VERSION ""

NS_ :

BS_:

BU_: TM

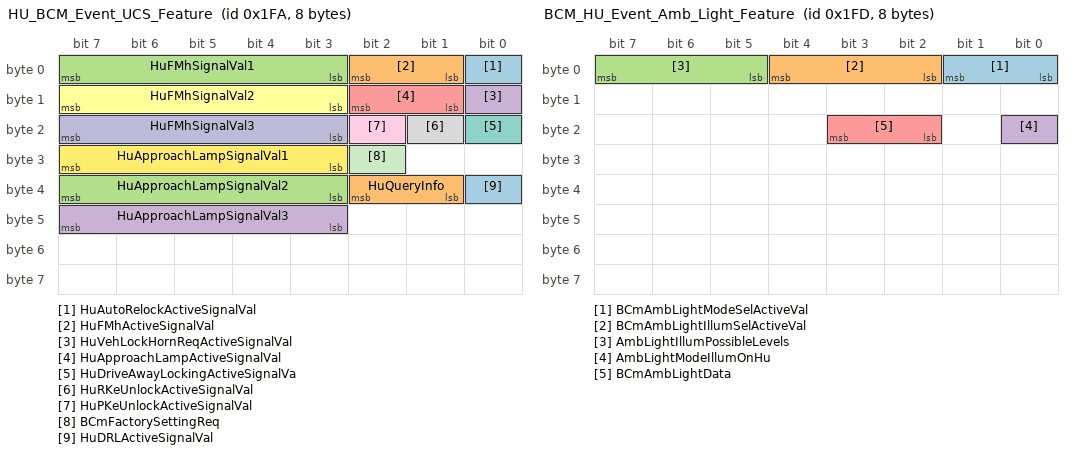
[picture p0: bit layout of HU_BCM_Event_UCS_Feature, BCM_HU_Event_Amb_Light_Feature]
BO_ 506 HU_BCM_Event_UCS_Feature: 8 Vector__XXX
 SG_ HuAutoRelockActiveSignalVal : 0|1@0+ (1,0) [0|1] ""  TM
 SG_ HuFMhActiveSignalVal : 2|2@0+ (1,0) [0|3] ""  TM
 SG_ HuFMhSignalVal1 : 7|5@0+ (10,0) [0|310] "Sec"  TM
 SG_ HuVehLockHornReqActiveSignalVal : 8|1@0+ (1,0) [0|1] ""  TM
 SG_ HuApproachLampActiveSignalVal : 10|2@0+ (1,0) [0|3] ""  TM
 SG_ HuFMhSignalVal2 : 15|5@0+ (10,0) [0|310] "Sec"  TM
 SG_ HuDriveAwayLockingActiveSignalVa : 16|1@0+ (1,0) [0|1] ""  TM
 SG_ HuRKeUnlockActiveSignalVal : 17|1@0+ (1,0) [0|1] ""  TM
 SG_ HuPKeUnlockActiveSignalVal : 18|1@0+ (1,0) [0|1] ""  TM
 SG_ HuFMhSignalVal3 : 23|5@0+ (10,0) [0|310] "Sec"  TM
 SG_ BCmFactorySettingReq : 26|1@0+ (1,0) [0|1] ""  TM
 SG_ HuApproachLampSignalVal1 : 31|5@0+ (10,0) [0|310] "Sec"  TM
 SG_ HuDRLActiveSignalVal : 32|1@0+ (1,0) [0|1] ""  TM
 SG_ HuQueryInfo : 34|2@0+ (1,0) [0|3] ""  TM
 SG_ HuApproachLampSignalVal2 : 39|5@0+ (10,0) [0|310] "Sec"  TM
 SG_ HuApproachLampSignalVal3 : 47|5@0+ (10,0) [0|310] "Sec"  TM

BO_ 508 HU_BCM_Event_Mood_Light_Feature: 8 Vector__XXX
 SG_ HuMoodLightAllAreaActiveValue : 0|1@0+ (1,0) [0|1] ""  TM
 SG_ HuMoodLightIllumSelActiveValue : 3|3@0+ (1,0) [0|7] ""  TM
 SG_ HuMoodLightActiveColourValue : 7|4@0+ (1,0) [0|15] ""  TM
 SG_ HuMoodLightRearAreaActiveValue : 8|1@0+ (1,0) [0|1] ""  TM
 SG_ HuMoodLightFrontRHAreaActiveValu : 9|1@0+ (1,0) [0|1] ""  TM
 SG_ HuMoodLightFloorConsoleAreaActiv : 10|1@0+ (1,0) [0|1] ""  TM
 SG_ HuMoodLightData : 12|2@0+ (1,0) [0|3] ""  TM
 SG_ HuMoodLightIllumPossibleLevels : 15|3@0+ (1,0) [0|7] ""  TM
 SG_ HuMoodLightHotMagentaColorSelOnH : 16|1@0+ (1,0) [0|1] ""  TM
 SG_ HuMoodLightGoldYellowColorSelOnH : 17|1@0+ (1,0) [0|1] ""  TM
 SG_ HuMoodLightFrenchLimeColorSelOnH : 18|1@0+ (1,0) [0|1] ""  TM
 SG_ HuMoodLightFrontLHAreaActiveValu : 19|1@0+ (1,0) [0|1] ""  TM
 SG_ HuMoodLightPossibleModes : 21|2@0+ (1,0) [0|3] ""  TM
 SG_ HuMoodLightActiveModeValue : 23|2@0+ (1,0) [0|3] ""  TM
 SG_ HuMoodLightPolarBrightWhiteColor : 24|1@0+ (1,0) [0|1] ""  TM
 SG_ HuMoodLightAeroBlueColorSelOnHU : 25|1@0+ (1,0) [0|1] ""  TM
 SG_ HuMoodLightPurpleColorSelOnHU : 26|1@0+ (1,0) [0|1] ""  TM
 SG_ HuMoodLightFluorescentGreenColor : 27|1@0+ (1,0) [0|1] ""  TM
 SG_ HuMoodLightCyanBlueColorSelOnHU : 28|1@0+ (1,0) [0|1] ""  TM
 SG_ HuMoodLightCoolBlueColorSelOnHU : 29|1@0+ (1,0) [0|1] ""  TM
 SG_ HuMoodLightIvoryOFFWhiteColorSel : 30|1@0+ (1,0) [0|1] ""  TM
 SG_ HuMoodLightIceBlueColorSelOnHU : 31|1@0+ (1,0) [0|1] ""  TM
 SG_ HuMoodLightTuscanRedColorSelOnHU : 32|1@0+ (1,0) [0|1] ""  TM
 SG_ HuMoodLightTealGreenColorSelOnHU : 33|1@0+ (1,0) [0|1] ""  TM
 SG_ HuMoodLightRubyRedColorSelOnHU : 34|1@0+ (1,0) [0|1] ""  TM
 SG_ HuMoodLightOrangeColorSelOnHU : 35|1@0+ (1,0) [0|1] ""  TM
 SG_ HuMoodLightPurpleTaupeSelOnHU : 36|1@0+ (1,0) [0|1] ""  TM

BO_ 509 BCM_HU_Event_Amb_Light_Feature: 8 Vector__XXX
 SG_ BCmAmbLightModeSelActiveVal : 1|2@0+ (1,0) [0|3] ""  TM
 SG_ BCmAmbLightIllumSelActiveVal : 4|3@0+ (1,0) [0|7] ""  TM
 SG_ AmbLightIllumPossibleLevels : 7|3@0+ (1,0) [0|7] ""  TM
 SG_ AmbLightModeIllumOnHu : 16|1@0+ (1,0) [0|1] ""  TM
 SG_ BCmAmbLightData : 19|2@0+ (1,0) [0|3] ""  TM

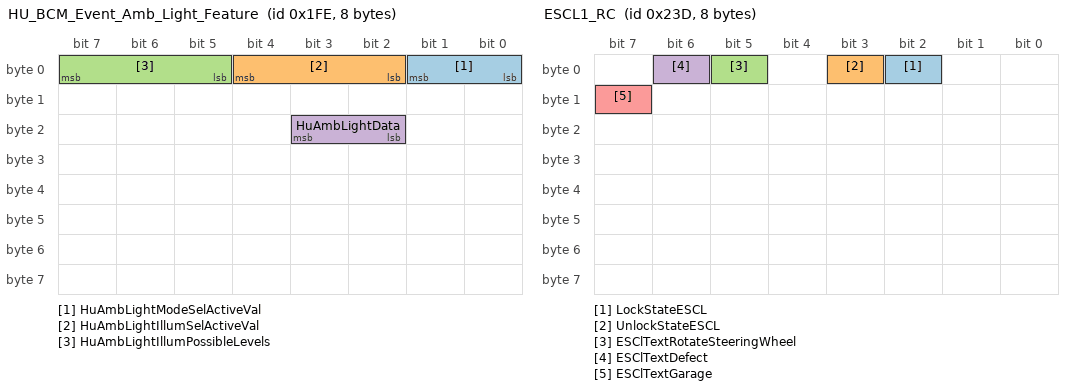
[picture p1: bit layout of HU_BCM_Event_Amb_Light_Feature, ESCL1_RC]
BO_ 510 HU_BCM_Event_Amb_Light_Feature: 8 Vector__XXX
 SG_ HuAmbLightModeSelActiveVal : 1|2@0+ (1,0) [0|3] ""  TM
 SG_ HuAmbLightIllumSelActiveVal : 4|3@0+ (1,0) [0|7] ""  TM
 SG_ HuAmbLightIllumPossibleLevels : 7|3@0+ (1,0) [0|7] ""  TM
 SG_ HuAmbLightData : 19|2@0+ (1,0) [0|3] ""  TM

BO_ 571 CCM_HU_Info: 8 Vector__XXX
 SG_ ColorThemeAutolearning : 54|1@0+ (1,0) [0|1] ""  TM
 SG_ ColorThemeCoDrvr : 50|3@0+ (1,0) [0|7] ""  TM
 SG_ ColorThemeDrvr : 53|3@0+ (1,0) [0|7] ""  TM
 SG_ CcmHuRearBlwrOnOffState : 56|1@0+ (1,0) [0|1] ""  TM
 SG_ CcmHuUserInterventionBeep : 62|1@0+ (1,0) [0|1] ""  TM
 SG_ AutoDefogState : 40|2@0+ (1,0) [0|3] ""  TM
 SG_ AutoDefogFeature : 32|1@0+ (1,0) [0|1] ""  TM
 SG_ CCmExpressCoolVoiceAlert : 61|3@0+ (1,0) [0|7] ""  TM
 SG_ CCmHuExpressCoolSwitchStatus : 63|1@0+ (1,0) [0|1] ""  TM
 SG_ CCmWindowUpDown : 58|2@0+ (1,0) [0|3] ""  TM
 SG_ CCmHuFanSpdStatus : 3|4@0+ (1,0) [0|15] ""  TM
 SG_ CCmHuDistribSwitchStatus : 6|3@0+ (1,0) [0|7] ""  TM
 SG_ CCmHuDualModeSwStatus : 7|1@0+ (1,0) [0|1] ""  TM
 SG_ CCmHuTempWhlStatusPass : 12|5@0+ (0.5,0) [0|31] "Deg C"  TM
 SG_ CCMHuFreshAirRecircSwitchStatus : 14|2@0+ (1,0) [0|3] ""  TM
 SG_ CCmHuAutoSwitchStatus : 15|1@0+ (1,0) [0|1] ""  TM
 SG_ CCmHuTempWhlStatus : 20|5@0+ (0.5,0) [0|31] "Deg C"  TM
 SG_ CCmHuEconModeSwitchStatus : 21|1@0+ (1,0) [0|1] ""  TM
 SG_ CCmHuMaxDefrstSwitchStatus : 22|1@0+ (1,0) [0|1] ""  TM
 SG_ CCmHuRearDefogSwitchStatus : 23|1@0+ (1,0) [0|1] ""  TM
 SG_ CCmHuTempWhlStatusDrvr : 28|5@0+ (0.5,0) [0|31] "Deg  C"  TM
 SG_ CCmHuAirConCompSwitchStatus : 29|1@0+ (1,0) [0|1] ""  TM
 SG_ CCmHuCtrlPnlStatus : 30|1@0+ (1,0) [0|1] ""  TM
 SG_ CCmHuChangeBit : 31|1@0+ (1,0) [0|1] ""  TM
 SG_ CCmHuUserInterventionStatusFlag : 37|5@0+ (1,0) [0|31] ""  TM
 SG_ CCmHuTempWhlStatusStatus : 39|2@0+ (1,0) [0|3] ""  TM
 SG_ CCmHuErrStatus : 41|1@0+ (1,0) [0|1] ""  TM
 SG_ CCmHuDualModeSwStatusStatus : 43|2@0+ (1,0) [0|3] ""  TM
 SG_ CCmHuTempWhlStatusPassStatus : 45|2@0+ (1,0) [0|3] ""  TM
 SG_ CCmHuTempWhlStatusDrvrStatus : 47|2@0+ (1,0) [0|3] ""  TM

BO_ 573 ESCL1_RC: 8 Vector__XXX
 SG_ LockStateESCL : 2|1@0+ (1,0) [0|1] ""  TM
 SG_ UnlockStateESCL : 3|1@0+ (1,0) [0|1] ""  TM
 SG_ ESClTextRotateSteeringWheel : 5|1@0+ (1,0) [0|1] ""  TM
 SG_ ESClTextDefect : 6|1@0+ (1,0) [0|1] ""  TM
 SG_ ESClTextGarage : 15|1@0+ (1,0) [0|1] ""  TM

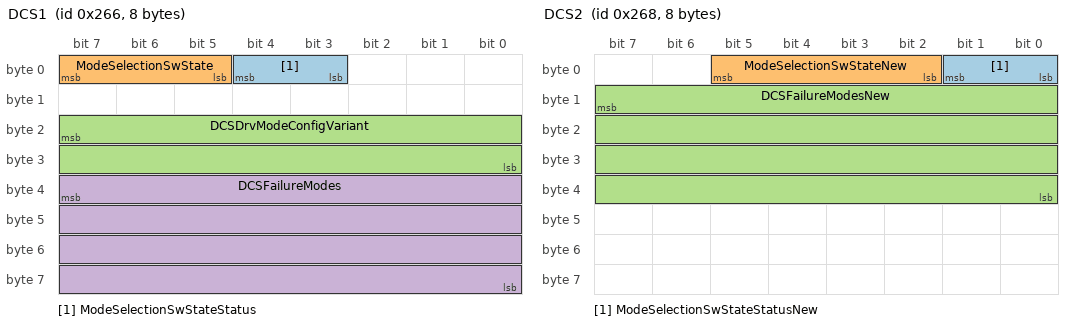
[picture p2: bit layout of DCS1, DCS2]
BO_ 614 DCS1: 8 Vector__XXX
 SG_ ModeSelectionSwStateStatus : 4|2@0+ (1,0) [0|3] ""  TM
 SG_ ModeSelectionSwState : 7|3@0+ (1,0) [0|7] ""  TM
 SG_ DCSDrvModeConfigVariant : 23|16@0+ (1,0) [0|65535] ""  TM
 SG_ DCSFailureModes : 39|32@0+ (1,0) [0|4294967295] ""  TM

BO_ 616 DCS2: 8 Vector__XXX
 SG_ ModeSelectionSwStateStatusNew : 1|2@0+ (1,0) [0|3] ""  TM
 SG_ ModeSelectionSwStateNew : 5|4@0+ (1,0) [0|15] ""  TM
 SG_ DCSFailureModesNew : 15|32@0- (1,0) [0|4294967295] ""  TM

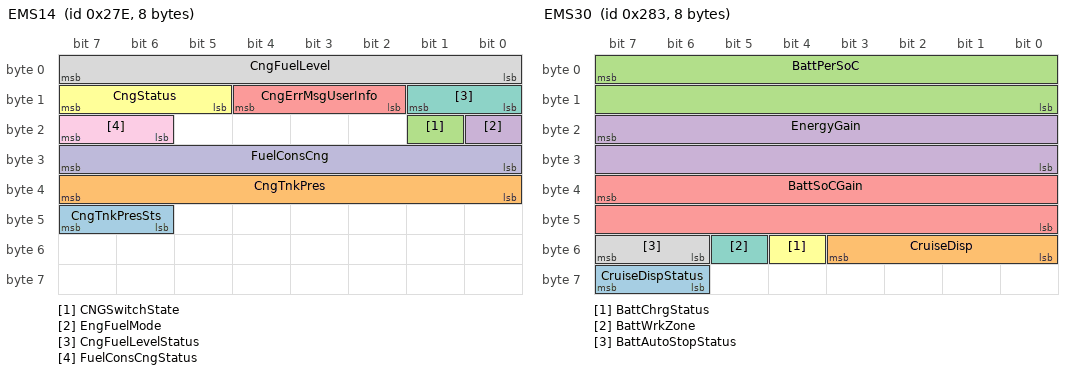
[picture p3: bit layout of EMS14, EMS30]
BO_ 638 EMS14: 8 Vector__XXX
 SG_ CngTnkPresSts : 47|2@0+ (1,0) [0|3] ""  TM
 SG_ CngTnkPres : 39|8@0+ (1,0) [0|250] "bar"  TM
 SG_ CNGSwitchState : 17|1@0+ (1,0) [0|1] ""  TM
 SG_ EngFuelMode : 16|1@0+ (1,0) [0|1] ""  TM
 SG_ CngErrMsgUserInfo : 12|3@0+ (1,0) [0|7] ""  TM
 SG_ CngStatus : 15|3@0+ (1,0) [0|7] ""  TM
 SG_ CngFuelLevelStatus : 9|2@0+ (1,0) [0|3] ""  TM
 SG_ CngFuelLevel : 7|8@0+ (100,0) [0|25500] "gm"  TM
 SG_ FuelConsCngStatus : 23|2@0+ (1,0) [0|3] ""  TM
 SG_ FuelConsCng : 31|8@0+ (100,0) [0|25500] "mg/100ms"  TM

BO_ 640 EMS2: 8 Vector__XXX
 SG_ EngCrsCntrlModeNew : 39|4@0+ (1,0) [0|15] ""  TM
 SG_ EngSpd_EMS : 7|14@0+ (1,0) [0|16383] "rpm"  TM
 SG_ EngSpd_EMS_Status : 9|2@0+ (1,0) [0|3] ""  TM
 SG_ FuelCons : 23|8@0+ (78.8519,0) [0|20107.2345] "mm^3/100ms"  TM
 SG_ ClntTemp : 31|8@0+ (1,-40) [-40|215] "deg"  TM
 SG_ EngineOilPrLamp : 33|2@0+ (1,0) [0|3] ""  TM
 SG_ FilterClLamp : 35|2@0+ (1,0) [0|3] ""  TM
 SG_ BattChrgLampStatus : 41|2@0+ (1,0) [0|3] ""  TM
 SG_ ClntTempStatus : 43|2@0+ (1,0) [0|3] ""  TM
 SG_ GlowPlugLampState : 45|2@0+ (1,0) [0|3] ""  TM
 SG_ EngineOilPrLampStatus : 47|2@0+ (1,0) [0|3] ""  TM
 SG_ WIfLampState : 49|2@0+ (1,0) [0|3] ""  TM
 SG_ ECmBackdoormode : 51|2@0+ (1,0) [0|3] ""  TM
 SG_ FuelConsStatus : 53|2@0+ (1,0) [0|3] ""  TM
 SG_ BattChrgLampState : 55|2@0+ (1,0) [0|3] ""  TM
 SG_ DPfState : 58|2@0+ (1,0) [0|3] ""  TM
 SG_ ClntTempHigh : 60|2@0+ (1,0) [0|3] ""  TM
 SG_ ImmoStatus : 61|1@0+ (1,0) [0|1] ""  TM
 SG_ MiLampState : 63|2@0+ (1,0) [0|3] ""  TM

BO_ 643 EMS30: 8 Vector__XXX
 SG_ CruiseDispStatus : 63|2@0+ (1,0) [0|3] ""  TM
 SG_ CruiseDisp : 51|4@0+ (1,0) [0|15] ""  TM
 SG_ BattPerSoC : 7|16@0+ (0.1,0) [0|150] "%"  TM
 SG_ EnergyGain : 23|16@0+ (0.1,-1000) [-1000|1000] "kW/h"  TM
 SG_ BattSoCGain : 39|16@0+ (0.1,0) [0|150] "%"  TM
 SG_ BattChrgStatus : 52|1@0+ (1,0) [0|1] ""  TM
 SG_ BattWrkZone : 53|1@0+ (1,0) [0|1] ""  TM
 SG_ BattAutoStopStatus : 55|2@0+ (1,0) [0|3] ""  TM

BO_ 644 EMS4: 8 Vector__XXX
 SG_ AcCmprPr : 7|12@0+ (1,0) [0|3570] "kPa"  TM
 SG_ AcCmprOverPrStatus : 9|2@0+ (1,0) [0|3] ""  TM
 SG_ AcCmprPrStatus : 11|2@0+ (1,0) [0|3] ""  TM
 SG_ EngEmission : 18|3@0+ (1,0) [0|7] ""  TM
 SG_ TxmnVariant : 20|2@0+ (1,0) [0|3] ""  TM
 SG_ AcCmprStatus : 21|1@0+ (1,0) [0|1] ""  TM
 SG_ RadFanStatus : 22|1@0+ (1,0) [0|1] ""  TM
 SG_ AcCmprOverPrActive : 23|1@0+ (1,0) [0|1] ""  TM
 SG_ EMSInitDrvModeConfig : 26|3@0+ (1,0) [0|7] ""  TM
 SG_ BattVoltEMsStatus : 28|2@0+ (1,0) [0|3] ""  TM
 SG_ EngLimpHomeMode : 31|3@0+ (1,0) [0|7] ""  TM
 SG_ BattVoltEMS : 39|8@0+ (0.1,0) [0|25.5] "Volts"  TM
 SG_ AtmospPrStatus : 41|2@0+ (1,0) [0|3] ""  TM
 SG_ AcCmprUnderPrActive : 42|1@0+ (1,0) [0|1] ""  TM
 SG_ AcCmprUnderPrStatus : 44|2@0+ (1,0) [0|3] ""  TM
 SG_ EngVariant : 46|2@0+ (1,0) [0|3] ""  TM
 SG_ AtmospPr : 55|8@0+ (2,0) [0|510] "kpa"  TM
 SG_ ModeChangeTxtEMS : 57|2@0+ (1,0) [0|3] ""  TM
 SG_ EngCrsCntrlMode : 60|3@0+ (1,0) [0|7] ""  TM

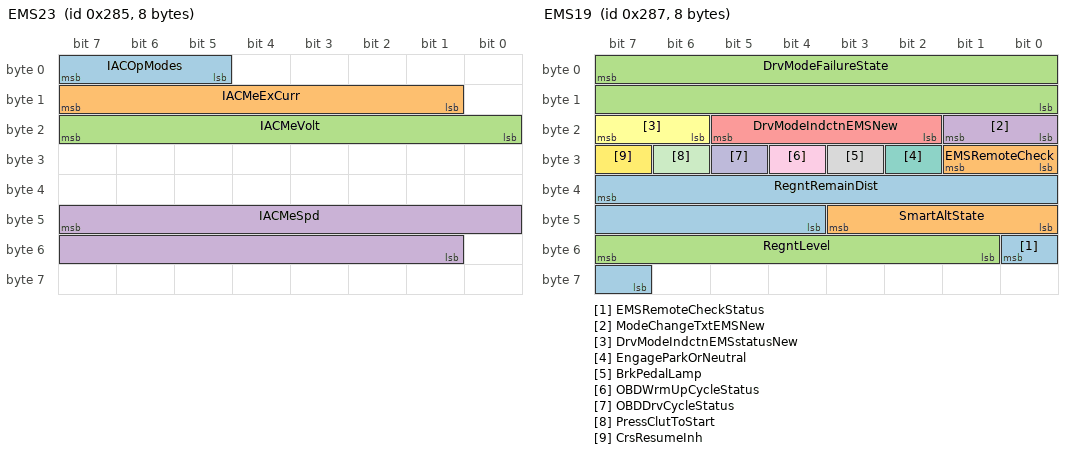
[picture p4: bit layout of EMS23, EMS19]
BO_ 645 EMS23: 8 Vector__XXX
 SG_ IACOpModes : 7|3@0+ (1,0) [0|7] ""  TM
 SG_ IACMeExCurr : 15|7@0+ (0.1,0) [0|12.7] "A"  TM
 SG_ IACMeVolt : 23|8@0+ (0.1,0) [0|25.5] "Volt"  TM
 SG_ IACMeSpd : 47|15@0+ (1,0) [0|32767] "rpm"  TM

BO_ 646 EMS5: 8 Vector__XXX
 SG_ UserSpdLim : 7|8@0+ (1,0) [0|255] "km/h"  TM
 SG_ UserSpdLimLamp : 8|1@0+ (1,0) [0|1] ""  TM
 SG_ UserSpdLimFault : 10|2@0+ (1,0) [0|3] ""  TM
 SG_ UserSpdLimStatus : 12|2@0+ (1,0) [0|3] ""  TM
 SG_ EngStatus : 15|3@0+ (1,0) [0|7] ""  TM
 SG_ CeLampState : 18|2@0+ (1,0) [0|3] ""  TM
 SG_ StaterProhibitionDelay : 19|1@0+ (1,0) [0|1] ""  TM
 SG_ StarterControlState : 21|2@0+ (1,0) [0|3] ""  TM
 SG_ UserSpdLimState : 23|2@0+ (1,0) [0|3] ""  TM
 SG_ SFCActiveEMS : 25|2@0+ (1,0) [0|3] ""  TM
 SG_ DrvModeIndctnEMSstatus : 27|2@0+ (1,0) [0|3] ""  TM
 SG_ CruiseSpdLamp : 29|2@0+ (1,0) [0|3] ""  TM
 SG_ StarterControlStatus : 31|2@0+ (1,0) [0|3] ""  TM
 SG_ CurrGearEms : 35|4@0+ (1,0) [0|15] ""  TM
 SG_ CruiseSpdFault : 37|2@0+ (1,0) [0|3] ""  TM
 SG_ CruiseSpdStatus : 39|2@0+ (1,0) [0|3] ""  TM
 SG_ CruiseSpd : 47|8@0+ (1,0) [0|255] "Km/h"  TM
 SG_ CurrGearEmsStatus : 50|2@0+ (1,0) [0|3] ""  TM
 SG_ GearShiftIndctnEmsStatus : 52|2@0+ (1,0) [0|3] ""  TM
 SG_ GearShiftIndctnEms : 55|3@0+ (1,0) [0|7] ""  TM
 SG_ CruiseSwitchstate : 57|2@0+ (1,0) [0|3] ""  TM
 SG_ CruiseSwitchstateStatus : 59|2@0+ (1,0) [0|3] ""  TM
 SG_ DrvModeIndctnEMS : 63|4@0+ (1,0) [0|15] ""  TM

BO_ 647 EMS19: 8 Vector__XXX
 SG_ EMSRemoteCheckStatus : 48|2@0+ (1,0) [0|3] ""  TM
 SG_ EMSRemoteCheck : 25|2@0+ (1,0) [0|3] ""  TM
 SG_ DrvModeFailureState : 7|16@0+ (1,0) [0|32768] ""  TM
 SG_ ModeChangeTxtEMSNew : 17|2@0+ (1,0) [0|3] ""  TM
 SG_ DrvModeIndctnEMSNew : 21|4@0+ (1,0) [0|15] ""  TM
 SG_ DrvModeIndctnEMSstatusNew : 23|2@0+ (1,0) [0|3] ""  TM
 SG_ EngageParkOrNeutral : 26|1@0+ (1,0) [0|1] ""  TM
 SG_ BrkPedalLamp : 27|1@0+ (1,0) [0|1] ""  TM
 SG_ OBDWrmUpCycleStatus : 28|1@0+ (1,0) [0|1] ""  TM
 SG_ OBDDrvCycleStatus : 29|1@0+ (1,0) [0|1] ""  TM
 SG_ PressClutToStart : 30|1@0+ (1,0) [0|1] ""  TM
 SG_ CrsResumeInh : 31|1@0+ (1,0) [0|1] ""  TM
 SG_ RegntRemainDist : 39|12@0+ (1,0) [0|4095] ""  TM
 SG_ SmartAltState : 43|4@0+ (1,0) [0|15] ""  TM
 SG_ RegntLevel : 55|7@0+ (1,0) [0|100] "%"  TM

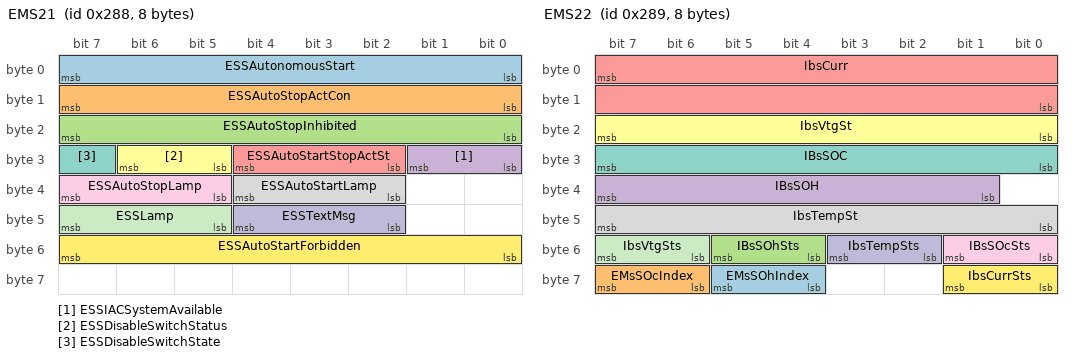
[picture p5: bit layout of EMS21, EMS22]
BO_ 648 EMS21: 8 Vector__XXX
 SG_ ESSAutonomousStart : 7|8@0+ (1,0) [0|255] ""  TM
 SG_ ESSAutoStopActCon : 15|8@0+ (1,0) [0|255] ""  TM
 SG_ ESSAutoStopInhibited : 23|8@0+ (1,0) [0|255] ""  TM
 SG_ ESSIACSystemAvailable : 25|2@0+ (1,0) [0|3] ""  TM
 SG_ ESSAutoStartStopActSt : 28|3@0+ (1,0) [0|7] ""  TM
 SG_ ESSDisableSwitchStatus : 30|2@0+ (1,0) [0|3] ""  TM
 SG_ ESSDisableSwitchState : 31|1@0+ (1,0) [0|1] ""  TM
 SG_ ESSAutoStartLamp : 36|3@0+ (1,0) [0|7] ""  TM
 SG_ ESSAutoStopLamp : 39|3@0+ (1,0) [0|7] ""  TM
 SG_ ESSTextMsg : 44|3@0+ (1,0) [0|7] ""  TM
 SG_ ESSLamp : 47|3@0+ (1,0) [0|7] ""  TM
 SG_ ESSAutoStartForbidden : 55|8@0+ (1,0) [0|255] ""  TM

BO_ 649 EMS22: 8 Vector__XXX
 SG_ EMsSOhIndex : 61|2@0+ (1,0) [0|3] ""  TM
 SG_ EMsSOcIndex : 63|2@0+ (1,0) [0|3] ""  TM
 SG_ IBsSOhSts : 53|2@0+ (1,0) [0|3] ""  TM
 SG_ IBsSOH : 39|7@0+ (1,0) [0|100] ""  TM
 SG_ IbsCurr : 7|16@0+ (0.0625,-2048) [-1500|1500] "A"  TM
 SG_ IbsVtgSt : 23|8@0+ (0.0627,3) [3|18.9885] "Volt"  TM
 SG_ IBsSOC : 31|8@0+ (1,0) [0|100] "%"  TM
 SG_ IbsTempSt : 47|8@0+ (1,-40) [-40|215] "deg"  TM
 SG_ IBsSOcSts : 49|2@0+ (1,0) [0|3] ""  TM
 SG_ IbsTempSts : 51|2@0+ (1,0) [0|3] ""  TM
 SG_ IbsVtgSts : 55|2@0+ (1,0) [0|3] ""  TM
 SG_ IbsCurrSts : 57|2@0+ (1,0) [0|3] ""  TM

BO_ 650 EPAS1: 8 Vector__XXX
 SG_ EPAsStatus : 1|2@0+ (1,0) [0|3] ""  TM

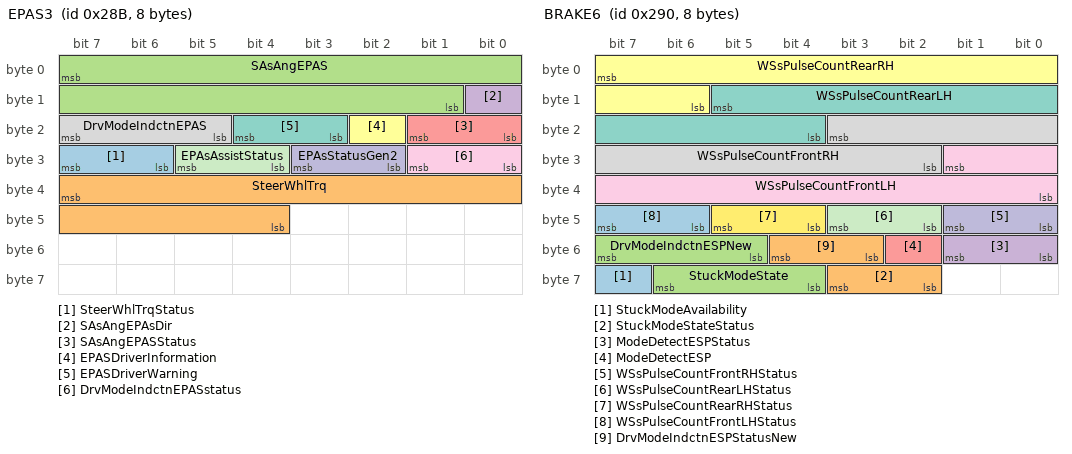
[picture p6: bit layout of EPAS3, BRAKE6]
BO_ 651 EPAS3: 8 Vector__XXX
 SG_ SteerWhlTrqStatus : 31|2@0+ (1,0) [0|3] ""  TM
 SG_ SteerWhlTrq : 39|12@0+ (0.01,-20.5) [-20.5|20.45] "Nm"  TM
 SG_ SAsAngEPAS : 7|15@0+ (0.04375,0) [0|1433.55625] " deg"  TM
 SG_ SAsAngEPAsDir : 8|1@0+ (1,0) [0|1] ""  TM
 SG_ SAsAngEPASStatus : 17|2@0+ (1,0) [0|3] ""  TM
 SG_ EPASDriverInformation : 18|1@0+ (1,0) [0|1] ""  TM
 SG_ EPASDriverWarning : 20|2@0+ (1,0) [0|3] ""  TM
 SG_ DrvModeIndctnEPAS : 23|3@0+ (1,0) [0|7] ""  TM
 SG_ DrvModeIndctnEPASstatus : 25|2@0+ (1,0) [0|3] ""  TM
 SG_ EPAsStatusGen2 : 27|2@0+ (1,0) [0|3] ""  TM
 SG_ EPAsAssistStatus : 29|2@0+ (1,0) [0|3] ""  TM

BO_ 652 EPAS5: 8 Vector__XXX
 SG_ SteerAngEPAsCalibration : 7|1@0+ (1,0) [0|1] ""  TM

BO_ 656 BRAKE6: 8 Vector__XXX
 SG_ StuckModeAvailability : 63|1@0+ (1,0) [0|1] ""  TM
 SG_ StuckModeStateStatus : 59|2@0+ (1,0) [0|3] ""  TM
 SG_ StuckModeState : 62|3@0+ (1,0) [0|7] ""  TM
 SG_ ModeDetectESPStatus : 49|2@0+ (1,0) [0|3] ""  TM
 SG_ ModeDetectESP : 50|1@0+ (1,0) [0|1] ""  TM
 SG_ WSsPulseCountRearRH : 7|10@0+ (1,0) [0|1023] "Pulse"  TM
 SG_ WSsPulseCountRearLH : 13|10@0+ (1,0) [0|1023] "Pulse"  TM
 SG_ WSsPulseCountFrontRH : 19|10@0+ (1,0) [0|1023] "Pulse"  TM
 SG_ WSsPulseCountFrontLH : 25|10@0+ (1,0) [0|1023] "Pulse"  TM
 SG_ WSsPulseCountFrontRHStatus : 41|2@0+ (1,0) [0|3] ""  TM
 SG_ WSsPulseCountRearLHStatus : 43|2@0+ (1,0) [0|3] ""  TM
 SG_ WSsPulseCountRearRHStatus : 45|2@0+ (1,0) [0|3] ""  TM
 SG_ WSsPulseCountFrontLHStatus : 47|2@0+ (1,0) [0|3] ""  TM
 SG_ DrvModeIndctnESPStatusNew : 52|2@0+ (1,0) [0|3] ""  TM
 SG_ DrvModeIndctnESPNew : 55|3@0+ (1,0) [0|7] ""  TM

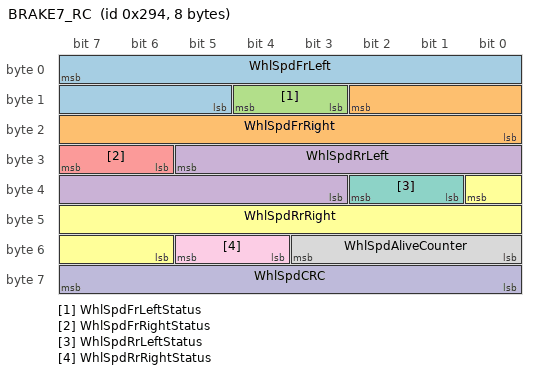
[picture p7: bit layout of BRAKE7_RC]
BO_ 660 BRAKE7_RC: 8 Vector__XXX
 SG_ WhlSpdFrLeft : 7|11@0+ (2,0) [0|4094] "rpm"  TM
 SG_ WhlSpdFrRight : 10|11@0+ (2,0) [0|4094] "rpm"  TM
 SG_ WhlSpdFrLeftStatus : 12|2@0+ (1,0) [0|3] ""  TM
 SG_ WhlSpdRrLeft : 29|11@0+ (2,0) [0|4094] "rpm"  TM
 SG_ WhlSpdFrRightStatus : 31|2@0+ (1,0) [0|3] ""  TM
 SG_ WhlSpdRrRight : 32|11@0+ (2,0) [0|4094] "rpm"  TM
 SG_ WhlSpdRrLeftStatus : 34|2@0+ (1,0) [0|3] ""  TM
 SG_ WhlSpdAliveCounter : 51|4@0+ (1,0) [0|15] ""  TM
 SG_ WhlSpdRrRightStatus : 53|2@0+ (1,0) [0|3] ""  TM
 SG_ WhlSpdCRC : 63|8@0+ (1,0) [0|255] ""  TM

CM_ SG_ 506 HuAutoRelockActiveSignalVal "Active Value for Vehicle Auto Relock Feature";
CM_ SG_ 506 HuFMhActiveSignalVal "Active value for Follow Me Home feature";
CM_ SG_ 506 HuFMhSignalVal1 "1st Possible value for Follow Me Home Feature";
CM_ SG_ 506 HuVehLockHornReqActiveSignalVal "Active Value for Vehicle Lock Horn Request feature";
CM_ SG_ 506 HuApproachLampActiveSignalVal "Active value for Approach Lamp Active feature";
CM_ SG_ 506 HuFMhSignalVal2 "2ND Possible value for Follow Me Home Feature";
CM_ SG_ 506 HuDriveAwayLockingActiveSignalVa "Active Value for Vehicle Drive Away Feature";
CM_ SG_ 506 HuRKeUnlockActiveSignalVal "Active Value for Vehicle Unlock with RKE Feature";
CM_ SG_ 506 HuPKeUnlockActiveSignalVal "Active Value for Vehicle Unlock with PKE Feature";
CM_ SG_ 506 HuFMhSignalVal3 "3rd Possible value for Follow Me Home Feature";
CM_ SG_ 506 BCmFactorySettingReq "Request from HU to BCM to restore factory settings.";
CM_ SG_ 506 HuApproachLampSignalVal1 "1st Possible value for Approach Lamp Feature";
CM_ SG_ 506 HuDRLActiveSignalVal "Active Value for DRL  Feature";
CM_ SG_ 506 HuQueryInfo "HU ask BCM to send UCS values when not received after IGN ON.";
CM_ SG_ 506 HuApproachLampSignalVal2 "2nd Possible value for Approach Lamp Feature";
CM_ SG_ 506 HuApproachLampSignalVal3 "3rd Possible value for Approach Lamp Feature";
CM_ BO_ 508 "Event Message from HU to BCM for Mood Lighting feature";
CM_ SG_ 508 HuMoodLightAllAreaActiveValue "Current status of All area location selection from HU to BCM";
CM_ SG_ 508 HuMoodLightIllumSelActiveValue "Current Mood light illumination active value from HU to BCM";
CM_ SG_ 508 HuMoodLightActiveColourValue "Current Mood Light active value from HU to BCM";
CM_ SG_ 508 HuMoodLightRearAreaActiveValue "Current status of Rear area location selection from HU to BCM";
CM_ SG_ 508 HuMoodLightFrontRHAreaActiveValu "Current status of Driver area location selection from HU to BCM";
CM_ SG_ 508 HuMoodLightFloorConsoleAreaActiv "Current status of Floor Console area location selection from HU to BCM";
CM_ SG_ 508 HuMoodLightData "HU sends Mood Light Data frame or give acknowledgement to HU";
CM_ SG_ 508 HuMoodLightIllumPossibleLevels "Mood light number of illumination levels to be send by HU to BCM";
CM_ SG_ 508 HuMoodLightHotMagentaColorSelOnH "Mood light Hot Magenta colour selection on HU sent by HU";
CM_ SG_ 508 HuMoodLightGoldYellowColorSelOnH "Mood light Gold Yellow colour selection on HU sent by HU";
CM_ SG_ 508 HuMoodLightFrenchLimeColorSelOnH "Mood light French Lime colour selection on HU sent by HU";
CM_ SG_ 508 HuMoodLightFrontLHAreaActiveValu "Current status of Co-Driver area location selection from HU to BCM";
CM_ SG_ 508 HuMoodLightPossibleModes "Mood light possible modes from HU to BCM";
CM_ SG_ 508 HuMoodLightActiveModeValue "Mood light active mode from HU to BCM
";
CM_ SG_ 508 HuMoodLightPolarBrightWhiteColor "Mood light polar colour selection on HU sent by HU";
CM_ SG_ 508 HuMoodLightAeroBlueColorSelOnHU "Mood light Aero Blue colour selection on HU sent by HU";
CM_ SG_ 508 HuMoodLightPurpleColorSelOnHU "Mood light purple colour selection on HU sent by HU";
CM_ SG_ 508 HuMoodLightFluorescentGreenColor "Mood light Fluroscent colour selection on HU sent by HU";
CM_ SG_ 508 HuMoodLightCyanBlueColorSelOnHU "Mood light Cyan Blue colour selection on HU sent by HU";
CM_ SG_ 508 HuMoodLightCoolBlueColorSelOnHU "Mood light Cool Blue colour selection on HU sent by HU";
CM_ SG_ 508 HuMoodLightIvoryOFFWhiteColorSel "Mood light Ivory colour selection on HU sent by HU";
CM_ SG_ 508 HuMoodLightIceBlueColorSelOnHU "Mood light Ice Blue colour selection on HU sent by HU";
CM_ SG_ 508 HuMoodLightTuscanRedColorSelOnHU "Mood light Tuscan Red colour selection on HU sent by HU";
CM_ SG_ 508 HuMoodLightTealGreenColorSelOnHU "Mood light Teal Green colour selection on HU sent by HU";
CM_ SG_ 508 HuMoodLightRubyRedColorSelOnHU "Mood light ruby colour selection on HU sent by HU";
CM_ SG_ 508 HuMoodLightOrangeColorSelOnHU "Mood light Orange colour selection on HU sent by HU";
CM_ SG_ 508 HuMoodLightPurpleTaupeSelOnHU "Mood light Purple Taupe colour selection on HU sent by HU";
CM_ SG_ 509 BCmAmbLightModeSelActiveVal "Current Ambient light mode from BCM to HU";
CM_ SG_ 509 BCmAmbLightIllumSelActiveVal "Current Ambient light illumination from BCM to HU";
CM_ SG_ 509 AmbLightIllumPossibleLevels "Ambient Light Number of illumination levels  to be displayed on HU send by BCM";
CM_ SG_ 509 AmbLightModeIllumOnHu "Mode and Illumination Display on HU send by BCM";
CM_ SG_ 509 BCmAmbLightData "BCM sends ambient light data frame or give acknowledgement to HU.";
CM_ SG_ 510 HuAmbLightModeSelActiveVal "Current Ambient light illumination from HU to BCM";
CM_ SG_ 510 HuAmbLightIllumSelActiveVal "Current Ambient light illumination from HU to BCM.";
CM_ SG_ 510 HuAmbLightIllumPossibleLevels "Current Ambient light illumination possible values  from HU to BCM.";
CM_ SG_ 510 HuAmbLightData "HU sends ambient light user changed data or give acknowledgement to BCM.";
CM_ SG_ 571 ColorThemeAutolearning "This signal will be used by HU to determine whether said feature is available or not";
CM_ SG_ 571 ColorThemeCoDrvr "Gives perticular band of color based on co-driver side ERL level";
CM_ SG_ 571 ColorThemeDrvr "Gives perticular band of color based on driver side ERL level";
CM_ SG_ 571 CcmHuRearBlwrOnOffState "ON/OFF status of Rear Blower to HU";
CM_ SG_ 571 CcmHuUserInterventionBeep "Audio Beep request for the user intervention on touched CCH panel.";
CM_ SG_ 571 AutoDefogState "This signal indicates the state/present condition of Auto defog function";
CM_ SG_ 571 AutoDefogFeature "This signal explains the status of Auto Defog feature implementation";
CM_ SG_ 571 CCmExpressCoolVoiceAlert "Indicates voice alert based on action needed for express cooling functionality";
CM_ SG_ 571 CCmHuExpressCoolSwitchStatus "Indicates whether the Express cooling feature is ON or OFF";
CM_ SG_ 571 CCmWindowUpDown "Indicates whether to make window Up / Down ";
CM_ SG_ 571 CCmHuFanSpdStatus "Indicates the speed of the fan";
CM_ SG_ 571 CCmHuDistribSwitchStatus "Indicates the different distribution modes";
CM_ SG_ 571 CCmHuDualModeSwStatus "Indicates whether the dual mode is ON or OFF";
CM_ SG_ 571 CCmHuTempWhlStatusPass "Indicates the left temperature value in Deg(Physical value range shall be considered as LO,16-30,HI)";
CM_ SG_ 571 CCMHuFreshAirRecircSwitchStatus "Indicates the different values of fresh air recirculation mode";
CM_ SG_ 571 CCmHuAutoSwitchStatus "Indicates whether the Auto mode is ON or OFF";
CM_ SG_ 571 CCmHuTempWhlStatus "Indicates the temperature value in Deg(Physical value range shall be considered as LO,16-30,HI)";
CM_ SG_ 571 CCmHuEconModeSwitchStatus "Indicates whether the Economy AC is ON or OFF";
CM_ SG_ 571 CCmHuMaxDefrstSwitchStatus "Indicates whether the maximum defrost control is ON or OFF";
CM_ SG_ 571 CCmHuRearDefogSwitchStatus "Indicates whether the rear defog control is ON or OFF";
CM_ SG_ 571 CCmHuTempWhlStatusDrvr "Indicates the right temperature value Deg(Physical value range shall be considered as LO,16-30,HI)";
CM_ SG_ 571 CCmHuAirConCompSwitchStatus "Indicates whether the AC is ON or OFF";
CM_ SG_ 571 CCmHuCtrlPnlStatus "Indicates whether the control panel is ON or OFF";
CM_ SG_ 571 CCmHuChangeBit "change bit";
CM_ SG_ 571 CCmHuUserInterventionStatusFlag "Indicates which HVAC control user has operated";
CM_ SG_ 571 CCmHuTempWhlStatusStatus "Indicates the status of the temperature knob";
CM_ SG_ 571 CCmHuErrStatus "CCM Switched Off due to detected failure  Evap Temp  Sens- STB or o/p EvapTemp Sens-STG  Air Distrib Drive Motor - Actuator stuck Air Distrib Drive Motor Line - STB/STG  Air Distri Drv Motor  Line -  STG Air Distrib Drive Motor Drive Line - Op";
CM_ SG_ 571 CCmHuDualModeSwStatusStatus "status information ";
CM_ SG_ 571 CCmHuTempWhlStatusPassStatus "Indicates the status of the Passenger temperature knob";
CM_ SG_ 571 CCmHuTempWhlStatusDrvrStatus "Indicates the status of the Driver temperature knob";
CM_ SG_ 573 LockStateESCL "The current locking state of the ESCL";
CM_ SG_ 573 UnlockStateESCL "The current unlocking state of the ESCL";
CM_ SG_ 573 ESClTextRotateSteeringWheel "Signal driver to rotate steering wheel";
CM_ SG_ 573 ESClTextDefect "ESCL function defect";
CM_ SG_ 573 ESClTextGarage "ESCL function defect";
CM_ SG_ 614 ModeSelectionSwStateStatus "Information is used to display the drive mode status information";
CM_ SG_ 614 ModeSelectionSwState "Information is used to display the drive modes to EMS and ABS/ ESP";
CM_ SG_ 614 DCSDrvModeConfigVariant "This is bit wise encoded signal.
Pl refer the IC function net v7.9 or DCS function net v6.6 for the bit wise description";
CM_ SG_ 616 ModeSelectionSwStateStatusNew "Information is used to display the drive mode status information";
CM_ SG_ 616 ModeSelectionSwStateNew "Information is used to display the drive modes to EMS and ABS/ ESP";
CM_ SG_ 616 DCSFailureModesNew "Indicates the Failure Modes in DCS, Refer function net for the value table";
CM_ SG_ 638 CngTnkPresSts "cng tank pressure signal status";
CM_ SG_ 638 CngTnkPres "cng tank pressure";
CM_ SG_ 638 CNGSwitchState "Signal will shall indicate the CNG mode selector switch state : Gasoline/CNG";
CM_ SG_ 638 EngFuelMode "Engine fuel mode";
CM_ SG_ 638 CngErrMsgUserInfo "ErrorMessages&UserInformation  ";
CM_ SG_ 638 CngStatus "CNG telltale Indication on IC";
CM_ SG_ 638 CngFuelLevel "This information is used   to display or indicate the CNG Fuel level Calculated with CNG tank pressure value ";
CM_ SG_ 638 FuelConsCngStatus "It indicates CNG Fuel consumption signal status information";
CM_ SG_ 638 FuelConsCng "This information is a cumultive fuel consumed over defined period, by the engine &  used   to calculate the mileage and display";
CM_ SG_ 640 EngCrsCntrlModeNew "Indicates the cruise Control Mode";
CM_ SG_ 640 EngSpd_EMS "crank shaft speed of engine";
CM_ SG_ 640 EngSpd_EMS_Status "crank shaft speed of engine,Status info";
CM_ SG_ 640 FuelCons "Fuel consumption";
CM_ SG_ 640 ClntTemp "Engine coolant temperature
";
CM_ SG_ 640 EngineOilPrLamp "This information is used   to display or indicate that Engine Oil pressure Lamp in ON /OFF or Blinking";
CM_ SG_ 640 FilterClLamp "This information is used to display or indicate the vehicle related malfunction state.";
CM_ SG_ 640 BattChrgLampStatus "Battery Charging Lamp status";
CM_ SG_ 640 ClntTempStatus "Engine coolant temperature, status
";
CM_ SG_ 640 GlowPlugLampState "Glow plug lamp state; it is always set to off for non-diesel applications";
CM_ SG_ 640 EngineOilPrLampStatus "Engine Oil Pressure Lampp status";
CM_ SG_ 640 WIfLampState "This information is used   to display or indicate the presence of water in fuel 
";
CM_ SG_ 640 ECmBackdoormode "This information is passed on by EMS when Engine start is allowed bypassing Immobilzer";
CM_ SG_ 640 FuelConsStatus "Fuel Consumption, Status
";
CM_ SG_ 640 BattChrgLampState "This information is used   to display or indicate that battery Charging lamp status is ON /Off";
CM_ SG_ 640 DPfState "Indicate diesel particular filter lamp state";
CM_ SG_ 640 ClntTempHigh "This information is used   to display or indicate to the driver that the coolant temp is high  ";
CM_ SG_ 640 ImmoStatus "Immobiliser Authentication status info by EMS ";
CM_ SG_ 640 MiLampState "This information is used   to display or indicate the engine malfunction state ";
CM_ SG_ 643 CruiseDispStatus "Status signal for Cruise Disp";
CM_ SG_ 643 CruiseDisp "Displays Cruise Disp State";
CM_ SG_ 643 BattPerSoC "Percentage Battery SOC";
CM_ SG_ 643 EnergyGain "Electric energy gained in current vehicle run for display";
CM_ SG_ 643 BattSoCGain "Display for SoC gained for current vehicle run";
CM_ SG_ 643 BattChrgStatus "Battery Working Zone information";
CM_ SG_ 643 BattWrkZone "Battery Working Zone information";
CM_ SG_ 643 BattAutoStopStatus "Battery status for Auto Stop & Start";
CM_ SG_ 644 AcCmprPr "Required for AC Diagnostic,If this info not available problem could be in garage,AC is not working,but no diagnostic info available";
CM_ SG_ 644 AcCmprOverPrStatus "AC compressor over pressure, status;
Quality/status information to ACCmprOverPr_Active signal";
CM_ SG_ 644 AcCmprPrStatus "AC compressor pressure, status";
CM_ SG_ 644 EngEmission "informs whether Vehicle is certified for which variant";
CM_ SG_ 644 TxmnVariant "informs tranmission type";
CM_ SG_ 644 AcCmprStatus "This signal is used to cycle the compressor and diagnostic";
CM_ SG_ 644 RadFanStatus "this signal give info about Radiator Fan is Off or ON";
CM_ SG_ 644 AcCmprOverPrActive "AC compressor over pressure active;
Indicates, whether over-pressure on AC compressor is detected or not";
CM_ SG_ 644 EMSInitDrvModeConfig "Default drive Mode Configuration Signal";
CM_ SG_ 644 BattVoltEMsStatus "Battery voltage evaluated by EMS, status";
CM_ SG_ 644 EngLimpHomeMode "Describes Engine running normal or in limp home mode condition";
CM_ SG_ 644 BattVoltEMS "Battery voltage evaluated by EMS";
CM_ SG_ 644 AtmospPrStatus "Atmospheric  pressure, status";
CM_ SG_ 644 AcCmprUnderPrActive "AC compressor under pressure active indicates, whether under-pressure on AC compressor is detected or not.";
CM_ SG_ 644 AcCmprUnderPrStatus "AC compressor under pressure, status quality status information to Quality/ status iformation to ACCmprUnderPr_Active signal.";
CM_ SG_ 644 EngVariant "Informs whether it is diesel or petrol engine";
CM_ SG_ 644 AtmospPr "It the signal recived form Atmospheric pressure sensor in ECU. Incase of the ECU which don't have Atmospheric pressure sensor it will be modeled value derived from other pressure sensor available to ECU. The signal will be used by TCU";
CM_ SG_ 644 ModeChangeTxtEMS "Drive Mode change possible / Not possible information to Instrument cluster";
CM_ SG_ 644 EngCrsCntrlMode "Indicates the cruise Control Mode";
CM_ SG_ 645 IACOpModes "IAC Different operating Modes";
CM_ SG_ 645 IACMeExCurr "Measured Excitation current";
CM_ SG_ 645 IACMeVolt "Measured voltage";
CM_ SG_ 645 IACMeSpd "Alternator Measured speed";
CM_ SG_ 646 UserSpdLim "User set limit value";
CM_ SG_ 646 UserSpdLimLamp "UserSpdLim Lamp state";
CM_ SG_ 646 UserSpdLimFault "User set limiter Fault";
CM_ SG_ 646 UserSpdLimStatus "User set limiter function state";
CM_ SG_ 646 EngStatus "Current Engine State";
CM_ SG_ 646 CeLampState "This information is used   to display or indicate the vehicle related malfunction state ";
CM_ SG_ 646 StaterProhibitionDelay "This information is used  to indicate whether starter inhibited due to prohibition delay";
CM_ SG_ 646 StarterControlState "This information is used to indicate the state of the starter control function";
CM_ SG_ 646 UserSpdLimState "User set limiter function state";
CM_ SG_ 646 SFCActiveEMS "It indicate Safety fuel cut startergy is active due to crash input from SRS ECU enabled/disabled";
CM_ SG_ 646 DrvModeIndctnEMSstatus "Driver mode statys information";
CM_ SG_ 646 CruiseSpdLamp "This information is used   to display or indicate that speed limiter is active or not";
CM_ SG_ 646 StarterControlStatus "Status information";
CM_ SG_ 646 CurrGearEms "This is information is used to display Current Gear information in cluster
";
CM_ SG_ 646 CruiseSpdFault "It indicate the fault in cruise system";
CM_ SG_ 646 CruiseSpdStatus "It indicate the cruise info status";
CM_ SG_ 646 CruiseSpd "This information is used   to indicate the speed limit values in display";
CM_ SG_ 646 CurrGearEmsStatus "status information of CurrGearRatio
";
CM_ SG_ 646 GearShiftIndctnEmsStatus "Gear shift Indication staus used to indicate the gear status signal";
CM_ SG_ 646 GearShiftIndctnEms "Gear shift Indication used to indicate the required gear status in IC  required Gear by the driver is to Improve the drive habits of driver ";
CM_ SG_ 646 CruiseSwitchstate "Resume and Set Cruise Switches stateinformation to support HDC function";
CM_ SG_ 646 CruiseSwitchstateStatus "CruiseSwitchstate Signal status information";
CM_ SG_ 646 DrvModeIndctnEMS "information is used   to display whether the vehicle is in Sports mode/economy mode";
CM_ SG_ 647 EMSRemoteCheckStatus "This signal gives plausibility status of EMSRemoteCheck signal.";
CM_ SG_ 647 EMSRemoteCheck "Signal represents precheck and abuse case scenarios of EMS";
CM_ SG_ 647 DrvModeFailureState "This is a bit mapped signal, refer function net for bit mapped details";
CM_ SG_ 647 ModeChangeTxtEMSNew "Drive Mode change possible / Not possible information to Instrument cluster";
CM_ SG_ 647 DrvModeIndctnEMSNew "information is used   to display whether the vehicle is in Sports mode/economy mode";
CM_ SG_ 647 DrvModeIndctnEMSstatusNew "Driver mode statys information";
CM_ SG_ 647 EngageParkOrNeutral "Information to Driver to Engage P or N for Starting Vehicle";
CM_ SG_ 647 BrkPedalLamp "Information to Driver to Press Brake for Start";
CM_ SG_ 647 OBDWrmUpCycleStatus "OBD Warm Up Cycle Status";
CM_ SG_ 647 OBDDrvCycleStatus "OBD Drive Cycle Status";
CM_ SG_ 647 PressClutToStart "Information to Driver to Press Clutch for Start";
CM_ SG_ 647 CrsResumeInh "Information to Driver that Cruise Resume Operation can't be made";
CM_ SG_ 647 RegntRemainDist "CAN message used to calculate the distance remain with current level of urea tank";
CM_ SG_ 647 SmartAltState "Smart alternator status signal";
CM_ SG_ 647 RegntLevel "Reagent level in the tank (percentage value)";
CM_ SG_ 648 ESSAutonomousStart "ESS autonomous Start status to know the exact reason for Autonomous Start0H-ESS working Normal1H-SOC is lower than set threshold 2H-Brake vacuum pressure is less than set threshold 4H-AC Condition ON 8H-Coolant Temp is less than set threshold/EngTemp or Catalyst temp greater than threshold  10H-Start due to TCU requirement 20H-If steering angle is greater than threshold ,40H- Vehicle rolling speed greater than threshold,80H-Not supported/Signal not Available";
CM_ SG_ 648 ESSAutoStopActCon "Please refer function net for bit value description.";
CM_ SG_ 648 ESSAutoStopInhibited "Engine Start Stop(ESS) auto stop status to know the reason for not allowing the Auto Stop0H-Normal Stop1H-Safety related conditions not met : Engine hood open 2H-Vehicle is on a steep road gradient4H-If driver makes greater steering wheel movements8H-Safety related conditions not met: Driver is not present10H-Coolant Temp lower than set threshold20H-SOC  is lower than set threshold40H-Cabin Temp is higher than set threshold80H-Not supported /Signal Not available";
CM_ SG_ 648 ESSIACSystemAvailable "ESS-IAC System availability information";
CM_ SG_ 648 ESSAutoStartStopActSt "Engine Start Stop (ESS) Activated and denied state";
CM_ SG_ 648 ESSDisableSwitchStatus "ESS enable and disable information Status ";
CM_ SG_ 648 ESSDisableSwitchState "ESS enable and disable information ";
CM_ SG_ 648 ESSAutoStartLamp "ESS Auto start Telltale indication on IC for various condtions ";
CM_ SG_ 648 ESSAutoStopLamp "ESS Auto stop Telltale indication on IC for various condtions";
CM_ SG_ 648 ESSTextMsg "ESS Test massage alnog with Telltale indication on IC for various condtions (In case of Single Lamp for ESS functionality)";
CM_ SG_ 648 ESSLamp "ESS Telltale indication on IC for various condtions (In case of Single Lamp for ESS functionality)";
CM_ SG_ 648 ESSAutoStartForbidden "ESS auto Start status to know the reason for not allowing the Auto Start. 0H-Normal Start 1H-Auto Start Forbidden(ASF) because of error present in Engine 2H-ASF because of Engine is in limp mode 4H-ASF because of Engine Hood is OPEN 8H-ASF because of Transmission is in limp mode 10H-ASF because of Driver is not present in vehicle 20H- ASF because of Crash is Active 40H- ASF because of  park brake is activated 80H- Not supported /Signal Not available";
CM_ SG_ 649 EMsSOhIndex "This signal is used to indicate battery SOH index value.";
CM_ SG_ 649 EMsSOcIndex "This signal is used to indicate battery SOC index value.";
CM_ SG_ 649 IBsSOhSts "This signal is used to indicate plausibility status of State of Health signal.";
CM_ SG_ 649 IBsSOH "This is state of health of vehicle battery evaluated by IBS sensor, communicated by EMS ECU on CAN.";
CM_ SG_ 649 IbsCurr "Ibs current";
CM_ SG_ 649 IbsVtgSt "Ibs Voltage";
CM_ SG_ 649 IBsSOC "This is state of charge of vehicle battery evaluated by IBS sensor, communicated by EMS ECU on CAN.";
CM_ SG_ 649 IbsTempSt "Ibs Temperature ";
CM_ SG_ 649 IBsSOcSts "Ibs soc status signal will be transmited by EMS for diagnsotic purpose";
CM_ SG_ 649 IbsTempSts "IBS temperature signal will be transmited by EMS for diagnsotic purpose ";
CM_ SG_ 649 IbsVtgSts "Ibs Voltage status";
CM_ SG_ 649 IbsCurrSts "Ibs current status signal will be transmited by EMS for diagnsotic purpose ";
CM_ BO_ 650 "Frame to be enabled through DID for X0,X1 ";
CM_ SG_ 650 EPAsStatus "State of EPAS ";
CM_ BO_ 651 "Frame to be enabled through DID for X4 ";
CM_ SG_ 651 SteerWhlTrqStatus "Status information of SteerWhlTrq signal";
CM_ SG_ 651 SteerWhlTrq "Steering wheel applied torque";
CM_ SG_ 651 SAsAngEPAS "Steering Angle information can be used only for comfort function. It has ASIL B.";
CM_ SG_ 651 SAsAngEPAsDir "Steering wheel angle direction";
CM_ SG_ 651 SAsAngEPASStatus "SAS angle status which is showing the plausibilityof this signal";
CM_ SG_ 651 EPASDriverInformation "Display information about the Steering System to the driver.";
CM_ SG_ 651 EPASDriverWarning "Display Steering System warnings to the driver";
CM_ SG_ 651 DrvModeIndctnEPAS "Information is sent from EPAS to IPC and Rotary Switch indicating that it has switched to the corresponding mode.";
CM_ SG_ 651 DrvModeIndctnEPASstatus "Information is used to know the drive mode  status information";
CM_ SG_ 651 EPAsStatusGen2 "Status signal of EPAS System for IC and other ECU if required.Ic should glow the lamp if any implausible signal will transmit. ";
CM_ SG_ 651 EPAsAssistStatus "Information is used to know the status of EPAS assistance";
CM_ SG_ 652 SteerAngEPAsCalibration "Steering angle calibration status which shows whether EPAS Sterring Angle is calibrated or not";
CM_ SG_ 656 StuckModeAvailability "Availability signal for stuck mode function";
CM_ SG_ 656 StuckModeStateStatus "Current status of the stuck mode function of ABS";
CM_ SG_ 656 StuckModeState "Current state indicated by Stuck mode functionality";
CM_ SG_ 656 ModeDetectESPStatus "Information to ESP to IPC and rotary switch indicating that it has switched to correcpoding mode. It is 'Package Protected' signal.";
CM_ SG_ 656 ModeDetectESP "Information to ESP to IPC and rotary switch indicating that it has switched to correcpoding mode. It is 'Package Protected' signal.";
CM_ SG_ 656 WSsPulseCountRearRH "ESP transmits it to HU for navigation purposes.";
CM_ SG_ 656 WSsPulseCountRearLH "ESP transmits it to HU for navigation purposes.";
CM_ SG_ 656 WSsPulseCountFrontRH "ESP transmits it to HU for navigation purposes.";
CM_ SG_ 656 WSsPulseCountFrontLH "ESP transmits it to HU for navigation purposes.";
CM_ SG_ 656 WSsPulseCountFrontRHStatus "ESP transmits it to HU for navigation purposes";
CM_ SG_ 656 WSsPulseCountRearLHStatus "ESP transmits it to HU for navigation purposes";
CM_ SG_ 656 WSsPulseCountRearRHStatus "ESP transmits it to HU for navigation purposes";
CM_ SG_ 656 WSsPulseCountFrontLHStatus "ESP transmits it to HU for navigation purposes";
CM_ SG_ 656 DrvModeIndctnESPStatusNew "Status of the Drive mode indication ESP signal. It is 'Package Protected' signal.";
CM_ SG_ 656 DrvModeIndctnESPNew "Information to ESP to IPC and rotary switch indicating that it has switched to correcpoding mode. It is 'Package Protected' signal.";
CM_ SG_ 660 WhlSpdFrLeft "Angular wheel speed signal transmitted by ABS and ESP ECU and will be given to PEPS & ESCL";
CM_ SG_ 660 WhlSpdFrRight "Angular wheel speed signal transmitted by ABS and ESP ECU and will be given to PEPS & ESCL";
CM_ SG_ 660 WhlSpdFrLeftStatus "status information of WhlSpdFL";
CM_ SG_ 660 WhlSpdRrLeft "Angular wheel speed signal transmitted by ABS and ESP ECU and will be given to PEPS & ESCL";
CM_ SG_ 660 WhlSpdFrRightStatus "status information of WhlSpdFR 
";
CM_ SG_ 660 WhlSpdRrRight "Angular wheel speed signal transmitted by ABS and ESP ECU and will be given to EPAS & other
";
CM_ SG_ 660 WhlSpdRrLeftStatus "status information of WhlSpdRR
";
CM_ SG_ 660 WhlSpdAliveCounter "rolling counter for message 0x294";
CM_ SG_ 660 WhlSpdRrRightStatus "status information of WhlSpdRL
";
CM_ SG_ 660 WhlSpdCRC "CRC for the message 0x294";
BA_DEF_ SG_  "Remarks" STRING ;
BA_DEF_ SG_  "NWM_WakeupAllowed" ENUM  "No","Yes";
BA_DEF_ SG_  "GenSigTimeoutTime_HU_Mid_X451" INT 0 65535;
BA_DEF_ SG_  "GenSigTimeoutTime_HU_High_X451" INT 0 65535;
BA_DEF_ SG_  "GenSigTimeoutTime_HU_B" INT 0 65535;
BA_DEF_ SG_  "GenSigTimeoutTime_HU_A" INT 0 65535;
BA_DEF_ SG_  "GenSigTimeoutTime_BCM_Mid" INT 0 65535;
BA_DEF_ SG_  "GenSigTimeoutMsg_HU_Mid_X451" INT 0 65535;
BA_DEF_ SG_  "GenSigTimeoutMsg_HU_High_X451" INT 0 65535;
BA_DEF_ SG_  "GenSigTimeoutMsg_HU_B" INT 0 65535;
BA_DEF_ SG_  "GenSigTimeoutMsg_HU_A" INT 0 65535;
BA_DEF_ SG_  "GenSigStartValue" INT 0 0;
BA_DEF_ SG_  "GenSigSendType" ENUM  "Cyclic","OnWrite","OnWriteWithRepetition","OnChange","OnChangeWithRepetition","IfActive","IfActiveWithRepetition","NoSigSendType","NotUsed","NotUsed","NotUsed","NotUsed","NotUsed";
BA_DEF_ SG_  "GenSigInactiveValue" INT 0 0;
BA_DEF_ SG_  "GenSigEnvVarType" ENUM  "int","float","undef";
BA_DEF_ SG_  "GenSigCycleTimeActive" INT 0 0;
BA_DEF_ SG_  "GenSigCycleTime" INT 0 0;
BA_DEF_ SG_  "GenSigTimeoutMsg_HU_High_X445" INT 0 65535;
BA_DEF_ SG_  "GenSigTimeoutMsg_HU_Mid_X445" INT 0 65535;
BA_DEF_ SG_  "GenSigTimeoutTime_HU_High_X445" INT 0 65535;
BA_DEF_ SG_  "GenSigTimeoutTime_HU_Mid_X445" INT 0 65535;
BA_DEF_ SG_  "GenSigTimeoutMsg_IVI" INT 0 65535;
BA_DEF_ SG_  "GenSigTimeoutTime_IVI" INT 0 65535;
BA_DEF_ BO_  "NmMessage" ENUM  "no","yes";
BA_DEF_ BO_  "NmAsrMessage" ENUM  "<n.a.>","No","Yes";
BA_DEF_ BO_  "MessageTimeout" INT 0 65535;
BA_DEF_ BO_  "Me" INT 0 0;
BA_DEF_ BO_  "GenMsgStartDelayTime" INT 0 0;
BA_DEF_ BO_  "GenMsgSendType" ENUM  "Cyclic","NotUsed","NotUsed","NotUsed","NotUsed","NotUsed","NotUsed","IfActive","NoMsgSendType","NotUsed";
BA_DEF_ BO_  "GenMsgNrOfRepetition" INT 0 0;
BA_DEF_ BO_  "GenMsgILSupport" ENUM  "No","Yes";
BA_DEF_ BO_  "GenMsgDelayTime" INT 0 0;
BA_DEF_ BO_  "GenMsgCycleTimeFast" INT 0 0;
BA_DEF_ BO_  "GenMsgCycleTime" INT 0 0;
BA_DEF_ BO_  "DiagUudtResponse" ENUM  "false","true";
BA_DEF_ BO_  "DiagUsdtResponse" ENUM  "false","true";
BA_DEF_ BO_  "DiagState" ENUM  "No","Yes";
BA_DEF_ BO_  "DiagResponse" ENUM  "No","Yes";
BA_DEF_ BO_  "DiagRequest" ENUM  "No","Yes";
BA_DEF_ BO_  "MsgType" ENUM  "Application","NM","NMH";
BA_DEF_ SG_  "SystemSignalLongSymbol" STRING ;
BA_DEF_DEF_  "Remarks" "null";
BA_DEF_DEF_  "NWM_WakeupAllowed" "No";
BA_DEF_DEF_  "GenSigTimeoutTime_HU_Mid_X451" 500;
BA_DEF_DEF_  "GenSigTimeoutTime_HU_High_X451" 500;
BA_DEF_DEF_  "GenSigTimeoutTime_HU_B" 500;
BA_DEF_DEF_  "GenSigTimeoutTime_HU_A" 500;
BA_DEF_DEF_  "GenSigTimeoutTime_BCM_Mid" 0;
BA_DEF_DEF_  "GenSigTimeoutMsg_HU_Mid_X451" 500;
BA_DEF_DEF_  "GenSigTimeoutMsg_HU_High_X451" 500;
BA_DEF_DEF_  "GenSigTimeoutMsg_HU_B" 500;
BA_DEF_DEF_  "GenSigTimeoutMsg_HU_A" 500;
BA_DEF_DEF_  "GenSigStartValue" 0;
BA_DEF_DEF_  "GenSigSendType" "Cyclic";
BA_DEF_DEF_  "GenSigInactiveValue" 0;
BA_DEF_DEF_  "GenSigEnvVarType" "undef";
BA_DEF_DEF_  "GenSigCycleTimeActive" 0;
BA_DEF_DEF_  "GenSigCycleTime" 0;
BA_DEF_DEF_  "GenSigTimeoutMsg_HU_High_X445" 500;
BA_DEF_DEF_  "GenSigTimeoutMsg_HU_Mid_X445" 500;
BA_DEF_DEF_  "GenSigTimeoutTime_HU_High_X445" 500;
BA_DEF_DEF_  "GenSigTimeoutTime_HU_Mid_X445" 500;
BA_DEF_DEF_  "GenSigTimeoutMsg_IVI" 500;
BA_DEF_DEF_  "GenSigTimeoutTime_IVI" 500;
BA_DEF_DEF_  "NmMessage" "no";
BA_DEF_DEF_  "NmAsrMessage" "<n.a.>";
BA_DEF_DEF_  "MessageTimeout" 500;
BA_DEF_DEF_  "Me" 0;
BA_DEF_DEF_  "GenMsgStartDelayTime" 0;
BA_DEF_DEF_  "GenMsgSendType" "Cyclic";
BA_DEF_DEF_  "GenMsgNrOfRepetition" 0;
BA_DEF_DEF_  "GenMsgILSupport" "Yes";
BA_DEF_DEF_  "GenMsgDelayTime" 0;
BA_DEF_DEF_  "GenMsgCycleTimeFast" 0;
BA_DEF_DEF_  "GenMsgCycleTime" 0;
BA_DEF_DEF_  "DiagUudtResponse" "false";
BA_DEF_DEF_  "DiagUsdtResponse" "false";
BA_DEF_DEF_  "DiagState" "No";
BA_DEF_DEF_  "DiagResponse" "No";
BA_DEF_DEF_  "DiagRequest" "No";
BA_DEF_DEF_  "MsgType" "Application";
BA_DEF_DEF_  "SystemSignalLongSymbol" "";
BA_ "MessageTimeout" BO_ 506 0;
BA_ "GenMsgSendType" BO_ 506 8;
BA_ "MessageTimeout" BO_ 508 0;
BA_ "GenMsgSendType" BO_ 508 8;
BA_ "MessageTimeout" BO_ 509 0;
BA_ "GenMsgSendType" BO_ 509 8;
BA_ "MessageTimeout" BO_ 510 0;
BA_ "GenMsgSendType" BO_ 510 8;
BA_ "GenMsgCycleTime" BO_ 571 50;
BA_ "GenMsgCycleTime" BO_ 573 50;
BA_ "GenMsgCycleTime" BO_ 614 100;
BA_ "GenMsgCycleTime" BO_ 616 100;
BA_ "GenMsgCycleTime" BO_ 638 100;
BA_ "GenMsgStartDelayTime" BO_ 640 12;
BA_ "GenMsgCycleTime" BO_ 640 100;
BA_ "GenMsgCycleTime" BO_ 643 100;
BA_ "GenMsgStartDelayTime" BO_ 644 15;
BA_ "GenMsgCycleTime" BO_ 644 100;
BA_ "GenMsgCycleTime" BO_ 645 100;
BA_ "GenMsgStartDelayTime" BO_ 646 18;
BA_ "GenMsgCycleTime" BO_ 646 100;
BA_ "GenMsgCycleTime" BO_ 647 100;
BA_ "GenMsgCycleTime" BO_ 648 100;
BA_ "GenMsgCycleTime" BO_ 649 100;
BA_ "GenMsgCycleTime" BO_ 650 100;
BA_ "GenMsgCycleTime" BO_ 651 100;
BA_ "GenMsgCycleTime" BO_ 652 100;
BA_ "GenMsgCycleTime" BO_ 656 100;
BA_ "GenMsgCycleTime" BO_ 660 100;
BA_ "GenSigTimeoutTime_HU_Mid_X451" SG_ 506 HuAutoRelockActiveSignalVal 0;
BA_ "GenSigTimeoutTime_HU_High_X451" SG_ 506 HuAutoRelockActiveSignalVal 0;
BA_ "GenSigTimeoutTime_HU_B" SG_ 506 HuAutoRelockActiveSignalVal 0;
BA_ "GenSigTimeoutTime_HU_A" SG_ 506 HuAutoRelockActiveSignalVal 0;
BA_ "GenSigTimeoutMsg_HU_Mid_X451" SG_ 506 HuAutoRelockActiveSignalVal 0;
BA_ "GenSigTimeoutMsg_HU_High_X451" SG_ 506 HuAutoRelockActiveSignalVal 0;
BA_ "GenSigTimeoutMsg_HU_B" SG_ 506 HuAutoRelockActiveSignalVal 0;
BA_ "GenSigTimeoutMsg_HU_A" SG_ 506 HuAutoRelockActiveSignalVal 0;
BA_ "GenSigSendType" SG_ 506 HuAutoRelockActiveSignalVal 1;
BA_ "GenSigTimeoutMsg_HU_High_X445" SG_ 506 HuAutoRelockActiveSignalVal 0;
BA_ "GenSigTimeoutMsg_HU_Mid_X445" SG_ 506 HuAutoRelockActiveSignalVal 0;
BA_ "GenSigTimeoutTime_HU_High_X445" SG_ 506 HuAutoRelockActiveSignalVal 0;
BA_ "GenSigTimeoutTime_HU_Mid_X445" SG_ 506 HuAutoRelockActiveSignalVal 0;
BA_ "GenSigTimeoutMsg_IVI" SG_ 506 HuAutoRelockActiveSignalVal 0;
BA_ "GenSigTimeoutTime_IVI" SG_ 506 HuAutoRelockActiveSignalVal 0;
BA_ "GenSigTimeoutTime_HU_Mid_X451" SG_ 506 HuFMhActiveSignalVal 0;
BA_ "GenSigTimeoutTime_HU_High_X451" SG_ 506 HuFMhActiveSignalVal 0;
BA_ "GenSigTimeoutTime_HU_B" SG_ 506 HuFMhActiveSignalVal 0;
BA_ "GenSigTimeoutTime_HU_A" SG_ 506 HuFMhActiveSignalVal 0;
BA_ "GenSigTimeoutMsg_HU_Mid_X451" SG_ 506 HuFMhActiveSignalVal 0;
BA_ "GenSigTimeoutMsg_HU_High_X451" SG_ 506 HuFMhActiveSignalVal 0;
BA_ "GenSigTimeoutMsg_HU_B" SG_ 506 HuFMhActiveSignalVal 0;
BA_ "GenSigTimeoutMsg_HU_A" SG_ 506 HuFMhActiveSignalVal 0;
BA_ "GenSigSendType" SG_ 506 HuFMhActiveSignalVal 1;
BA_ "GenSigTimeoutMsg_HU_High_X445" SG_ 506 HuFMhActiveSignalVal 0;
BA_ "GenSigTimeoutMsg_HU_Mid_X445" SG_ 506 HuFMhActiveSignalVal 0;
BA_ "GenSigTimeoutTime_HU_High_X445" SG_ 506 HuFMhActiveSignalVal 0;
BA_ "GenSigTimeoutTime_HU_Mid_X445" SG_ 506 HuFMhActiveSignalVal 0;
BA_ "GenSigTimeoutMsg_IVI" SG_ 506 HuFMhActiveSignalVal 0;
BA_ "GenSigTimeoutTime_IVI" SG_ 506 HuFMhActiveSignalVal 0;
BA_ "GenSigTimeoutTime_HU_Mid_X451" SG_ 506 HuFMhSignalVal1 0;
BA_ "GenSigTimeoutTime_HU_High_X451" SG_ 506 HuFMhSignalVal1 0;
BA_ "GenSigTimeoutTime_HU_B" SG_ 506 HuFMhSignalVal1 0;
BA_ "GenSigTimeoutTime_HU_A" SG_ 506 HuFMhSignalVal1 0;
BA_ "GenSigTimeoutMsg_HU_Mid_X451" SG_ 506 HuFMhSignalVal1 0;
BA_ "GenSigTimeoutMsg_HU_High_X451" SG_ 506 HuFMhSignalVal1 0;
BA_ "GenSigTimeoutMsg_HU_B" SG_ 506 HuFMhSignalVal1 0;
BA_ "GenSigTimeoutMsg_HU_A" SG_ 506 HuFMhSignalVal1 0;
BA_ "GenSigSendType" SG_ 506 HuFMhSignalVal1 1;
BA_ "GenSigTimeoutMsg_HU_High_X445" SG_ 506 HuFMhSignalVal1 0;
BA_ "GenSigTimeoutMsg_HU_Mid_X445" SG_ 506 HuFMhSignalVal1 0;
BA_ "GenSigTimeoutTime_HU_High_X445" SG_ 506 HuFMhSignalVal1 0;
BA_ "GenSigTimeoutTime_HU_Mid_X445" SG_ 506 HuFMhSignalVal1 0;
BA_ "GenSigTimeoutMsg_IVI" SG_ 506 HuFMhSignalVal1 0;
BA_ "GenSigTimeoutTime_IVI" SG_ 506 HuFMhSignalVal1 0;
BA_ "GenSigTimeoutTime_HU_Mid_X451" SG_ 506 HuVehLockHornReqActiveSignalVal 0;
BA_ "GenSigTimeoutTime_HU_High_X451" SG_ 506 HuVehLockHornReqActiveSignalVal 0;
BA_ "GenSigTimeoutTime_HU_B" SG_ 506 HuVehLockHornReqActiveSignalVal 0;
BA_ "GenSigTimeoutTime_HU_A" SG_ 506 HuVehLockHornReqActiveSignalVal 0;
BA_ "GenSigTimeoutMsg_HU_Mid_X451" SG_ 506 HuVehLockHornReqActiveSignalVal 0;
BA_ "GenSigTimeoutMsg_HU_High_X451" SG_ 506 HuVehLockHornReqActiveSignalVal 0;
BA_ "GenSigTimeoutMsg_HU_B" SG_ 506 HuVehLockHornReqActiveSignalVal 0;
BA_ "GenSigTimeoutMsg_HU_A" SG_ 506 HuVehLockHornReqActiveSignalVal 0;
BA_ "GenSigSendType" SG_ 506 HuVehLockHornReqActiveSignalVal 1;
BA_ "GenSigTimeoutMsg_HU_High_X445" SG_ 506 HuVehLockHornReqActiveSignalVal 0;
BA_ "GenSigTimeoutMsg_HU_Mid_X445" SG_ 506 HuVehLockHornReqActiveSignalVal 0;
BA_ "GenSigTimeoutTime_HU_High_X445" SG_ 506 HuVehLockHornReqActiveSignalVal 0;
BA_ "GenSigTimeoutTime_HU_Mid_X445" SG_ 506 HuVehLockHornReqActiveSignalVal 0;
BA_ "GenSigTimeoutMsg_IVI" SG_ 506 HuVehLockHornReqActiveSignalVal 0;
BA_ "GenSigTimeoutTime_IVI" SG_ 506 HuVehLockHornReqActiveSignalVal 0;
BA_ "GenSigTimeoutTime_HU_Mid_X451" SG_ 506 HuApproachLampActiveSignalVal 0;
BA_ "GenSigTimeoutTime_HU_High_X451" SG_ 506 HuApproachLampActiveSignalVal 0;
BA_ "GenSigTimeoutTime_HU_B" SG_ 506 HuApproachLampActiveSignalVal 0;
BA_ "GenSigTimeoutTime_HU_A" SG_ 506 HuApproachLampActiveSignalVal 0;
BA_ "GenSigTimeoutMsg_HU_Mid_X451" SG_ 506 HuApproachLampActiveSignalVal 0;
BA_ "GenSigTimeoutMsg_HU_High_X451" SG_ 506 HuApproachLampActiveSignalVal 0;
BA_ "GenSigTimeoutMsg_HU_B" SG_ 506 HuApproachLampActiveSignalVal 0;
BA_ "GenSigTimeoutMsg_HU_A" SG_ 506 HuApproachLampActiveSignalVal 0;
BA_ "GenSigSendType" SG_ 506 HuApproachLampActiveSignalVal 1;
BA_ "GenSigTimeoutMsg_HU_High_X445" SG_ 506 HuApproachLampActiveSignalVal 0;
BA_ "GenSigTimeoutMsg_HU_Mid_X445" SG_ 506 HuApproachLampActiveSignalVal 0;
BA_ "GenSigTimeoutTime_HU_High_X445" SG_ 506 HuApproachLampActiveSignalVal 0;
BA_ "GenSigTimeoutTime_HU_Mid_X445" SG_ 506 HuApproachLampActiveSignalVal 0;
BA_ "GenSigTimeoutMsg_IVI" SG_ 506 HuApproachLampActiveSignalVal 0;
BA_ "GenSigTimeoutTime_IVI" SG_ 506 HuApproachLampActiveSignalVal 0;
BA_ "GenSigTimeoutTime_HU_Mid_X451" SG_ 506 HuFMhSignalVal2 0;
BA_ "GenSigTimeoutTime_HU_High_X451" SG_ 506 HuFMhSignalVal2 0;
BA_ "GenSigTimeoutTime_HU_B" SG_ 506 HuFMhSignalVal2 0;
BA_ "GenSigTimeoutTime_HU_A" SG_ 506 HuFMhSignalVal2 0;
BA_ "GenSigTimeoutMsg_HU_Mid_X451" SG_ 506 HuFMhSignalVal2 0;
BA_ "GenSigTimeoutMsg_HU_High_X451" SG_ 506 HuFMhSignalVal2 0;
BA_ "GenSigTimeoutMsg_HU_B" SG_ 506 HuFMhSignalVal2 0;
BA_ "GenSigTimeoutMsg_HU_A" SG_ 506 HuFMhSignalVal2 0;
BA_ "GenSigSendType" SG_ 506 HuFMhSignalVal2 1;
BA_ "GenSigTimeoutMsg_HU_High_X445" SG_ 506 HuFMhSignalVal2 0;
BA_ "GenSigTimeoutMsg_HU_Mid_X445" SG_ 506 HuFMhSignalVal2 0;
BA_ "GenSigTimeoutTime_HU_High_X445" SG_ 506 HuFMhSignalVal2 0;
BA_ "GenSigTimeoutTime_HU_Mid_X445" SG_ 506 HuFMhSignalVal2 0;
BA_ "GenSigTimeoutMsg_IVI" SG_ 506 HuFMhSignalVal2 0;
BA_ "GenSigTimeoutTime_IVI" SG_ 506 HuFMhSignalVal2 0;
BA_ "GenSigTimeoutTime_HU_Mid_X451" SG_ 506 HuDriveAwayLockingActiveSignalVa 0;
BA_ "GenSigTimeoutTime_HU_High_X451" SG_ 506 HuDriveAwayLockingActiveSignalVa 0;
BA_ "GenSigTimeoutTime_HU_B" SG_ 506 HuDriveAwayLockingActiveSignalVa 0;
BA_ "GenSigTimeoutTime_HU_A" SG_ 506 HuDriveAwayLockingActiveSignalVa 0;
BA_ "GenSigTimeoutMsg_HU_Mid_X451" SG_ 506 HuDriveAwayLockingActiveSignalVa 0;
BA_ "GenSigTimeoutMsg_HU_High_X451" SG_ 506 HuDriveAwayLockingActiveSignalVa 0;
BA_ "GenSigTimeoutMsg_HU_B" SG_ 506 HuDriveAwayLockingActiveSignalVa 0;
BA_ "GenSigTimeoutMsg_HU_A" SG_ 506 HuDriveAwayLockingActiveSignalVa 0;
BA_ "GenSigSendType" SG_ 506 HuDriveAwayLockingActiveSignalVa 1;
BA_ "GenSigTimeoutMsg_HU_High_X445" SG_ 506 HuDriveAwayLockingActiveSignalVa 0;
BA_ "GenSigTimeoutMsg_HU_Mid_X445" SG_ 506 HuDriveAwayLockingActiveSignalVa 0;
BA_ "GenSigTimeoutTime_HU_High_X445" SG_ 506 HuDriveAwayLockingActiveSignalVa 0;
BA_ "GenSigTimeoutTime_HU_Mid_X445" SG_ 506 HuDriveAwayLockingActiveSignalVa 0;
BA_ "GenSigTimeoutMsg_IVI" SG_ 506 HuDriveAwayLockingActiveSignalVa 0;
BA_ "GenSigTimeoutTime_IVI" SG_ 506 HuDriveAwayLockingActiveSignalVa 0;
BA_ "SystemSignalLongSymbol" SG_ 506 HuDriveAwayLockingActiveSignalVa "HuDriveAwayLockingActiveSignalVal";
BA_ "GenSigTimeoutTime_HU_Mid_X451" SG_ 506 HuRKeUnlockActiveSignalVal 0;
BA_ "GenSigTimeoutTime_HU_High_X451" SG_ 506 HuRKeUnlockActiveSignalVal 0;
BA_ "GenSigTimeoutTime_HU_B" SG_ 506 HuRKeUnlockActiveSignalVal 0;
BA_ "GenSigTimeoutTime_HU_A" SG_ 506 HuRKeUnlockActiveSignalVal 0;
BA_ "GenSigTimeoutMsg_HU_Mid_X451" SG_ 506 HuRKeUnlockActiveSignalVal 0;
BA_ "GenSigTimeoutMsg_HU_High_X451" SG_ 506 HuRKeUnlockActiveSignalVal 0;
BA_ "GenSigTimeoutMsg_HU_B" SG_ 506 HuRKeUnlockActiveSignalVal 0;
BA_ "GenSigTimeoutMsg_HU_A" SG_ 506 HuRKeUnlockActiveSignalVal 0;
BA_ "GenSigSendType" SG_ 506 HuRKeUnlockActiveSignalVal 1;
BA_ "GenSigTimeoutMsg_HU_High_X445" SG_ 506 HuRKeUnlockActiveSignalVal 0;
BA_ "GenSigTimeoutMsg_HU_Mid_X445" SG_ 506 HuRKeUnlockActiveSignalVal 0;
BA_ "GenSigTimeoutTime_HU_High_X445" SG_ 506 HuRKeUnlockActiveSignalVal 0;
BA_ "GenSigTimeoutTime_HU_Mid_X445" SG_ 506 HuRKeUnlockActiveSignalVal 0;
BA_ "GenSigTimeoutMsg_IVI" SG_ 506 HuRKeUnlockActiveSignalVal 0;
BA_ "GenSigTimeoutTime_IVI" SG_ 506 HuRKeUnlockActiveSignalVal 0;
BA_ "GenSigTimeoutTime_HU_Mid_X451" SG_ 506 HuPKeUnlockActiveSignalVal 0;
BA_ "GenSigTimeoutTime_HU_High_X451" SG_ 506 HuPKeUnlockActiveSignalVal 0;
BA_ "GenSigTimeoutTime_HU_B" SG_ 506 HuPKeUnlockActiveSignalVal 0;
BA_ "GenSigTimeoutTime_HU_A" SG_ 506 HuPKeUnlockActiveSignalVal 0;
BA_ "GenSigTimeoutMsg_HU_Mid_X451" SG_ 506 HuPKeUnlockActiveSignalVal 0;
BA_ "GenSigTimeoutMsg_HU_High_X451" SG_ 506 HuPKeUnlockActiveSignalVal 0;
BA_ "GenSigTimeoutMsg_HU_B" SG_ 506 HuPKeUnlockActiveSignalVal 0;
BA_ "GenSigTimeoutMsg_HU_A" SG_ 506 HuPKeUnlockActiveSignalVal 0;
BA_ "GenSigSendType" SG_ 506 HuPKeUnlockActiveSignalVal 1;
BA_ "GenSigTimeoutMsg_HU_High_X445" SG_ 506 HuPKeUnlockActiveSignalVal 0;
BA_ "GenSigTimeoutMsg_HU_Mid_X445" SG_ 506 HuPKeUnlockActiveSignalVal 0;
BA_ "GenSigTimeoutTime_HU_High_X445" SG_ 506 HuPKeUnlockActiveSignalVal 0;
BA_ "GenSigTimeoutTime_HU_Mid_X445" SG_ 506 HuPKeUnlockActiveSignalVal 0;
BA_ "GenSigTimeoutMsg_IVI" SG_ 506 HuPKeUnlockActiveSignalVal 0;
BA_ "GenSigTimeoutTime_IVI" SG_ 506 HuPKeUnlockActiveSignalVal 0;
BA_ "GenSigTimeoutTime_HU_Mid_X451" SG_ 506 HuFMhSignalVal3 0;
BA_ "GenSigTimeoutTime_HU_High_X451" SG_ 506 HuFMhSignalVal3 0;
BA_ "GenSigTimeoutTime_HU_B" SG_ 506 HuFMhSignalVal3 0;
BA_ "GenSigTimeoutTime_HU_A" SG_ 506 HuFMhSignalVal3 0;
BA_ "GenSigTimeoutMsg_HU_Mid_X451" SG_ 506 HuFMhSignalVal3 0;
BA_ "GenSigTimeoutMsg_HU_High_X451" SG_ 506 HuFMhSignalVal3 0;
BA_ "GenSigTimeoutMsg_HU_B" SG_ 506 HuFMhSignalVal3 0;
BA_ "GenSigTimeoutMsg_HU_A" SG_ 506 HuFMhSignalVal3 0;
BA_ "GenSigSendType" SG_ 506 HuFMhSignalVal3 1;
BA_ "GenSigTimeoutMsg_HU_High_X445" SG_ 506 HuFMhSignalVal3 0;
BA_ "GenSigTimeoutMsg_HU_Mid_X445" SG_ 506 HuFMhSignalVal3 0;
BA_ "GenSigTimeoutTime_HU_High_X445" SG_ 506 HuFMhSignalVal3 0;
BA_ "GenSigTimeoutTime_HU_Mid_X445" SG_ 506 HuFMhSignalVal3 0;
BA_ "GenSigTimeoutMsg_IVI" SG_ 506 HuFMhSignalVal3 0;
BA_ "GenSigTimeoutTime_IVI" SG_ 506 HuFMhSignalVal3 0;
BA_ "GenSigTimeoutTime_HU_Mid_X451" SG_ 506 BCmFactorySettingReq 0;
BA_ "GenSigTimeoutTime_HU_High_X451" SG_ 506 BCmFactorySettingReq 0;
BA_ "GenSigTimeoutTime_HU_B" SG_ 506 BCmFactorySettingReq 0;
BA_ "GenSigTimeoutTime_HU_A" SG_ 506 BCmFactorySettingReq 0;
BA_ "GenSigTimeoutMsg_HU_Mid_X451" SG_ 506 BCmFactorySettingReq 0;
BA_ "GenSigTimeoutMsg_HU_High_X451" SG_ 506 BCmFactorySettingReq 0;
BA_ "GenSigTimeoutMsg_HU_B" SG_ 506 BCmFactorySettingReq 0;
BA_ "GenSigTimeoutMsg_HU_A" SG_ 506 BCmFactorySettingReq 0;
BA_ "GenSigSendType" SG_ 506 BCmFactorySettingReq 1;
BA_ "GenSigTimeoutMsg_HU_High_X445" SG_ 506 BCmFactorySettingReq 0;
BA_ "GenSigTimeoutMsg_HU_Mid_X445" SG_ 506 BCmFactorySettingReq 0;
BA_ "GenSigTimeoutTime_HU_High_X445" SG_ 506 BCmFactorySettingReq 0;
BA_ "GenSigTimeoutTime_HU_Mid_X445" SG_ 506 BCmFactorySettingReq 0;
BA_ "GenSigTimeoutMsg_IVI" SG_ 506 BCmFactorySettingReq 0;
BA_ "GenSigTimeoutTime_IVI" SG_ 506 BCmFactorySettingReq 0;
BA_ "GenSigTimeoutTime_HU_Mid_X451" SG_ 506 HuApproachLampSignalVal1 0;
BA_ "GenSigTimeoutTime_HU_High_X451" SG_ 506 HuApproachLampSignalVal1 0;
BA_ "GenSigTimeoutTime_HU_B" SG_ 506 HuApproachLampSignalVal1 0;
BA_ "GenSigTimeoutTime_HU_A" SG_ 506 HuApproachLampSignalVal1 0;
BA_ "GenSigTimeoutMsg_HU_Mid_X451" SG_ 506 HuApproachLampSignalVal1 0;
BA_ "GenSigTimeoutMsg_HU_High_X451" SG_ 506 HuApproachLampSignalVal1 0;
BA_ "GenSigTimeoutMsg_HU_B" SG_ 506 HuApproachLampSignalVal1 0;
BA_ "GenSigTimeoutMsg_HU_A" SG_ 506 HuApproachLampSignalVal1 0;
BA_ "GenSigSendType" SG_ 506 HuApproachLampSignalVal1 1;
BA_ "GenSigTimeoutMsg_HU_High_X445" SG_ 506 HuApproachLampSignalVal1 0;
BA_ "GenSigTimeoutMsg_HU_Mid_X445" SG_ 506 HuApproachLampSignalVal1 0;
BA_ "GenSigTimeoutTime_HU_High_X445" SG_ 506 HuApproachLampSignalVal1 0;
BA_ "GenSigTimeoutTime_HU_Mid_X445" SG_ 506 HuApproachLampSignalVal1 0;
BA_ "GenSigTimeoutMsg_IVI" SG_ 506 HuApproachLampSignalVal1 0;
BA_ "GenSigTimeoutTime_IVI" SG_ 506 HuApproachLampSignalVal1 0;
BA_ "GenSigTimeoutTime_HU_Mid_X451" SG_ 506 HuDRLActiveSignalVal 0;
BA_ "GenSigTimeoutTime_HU_High_X451" SG_ 506 HuDRLActiveSignalVal 0;
BA_ "GenSigTimeoutTime_HU_B" SG_ 506 HuDRLActiveSignalVal 0;
BA_ "GenSigTimeoutTime_HU_A" SG_ 506 HuDRLActiveSignalVal 0;
BA_ "GenSigTimeoutMsg_HU_Mid_X451" SG_ 506 HuDRLActiveSignalVal 0;
BA_ "GenSigTimeoutMsg_HU_High_X451" SG_ 506 HuDRLActiveSignalVal 0;
BA_ "GenSigTimeoutMsg_HU_B" SG_ 506 HuDRLActiveSignalVal 0;
BA_ "GenSigTimeoutMsg_HU_A" SG_ 506 HuDRLActiveSignalVal 0;
BA_ "GenSigSendType" SG_ 506 HuDRLActiveSignalVal 1;
BA_ "GenSigTimeoutMsg_HU_High_X445" SG_ 506 HuDRLActiveSignalVal 0;
BA_ "GenSigTimeoutMsg_HU_Mid_X445" SG_ 506 HuDRLActiveSignalVal 0;
BA_ "GenSigTimeoutTime_HU_High_X445" SG_ 506 HuDRLActiveSignalVal 0;
BA_ "GenSigTimeoutTime_HU_Mid_X445" SG_ 506 HuDRLActiveSignalVal 0;
BA_ "GenSigTimeoutMsg_IVI" SG_ 506 HuDRLActiveSignalVal 0;
BA_ "GenSigTimeoutTime_IVI" SG_ 506 HuDRLActiveSignalVal 0;
BA_ "GenSigTimeoutTime_HU_Mid_X451" SG_ 506 HuQueryInfo 0;
BA_ "GenSigTimeoutTime_HU_High_X451" SG_ 506 HuQueryInfo 0;
BA_ "GenSigTimeoutTime_HU_B" SG_ 506 HuQueryInfo 0;
BA_ "GenSigTimeoutTime_HU_A" SG_ 506 HuQueryInfo 0;
BA_ "GenSigTimeoutMsg_HU_Mid_X451" SG_ 506 HuQueryInfo 0;
BA_ "GenSigTimeoutMsg_HU_High_X451" SG_ 506 HuQueryInfo 0;
BA_ "GenSigTimeoutMsg_HU_B" SG_ 506 HuQueryInfo 0;
BA_ "GenSigTimeoutMsg_HU_A" SG_ 506 HuQueryInfo 0;
BA_ "GenSigSendType" SG_ 506 HuQueryInfo 1;
BA_ "GenSigTimeoutMsg_HU_High_X445" SG_ 506 HuQueryInfo 0;
BA_ "GenSigTimeoutMsg_HU_Mid_X445" SG_ 506 HuQueryInfo 0;
BA_ "GenSigTimeoutTime_HU_High_X445" SG_ 506 HuQueryInfo 0;
BA_ "GenSigTimeoutTime_HU_Mid_X445" SG_ 506 HuQueryInfo 0;
BA_ "GenSigTimeoutMsg_IVI" SG_ 506 HuQueryInfo 0;
BA_ "GenSigTimeoutTime_IVI" SG_ 506 HuQueryInfo 0;
BA_ "GenSigTimeoutTime_HU_Mid_X451" SG_ 506 HuApproachLampSignalVal2 0;
BA_ "GenSigTimeoutTime_HU_High_X451" SG_ 506 HuApproachLampSignalVal2 0;
BA_ "GenSigTimeoutTime_HU_B" SG_ 506 HuApproachLampSignalVal2 0;
BA_ "GenSigTimeoutTime_HU_A" SG_ 506 HuApproachLampSignalVal2 0;
BA_ "GenSigTimeoutMsg_HU_Mid_X451" SG_ 506 HuApproachLampSignalVal2 0;
BA_ "GenSigTimeoutMsg_HU_High_X451" SG_ 506 HuApproachLampSignalVal2 0;
BA_ "GenSigTimeoutMsg_HU_B" SG_ 506 HuApproachLampSignalVal2 0;
BA_ "GenSigTimeoutMsg_HU_A" SG_ 506 HuApproachLampSignalVal2 0;
BA_ "GenSigSendType" SG_ 506 HuApproachLampSignalVal2 1;
BA_ "GenSigTimeoutMsg_HU_High_X445" SG_ 506 HuApproachLampSignalVal2 0;
BA_ "GenSigTimeoutMsg_HU_Mid_X445" SG_ 506 HuApproachLampSignalVal2 0;
BA_ "GenSigTimeoutTime_HU_High_X445" SG_ 506 HuApproachLampSignalVal2 0;
BA_ "GenSigTimeoutTime_HU_Mid_X445" SG_ 506 HuApproachLampSignalVal2 0;
BA_ "GenSigTimeoutMsg_IVI" SG_ 506 HuApproachLampSignalVal2 0;
BA_ "GenSigTimeoutTime_IVI" SG_ 506 HuApproachLampSignalVal2 0;
BA_ "GenSigTimeoutTime_HU_Mid_X451" SG_ 506 HuApproachLampSignalVal3 0;
BA_ "GenSigTimeoutTime_HU_High_X451" SG_ 506 HuApproachLampSignalVal3 0;
BA_ "GenSigTimeoutTime_HU_B" SG_ 506 HuApproachLampSignalVal3 0;
BA_ "GenSigTimeoutTime_HU_A" SG_ 506 HuApproachLampSignalVal3 0;
BA_ "GenSigTimeoutMsg_HU_Mid_X451" SG_ 506 HuApproachLampSignalVal3 0;
BA_ "GenSigTimeoutMsg_HU_High_X451" SG_ 506 HuApproachLampSignalVal3 0;
BA_ "GenSigTimeoutMsg_HU_B" SG_ 506 HuApproachLampSignalVal3 0;
BA_ "GenSigTimeoutMsg_HU_A" SG_ 506 HuApproachLampSignalVal3 0;
BA_ "GenSigSendType" SG_ 506 HuApproachLampSignalVal3 1;
BA_ "GenSigTimeoutMsg_HU_High_X445" SG_ 506 HuApproachLampSignalVal3 0;
BA_ "GenSigTimeoutMsg_HU_Mid_X445" SG_ 506 HuApproachLampSignalVal3 0;
BA_ "GenSigTimeoutTime_HU_High_X445" SG_ 506 HuApproachLampSignalVal3 0;
BA_ "GenSigTimeoutTime_HU_Mid_X445" SG_ 506 HuApproachLampSignalVal3 0;
BA_ "GenSigTimeoutMsg_IVI" SG_ 506 HuApproachLampSignalVal3 0;
BA_ "GenSigTimeoutTime_IVI" SG_ 506 HuApproachLampSignalVal3 0;
BA_ "GenSigTimeoutTime_HU_Mid_X451" SG_ 508 HuMoodLightAllAreaActiveValue 0;
BA_ "GenSigTimeoutTime_HU_High_X451" SG_ 508 HuMoodLightAllAreaActiveValue 0;
BA_ "GenSigTimeoutTime_HU_B" SG_ 508 HuMoodLightAllAreaActiveValue 0;
BA_ "GenSigTimeoutTime_HU_A" SG_ 508 HuMoodLightAllAreaActiveValue 0;
BA_ "GenSigTimeoutMsg_HU_Mid_X451" SG_ 508 HuMoodLightAllAreaActiveValue 0;
BA_ "GenSigTimeoutMsg_HU_High_X451" SG_ 508 HuMoodLightAllAreaActiveValue 0;
BA_ "GenSigTimeoutMsg_HU_B" SG_ 508 HuMoodLightAllAreaActiveValue 0;
BA_ "GenSigTimeoutMsg_HU_A" SG_ 508 HuMoodLightAllAreaActiveValue 0;
BA_ "GenSigStartValue" SG_ 508 HuMoodLightAllAreaActiveValue 1;
BA_ "GenSigSendType" SG_ 508 HuMoodLightAllAreaActiveValue 1;
BA_ "GenSigInactiveValue" SG_ 508 HuMoodLightAllAreaActiveValue 1;
BA_ "GenSigTimeoutMsg_HU_High_X445" SG_ 508 HuMoodLightAllAreaActiveValue 0;
BA_ "GenSigTimeoutMsg_HU_Mid_X445" SG_ 508 HuMoodLightAllAreaActiveValue 0;
BA_ "GenSigTimeoutTime_HU_High_X445" SG_ 508 HuMoodLightAllAreaActiveValue 0;
BA_ "GenSigTimeoutTime_HU_Mid_X445" SG_ 508 HuMoodLightAllAreaActiveValue 0;
BA_ "GenSigTimeoutMsg_IVI" SG_ 508 HuMoodLightAllAreaActiveValue 0;
BA_ "GenSigTimeoutTime_IVI" SG_ 508 HuMoodLightAllAreaActiveValue 0;
BA_ "GenSigTimeoutTime_HU_Mid_X451" SG_ 508 HuMoodLightIllumSelActiveValue 0;
BA_ "GenSigTimeoutTime_HU_High_X451" SG_ 508 HuMoodLightIllumSelActiveValue 0;
BA_ "GenSigTimeoutTime_HU_B" SG_ 508 HuMoodLightIllumSelActiveValue 0;
BA_ "GenSigTimeoutTime_HU_A" SG_ 508 HuMoodLightIllumSelActiveValue 0;
BA_ "GenSigTimeoutMsg_HU_Mid_X451" SG_ 508 HuMoodLightIllumSelActiveValue 0;
BA_ "GenSigTimeoutMsg_HU_High_X451" SG_ 508 HuMoodLightIllumSelActiveValue 0;
BA_ "GenSigTimeoutMsg_HU_B" SG_ 508 HuMoodLightIllumSelActiveValue 0;
BA_ "GenSigTimeoutMsg_HU_A" SG_ 508 HuMoodLightIllumSelActiveValue 0;
BA_ "GenSigSendType" SG_ 508 HuMoodLightIllumSelActiveValue 1;
BA_ "GenSigTimeoutMsg_HU_High_X445" SG_ 508 HuMoodLightIllumSelActiveValue 0;
BA_ "GenSigTimeoutMsg_HU_Mid_X445" SG_ 508 HuMoodLightIllumSelActiveValue 0;
BA_ "GenSigTimeoutTime_HU_High_X445" SG_ 508 HuMoodLightIllumSelActiveValue 0;
BA_ "GenSigTimeoutTime_HU_Mid_X445" SG_ 508 HuMoodLightIllumSelActiveValue 0;
BA_ "GenSigTimeoutMsg_IVI" SG_ 508 HuMoodLightIllumSelActiveValue 0;
BA_ "GenSigTimeoutTime_IVI" SG_ 508 HuMoodLightIllumSelActiveValue 0;
BA_ "GenSigTimeoutTime_HU_Mid_X451" SG_ 508 HuMoodLightActiveColourValue 0;
BA_ "GenSigTimeoutTime_HU_High_X451" SG_ 508 HuMoodLightActiveColourValue 0;
BA_ "GenSigTimeoutTime_HU_B" SG_ 508 HuMoodLightActiveColourValue 0;
BA_ "GenSigTimeoutTime_HU_A" SG_ 508 HuMoodLightActiveColourValue 0;
BA_ "GenSigTimeoutMsg_HU_Mid_X451" SG_ 508 HuMoodLightActiveColourValue 0;
BA_ "GenSigTimeoutMsg_HU_High_X451" SG_ 508 HuMoodLightActiveColourValue 0;
BA_ "GenSigTimeoutMsg_HU_B" SG_ 508 HuMoodLightActiveColourValue 0;
BA_ "GenSigTimeoutMsg_HU_A" SG_ 508 HuMoodLightActiveColourValue 0;
BA_ "GenSigSendType" SG_ 508 HuMoodLightActiveColourValue 1;
BA_ "GenSigTimeoutMsg_HU_High_X445" SG_ 508 HuMoodLightActiveColourValue 0;
BA_ "GenSigTimeoutMsg_HU_Mid_X445" SG_ 508 HuMoodLightActiveColourValue 0;
BA_ "GenSigTimeoutTime_HU_High_X445" SG_ 508 HuMoodLightActiveColourValue 0;
BA_ "GenSigTimeoutTime_HU_Mid_X445" SG_ 508 HuMoodLightActiveColourValue 0;
BA_ "GenSigTimeoutMsg_IVI" SG_ 508 HuMoodLightActiveColourValue 0;
BA_ "GenSigTimeoutTime_IVI" SG_ 508 HuMoodLightActiveColourValue 0;
BA_ "GenSigTimeoutTime_HU_Mid_X451" SG_ 508 HuMoodLightRearAreaActiveValue 0;
BA_ "GenSigTimeoutTime_HU_High_X451" SG_ 508 HuMoodLightRearAreaActiveValue 0;
BA_ "GenSigTimeoutTime_HU_B" SG_ 508 HuMoodLightRearAreaActiveValue 0;
BA_ "GenSigTimeoutTime_HU_A" SG_ 508 HuMoodLightRearAreaActiveValue 0;
BA_ "GenSigTimeoutMsg_HU_Mid_X451" SG_ 508 HuMoodLightRearAreaActiveValue 0;
BA_ "GenSigTimeoutMsg_HU_High_X451" SG_ 508 HuMoodLightRearAreaActiveValue 0;
BA_ "GenSigTimeoutMsg_HU_B" SG_ 508 HuMoodLightRearAreaActiveValue 0;
BA_ "GenSigTimeoutMsg_HU_A" SG_ 508 HuMoodLightRearAreaActiveValue 0;
BA_ "GenSigStartValue" SG_ 508 HuMoodLightRearAreaActiveValue 1;
BA_ "GenSigSendType" SG_ 508 HuMoodLightRearAreaActiveValue 1;
BA_ "GenSigInactiveValue" SG_ 508 HuMoodLightRearAreaActiveValue 1;
BA_ "GenSigTimeoutMsg_HU_High_X445" SG_ 508 HuMoodLightRearAreaActiveValue 0;
BA_ "GenSigTimeoutMsg_HU_Mid_X445" SG_ 508 HuMoodLightRearAreaActiveValue 0;
BA_ "GenSigTimeoutTime_HU_High_X445" SG_ 508 HuMoodLightRearAreaActiveValue 0;
BA_ "GenSigTimeoutTime_HU_Mid_X445" SG_ 508 HuMoodLightRearAreaActiveValue 0;
BA_ "GenSigTimeoutMsg_IVI" SG_ 508 HuMoodLightRearAreaActiveValue 0;
BA_ "GenSigTimeoutTime_IVI" SG_ 508 HuMoodLightRearAreaActiveValue 0;
BA_ "GenSigTimeoutTime_HU_Mid_X451" SG_ 508 HuMoodLightFrontRHAreaActiveValu 0;
BA_ "GenSigTimeoutTime_HU_High_X451" SG_ 508 HuMoodLightFrontRHAreaActiveValu 0;
BA_ "GenSigTimeoutTime_HU_B" SG_ 508 HuMoodLightFrontRHAreaActiveValu 0;
BA_ "GenSigTimeoutTime_HU_A" SG_ 508 HuMoodLightFrontRHAreaActiveValu 0;
BA_ "GenSigTimeoutMsg_HU_Mid_X451" SG_ 508 HuMoodLightFrontRHAreaActiveValu 0;
BA_ "GenSigTimeoutMsg_HU_High_X451" SG_ 508 HuMoodLightFrontRHAreaActiveValu 0;
BA_ "GenSigTimeoutMsg_HU_B" SG_ 508 HuMoodLightFrontRHAreaActiveValu 0;
BA_ "GenSigTimeoutMsg_HU_A" SG_ 508 HuMoodLightFrontRHAreaActiveValu 0;
BA_ "GenSigStartValue" SG_ 508 HuMoodLightFrontRHAreaActiveValu 1;
BA_ "GenSigSendType" SG_ 508 HuMoodLightFrontRHAreaActiveValu 1;
BA_ "GenSigInactiveValue" SG_ 508 HuMoodLightFrontRHAreaActiveValu 1;
BA_ "GenSigTimeoutMsg_HU_High_X445" SG_ 508 HuMoodLightFrontRHAreaActiveValu 0;
BA_ "GenSigTimeoutMsg_HU_Mid_X445" SG_ 508 HuMoodLightFrontRHAreaActiveValu 0;
BA_ "GenSigTimeoutTime_HU_High_X445" SG_ 508 HuMoodLightFrontRHAreaActiveValu 0;
BA_ "GenSigTimeoutTime_HU_Mid_X445" SG_ 508 HuMoodLightFrontRHAreaActiveValu 0;
BA_ "GenSigTimeoutMsg_IVI" SG_ 508 HuMoodLightFrontRHAreaActiveValu 0;
BA_ "GenSigTimeoutTime_IVI" SG_ 508 HuMoodLightFrontRHAreaActiveValu 0;
BA_ "SystemSignalLongSymbol" SG_ 508 HuMoodLightFrontRHAreaActiveValu "HuMoodLightFrontRHAreaActiveValue";
BA_ "GenSigTimeoutTime_HU_Mid_X451" SG_ 508 HuMoodLightFloorConsoleAreaActiv 0;
BA_ "GenSigTimeoutTime_HU_High_X451" SG_ 508 HuMoodLightFloorConsoleAreaActiv 0;
BA_ "GenSigTimeoutTime_HU_B" SG_ 508 HuMoodLightFloorConsoleAreaActiv 0;
BA_ "GenSigTimeoutTime_HU_A" SG_ 508 HuMoodLightFloorConsoleAreaActiv 0;
BA_ "GenSigTimeoutMsg_HU_Mid_X451" SG_ 508 HuMoodLightFloorConsoleAreaActiv 0;
BA_ "GenSigTimeoutMsg_HU_High_X451" SG_ 508 HuMoodLightFloorConsoleAreaActiv 0;
BA_ "GenSigTimeoutMsg_HU_B" SG_ 508 HuMoodLightFloorConsoleAreaActiv 0;
BA_ "GenSigTimeoutMsg_HU_A" SG_ 508 HuMoodLightFloorConsoleAreaActiv 0;
BA_ "GenSigStartValue" SG_ 508 HuMoodLightFloorConsoleAreaActiv 1;
BA_ "GenSigSendType" SG_ 508 HuMoodLightFloorConsoleAreaActiv 1;
BA_ "GenSigInactiveValue" SG_ 508 HuMoodLightFloorConsoleAreaActiv 1;
BA_ "GenSigTimeoutMsg_HU_High_X445" SG_ 508 HuMoodLightFloorConsoleAreaActiv 0;
BA_ "GenSigTimeoutMsg_HU_Mid_X445" SG_ 508 HuMoodLightFloorConsoleAreaActiv 0;
BA_ "GenSigTimeoutTime_HU_High_X445" SG_ 508 HuMoodLightFloorConsoleAreaActiv 0;
BA_ "GenSigTimeoutTime_HU_Mid_X445" SG_ 508 HuMoodLightFloorConsoleAreaActiv 0;
BA_ "GenSigTimeoutMsg_IVI" SG_ 508 HuMoodLightFloorConsoleAreaActiv 0;
BA_ "GenSigTimeoutTime_IVI" SG_ 508 HuMoodLightFloorConsoleAreaActiv 0;
BA_ "SystemSignalLongSymbol" SG_ 508 HuMoodLightFloorConsoleAreaActiv "HuMoodLightFloorConsoleAreaActiveValue";
BA_ "GenSigTimeoutTime_HU_Mid_X451" SG_ 508 HuMoodLightData 0;
BA_ "GenSigTimeoutTime_HU_High_X451" SG_ 508 HuMoodLightData 0;
BA_ "GenSigTimeoutTime_HU_B" SG_ 508 HuMoodLightData 0;
BA_ "GenSigTimeoutTime_HU_A" SG_ 508 HuMoodLightData 0;
BA_ "GenSigTimeoutMsg_HU_Mid_X451" SG_ 508 HuMoodLightData 0;
BA_ "GenSigTimeoutMsg_HU_High_X451" SG_ 508 HuMoodLightData 0;
BA_ "GenSigTimeoutMsg_HU_B" SG_ 508 HuMoodLightData 0;
BA_ "GenSigTimeoutMsg_HU_A" SG_ 508 HuMoodLightData 0;
BA_ "GenSigSendType" SG_ 508 HuMoodLightData 1;
BA_ "GenSigTimeoutMsg_HU_High_X445" SG_ 508 HuMoodLightData 0;
BA_ "GenSigTimeoutMsg_HU_Mid_X445" SG_ 508 HuMoodLightData 0;
BA_ "GenSigTimeoutTime_HU_High_X445" SG_ 508 HuMoodLightData 0;
BA_ "GenSigTimeoutTime_HU_Mid_X445" SG_ 508 HuMoodLightData 0;
BA_ "GenSigTimeoutMsg_IVI" SG_ 508 HuMoodLightData 0;
BA_ "GenSigTimeoutTime_IVI" SG_ 508 HuMoodLightData 0;
BA_ "GenSigTimeoutTime_HU_Mid_X451" SG_ 508 HuMoodLightIllumPossibleLevels 0;
BA_ "GenSigTimeoutTime_HU_High_X451" SG_ 508 HuMoodLightIllumPossibleLevels 0;
BA_ "GenSigTimeoutTime_HU_B" SG_ 508 HuMoodLightIllumPossibleLevels 0;
BA_ "GenSigTimeoutTime_HU_A" SG_ 508 HuMoodLightIllumPossibleLevels 0;
BA_ "GenSigTimeoutMsg_HU_Mid_X451" SG_ 508 HuMoodLightIllumPossibleLevels 0;
BA_ "GenSigTimeoutMsg_HU_High_X451" SG_ 508 HuMoodLightIllumPossibleLevels 0;
BA_ "GenSigTimeoutMsg_HU_B" SG_ 508 HuMoodLightIllumPossibleLevels 0;
BA_ "GenSigTimeoutMsg_HU_A" SG_ 508 HuMoodLightIllumPossibleLevels 0;
BA_ "GenSigStartValue" SG_ 508 HuMoodLightIllumPossibleLevels 5;
BA_ "GenSigSendType" SG_ 508 HuMoodLightIllumPossibleLevels 1;
BA_ "GenSigInactiveValue" SG_ 508 HuMoodLightIllumPossibleLevels 5;
BA_ "GenSigTimeoutMsg_HU_High_X445" SG_ 508 HuMoodLightIllumPossibleLevels 0;
BA_ "GenSigTimeoutMsg_HU_Mid_X445" SG_ 508 HuMoodLightIllumPossibleLevels 0;
BA_ "GenSigTimeoutTime_HU_High_X445" SG_ 508 HuMoodLightIllumPossibleLevels 0;
BA_ "GenSigTimeoutTime_HU_Mid_X445" SG_ 508 HuMoodLightIllumPossibleLevels 0;
BA_ "GenSigTimeoutMsg_IVI" SG_ 508 HuMoodLightIllumPossibleLevels 0;
BA_ "GenSigTimeoutTime_IVI" SG_ 508 HuMoodLightIllumPossibleLevels 0;
BA_ "GenSigTimeoutTime_HU_Mid_X451" SG_ 508 HuMoodLightHotMagentaColorSelOnH 0;
BA_ "GenSigTimeoutTime_HU_High_X451" SG_ 508 HuMoodLightHotMagentaColorSelOnH 0;
BA_ "GenSigTimeoutTime_HU_B" SG_ 508 HuMoodLightHotMagentaColorSelOnH 0;
BA_ "GenSigTimeoutTime_HU_A" SG_ 508 HuMoodLightHotMagentaColorSelOnH 0;
BA_ "GenSigTimeoutMsg_HU_Mid_X451" SG_ 508 HuMoodLightHotMagentaColorSelOnH 0;
BA_ "GenSigTimeoutMsg_HU_High_X451" SG_ 508 HuMoodLightHotMagentaColorSelOnH 0;
BA_ "GenSigTimeoutMsg_HU_B" SG_ 508 HuMoodLightHotMagentaColorSelOnH 0;
BA_ "GenSigTimeoutMsg_HU_A" SG_ 508 HuMoodLightHotMagentaColorSelOnH 0;
BA_ "GenSigSendType" SG_ 508 HuMoodLightHotMagentaColorSelOnH 1;
BA_ "GenSigTimeoutMsg_HU_High_X445" SG_ 508 HuMoodLightHotMagentaColorSelOnH 0;
BA_ "GenSigTimeoutMsg_HU_Mid_X445" SG_ 508 HuMoodLightHotMagentaColorSelOnH 0;
BA_ "GenSigTimeoutTime_HU_High_X445" SG_ 508 HuMoodLightHotMagentaColorSelOnH 0;
BA_ "GenSigTimeoutTime_HU_Mid_X445" SG_ 508 HuMoodLightHotMagentaColorSelOnH 0;
BA_ "GenSigTimeoutMsg_IVI" SG_ 508 HuMoodLightHotMagentaColorSelOnH 0;
BA_ "GenSigTimeoutTime_IVI" SG_ 508 HuMoodLightHotMagentaColorSelOnH 0;
BA_ "SystemSignalLongSymbol" SG_ 508 HuMoodLightHotMagentaColorSelOnH "HuMoodLightHotMagentaColorSelOnHU";
BA_ "GenSigTimeoutTime_HU_Mid_X451" SG_ 508 HuMoodLightGoldYellowColorSelOnH 0;
BA_ "GenSigTimeoutTime_HU_High_X451" SG_ 508 HuMoodLightGoldYellowColorSelOnH 0;
BA_ "GenSigTimeoutTime_HU_B" SG_ 508 HuMoodLightGoldYellowColorSelOnH 0;
BA_ "GenSigTimeoutTime_HU_A" SG_ 508 HuMoodLightGoldYellowColorSelOnH 0;
BA_ "GenSigTimeoutMsg_HU_Mid_X451" SG_ 508 HuMoodLightGoldYellowColorSelOnH 0;
BA_ "GenSigTimeoutMsg_HU_High_X451" SG_ 508 HuMoodLightGoldYellowColorSelOnH 0;
BA_ "GenSigTimeoutMsg_HU_B" SG_ 508 HuMoodLightGoldYellowColorSelOnH 0;
BA_ "GenSigTimeoutMsg_HU_A" SG_ 508 HuMoodLightGoldYellowColorSelOnH 0;
BA_ "GenSigSendType" SG_ 508 HuMoodLightGoldYellowColorSelOnH 1;
BA_ "GenSigTimeoutMsg_HU_High_X445" SG_ 508 HuMoodLightGoldYellowColorSelOnH 0;
BA_ "GenSigTimeoutMsg_HU_Mid_X445" SG_ 508 HuMoodLightGoldYellowColorSelOnH 0;
BA_ "GenSigTimeoutTime_HU_High_X445" SG_ 508 HuMoodLightGoldYellowColorSelOnH 0;
BA_ "GenSigTimeoutTime_HU_Mid_X445" SG_ 508 HuMoodLightGoldYellowColorSelOnH 0;
BA_ "GenSigTimeoutMsg_IVI" SG_ 508 HuMoodLightGoldYellowColorSelOnH 0;
BA_ "GenSigTimeoutTime_IVI" SG_ 508 HuMoodLightGoldYellowColorSelOnH 0;
BA_ "SystemSignalLongSymbol" SG_ 508 HuMoodLightGoldYellowColorSelOnH "HuMoodLightGoldYellowColorSelOnHU";
BA_ "GenSigTimeoutTime_HU_Mid_X451" SG_ 508 HuMoodLightFrenchLimeColorSelOnH 0;
BA_ "GenSigTimeoutTime_HU_High_X451" SG_ 508 HuMoodLightFrenchLimeColorSelOnH 0;
BA_ "GenSigTimeoutTime_HU_B" SG_ 508 HuMoodLightFrenchLimeColorSelOnH 0;
BA_ "GenSigTimeoutTime_HU_A" SG_ 508 HuMoodLightFrenchLimeColorSelOnH 0;
BA_ "GenSigTimeoutMsg_HU_Mid_X451" SG_ 508 HuMoodLightFrenchLimeColorSelOnH 0;
BA_ "GenSigTimeoutMsg_HU_High_X451" SG_ 508 HuMoodLightFrenchLimeColorSelOnH 0;
BA_ "GenSigTimeoutMsg_HU_B" SG_ 508 HuMoodLightFrenchLimeColorSelOnH 0;
BA_ "GenSigTimeoutMsg_HU_A" SG_ 508 HuMoodLightFrenchLimeColorSelOnH 0;
BA_ "GenSigSendType" SG_ 508 HuMoodLightFrenchLimeColorSelOnH 1;
BA_ "GenSigTimeoutMsg_HU_High_X445" SG_ 508 HuMoodLightFrenchLimeColorSelOnH 0;
BA_ "GenSigTimeoutMsg_HU_Mid_X445" SG_ 508 HuMoodLightFrenchLimeColorSelOnH 0;
BA_ "GenSigTimeoutTime_HU_High_X445" SG_ 508 HuMoodLightFrenchLimeColorSelOnH 0;
BA_ "GenSigTimeoutTime_HU_Mid_X445" SG_ 508 HuMoodLightFrenchLimeColorSelOnH 0;
BA_ "GenSigTimeoutMsg_IVI" SG_ 508 HuMoodLightFrenchLimeColorSelOnH 0;
BA_ "GenSigTimeoutTime_IVI" SG_ 508 HuMoodLightFrenchLimeColorSelOnH 0;
BA_ "SystemSignalLongSymbol" SG_ 508 HuMoodLightFrenchLimeColorSelOnH "HuMoodLightFrenchLimeColorSelOnHU";
BA_ "GenSigTimeoutTime_HU_Mid_X451" SG_ 508 HuMoodLightFrontLHAreaActiveValu 0;
BA_ "GenSigTimeoutTime_HU_High_X451" SG_ 508 HuMoodLightFrontLHAreaActiveValu 0;
BA_ "GenSigTimeoutTime_HU_B" SG_ 508 HuMoodLightFrontLHAreaActiveValu 0;
BA_ "GenSigTimeoutTime_HU_A" SG_ 508 HuMoodLightFrontLHAreaActiveValu 0;
BA_ "GenSigTimeoutMsg_HU_Mid_X451" SG_ 508 HuMoodLightFrontLHAreaActiveValu 0;
BA_ "GenSigTimeoutMsg_HU_High_X451" SG_ 508 HuMoodLightFrontLHAreaActiveValu 0;
BA_ "GenSigTimeoutMsg_HU_B" SG_ 508 HuMoodLightFrontLHAreaActiveValu 0;
BA_ "GenSigTimeoutMsg_HU_A" SG_ 508 HuMoodLightFrontLHAreaActiveValu 0;
BA_ "GenSigStartValue" SG_ 508 HuMoodLightFrontLHAreaActiveValu 1;
BA_ "GenSigSendType" SG_ 508 HuMoodLightFrontLHAreaActiveValu 1;
BA_ "GenSigInactiveValue" SG_ 508 HuMoodLightFrontLHAreaActiveValu 1;
BA_ "GenSigTimeoutMsg_HU_High_X445" SG_ 508 HuMoodLightFrontLHAreaActiveValu 0;
BA_ "GenSigTimeoutMsg_HU_Mid_X445" SG_ 508 HuMoodLightFrontLHAreaActiveValu 0;
BA_ "GenSigTimeoutTime_HU_High_X445" SG_ 508 HuMoodLightFrontLHAreaActiveValu 0;
BA_ "GenSigTimeoutTime_HU_Mid_X445" SG_ 508 HuMoodLightFrontLHAreaActiveValu 0;
BA_ "GenSigTimeoutMsg_IVI" SG_ 508 HuMoodLightFrontLHAreaActiveValu 0;
BA_ "GenSigTimeoutTime_IVI" SG_ 508 HuMoodLightFrontLHAreaActiveValu 0;
BA_ "SystemSignalLongSymbol" SG_ 508 HuMoodLightFrontLHAreaActiveValu "HuMoodLightFrontLHAreaActiveValue";
BA_ "GenSigTimeoutTime_HU_Mid_X451" SG_ 508 HuMoodLightPossibleModes 0;
BA_ "GenSigTimeoutTime_HU_High_X451" SG_ 508 HuMoodLightPossibleModes 0;
BA_ "GenSigTimeoutTime_HU_B" SG_ 508 HuMoodLightPossibleModes 0;
BA_ "GenSigTimeoutTime_HU_A" SG_ 508 HuMoodLightPossibleModes 0;
BA_ "GenSigTimeoutMsg_HU_Mid_X451" SG_ 508 HuMoodLightPossibleModes 0;
BA_ "GenSigTimeoutMsg_HU_High_X451" SG_ 508 HuMoodLightPossibleModes 0;
BA_ "GenSigTimeoutMsg_HU_B" SG_ 508 HuMoodLightPossibleModes 0;
BA_ "GenSigTimeoutMsg_HU_A" SG_ 508 HuMoodLightPossibleModes 0;
BA_ "GenSigStartValue" SG_ 508 HuMoodLightPossibleModes 2;
BA_ "GenSigSendType" SG_ 508 HuMoodLightPossibleModes 1;
BA_ "GenSigInactiveValue" SG_ 508 HuMoodLightPossibleModes 2;
BA_ "GenSigTimeoutMsg_HU_High_X445" SG_ 508 HuMoodLightPossibleModes 0;
BA_ "GenSigTimeoutMsg_HU_Mid_X445" SG_ 508 HuMoodLightPossibleModes 0;
BA_ "GenSigTimeoutTime_HU_High_X445" SG_ 508 HuMoodLightPossibleModes 0;
BA_ "GenSigTimeoutTime_HU_Mid_X445" SG_ 508 HuMoodLightPossibleModes 0;
BA_ "GenSigTimeoutMsg_IVI" SG_ 508 HuMoodLightPossibleModes 0;
BA_ "GenSigTimeoutTime_IVI" SG_ 508 HuMoodLightPossibleModes 0;
BA_ "GenSigTimeoutTime_HU_Mid_X451" SG_ 508 HuMoodLightActiveModeValue 0;
BA_ "GenSigTimeoutTime_HU_High_X451" SG_ 508 HuMoodLightActiveModeValue 0;
BA_ "GenSigTimeoutTime_HU_B" SG_ 508 HuMoodLightActiveModeValue 0;
BA_ "GenSigTimeoutTime_HU_A" SG_ 508 HuMoodLightActiveModeValue 0;
BA_ "GenSigTimeoutMsg_HU_Mid_X451" SG_ 508 HuMoodLightActiveModeValue 0;
BA_ "GenSigTimeoutMsg_HU_High_X451" SG_ 508 HuMoodLightActiveModeValue 0;
BA_ "GenSigTimeoutMsg_HU_B" SG_ 508 HuMoodLightActiveModeValue 0;
BA_ "GenSigTimeoutMsg_HU_A" SG_ 508 HuMoodLightActiveModeValue 0;
BA_ "GenSigSendType" SG_ 508 HuMoodLightActiveModeValue 1;
BA_ "GenSigTimeoutMsg_HU_High_X445" SG_ 508 HuMoodLightActiveModeValue 0;
BA_ "GenSigTimeoutMsg_HU_Mid_X445" SG_ 508 HuMoodLightActiveModeValue 0;
BA_ "GenSigTimeoutTime_HU_High_X445" SG_ 508 HuMoodLightActiveModeValue 0;
BA_ "GenSigTimeoutTime_HU_Mid_X445" SG_ 508 HuMoodLightActiveModeValue 0;
BA_ "GenSigTimeoutMsg_IVI" SG_ 508 HuMoodLightActiveModeValue 0;
BA_ "GenSigTimeoutTime_IVI" SG_ 508 HuMoodLightActiveModeValue 0;
BA_ "GenSigTimeoutTime_HU_Mid_X451" SG_ 508 HuMoodLightPolarBrightWhiteColor 0;
BA_ "GenSigTimeoutTime_HU_High_X451" SG_ 508 HuMoodLightPolarBrightWhiteColor 0;
BA_ "GenSigTimeoutTime_HU_B" SG_ 508 HuMoodLightPolarBrightWhiteColor 0;
BA_ "GenSigTimeoutTime_HU_A" SG_ 508 HuMoodLightPolarBrightWhiteColor 0;
BA_ "GenSigTimeoutMsg_HU_Mid_X451" SG_ 508 HuMoodLightPolarBrightWhiteColor 0;
BA_ "GenSigTimeoutMsg_HU_High_X451" SG_ 508 HuMoodLightPolarBrightWhiteColor 0;
BA_ "GenSigTimeoutMsg_HU_B" SG_ 508 HuMoodLightPolarBrightWhiteColor 0;
BA_ "GenSigTimeoutMsg_HU_A" SG_ 508 HuMoodLightPolarBrightWhiteColor 0;
BA_ "GenSigSendType" SG_ 508 HuMoodLightPolarBrightWhiteColor 1;
BA_ "GenSigTimeoutMsg_HU_High_X445" SG_ 508 HuMoodLightPolarBrightWhiteColor 0;
BA_ "GenSigTimeoutMsg_HU_Mid_X445" SG_ 508 HuMoodLightPolarBrightWhiteColor 0;
BA_ "GenSigTimeoutTime_HU_High_X445" SG_ 508 HuMoodLightPolarBrightWhiteColor 0;
BA_ "GenSigTimeoutTime_HU_Mid_X445" SG_ 508 HuMoodLightPolarBrightWhiteColor 0;
BA_ "GenSigTimeoutMsg_IVI" SG_ 508 HuMoodLightPolarBrightWhiteColor 0;
BA_ "GenSigTimeoutTime_IVI" SG_ 508 HuMoodLightPolarBrightWhiteColor 0;
BA_ "SystemSignalLongSymbol" SG_ 508 HuMoodLightPolarBrightWhiteColor "HuMoodLightPolarBrightWhiteColorSelOnHU";
BA_ "GenSigTimeoutTime_HU_Mid_X451" SG_ 508 HuMoodLightAeroBlueColorSelOnHU 0;
BA_ "GenSigTimeoutTime_HU_High_X451" SG_ 508 HuMoodLightAeroBlueColorSelOnHU 0;
BA_ "GenSigTimeoutTime_HU_B" SG_ 508 HuMoodLightAeroBlueColorSelOnHU 0;
BA_ "GenSigTimeoutTime_HU_A" SG_ 508 HuMoodLightAeroBlueColorSelOnHU 0;
BA_ "GenSigTimeoutMsg_HU_Mid_X451" SG_ 508 HuMoodLightAeroBlueColorSelOnHU 0;
BA_ "GenSigTimeoutMsg_HU_High_X451" SG_ 508 HuMoodLightAeroBlueColorSelOnHU 0;
BA_ "GenSigTimeoutMsg_HU_B" SG_ 508 HuMoodLightAeroBlueColorSelOnHU 0;
BA_ "GenSigTimeoutMsg_HU_A" SG_ 508 HuMoodLightAeroBlueColorSelOnHU 0;
BA_ "GenSigSendType" SG_ 508 HuMoodLightAeroBlueColorSelOnHU 1;
BA_ "GenSigTimeoutMsg_HU_High_X445" SG_ 508 HuMoodLightAeroBlueColorSelOnHU 0;
BA_ "GenSigTimeoutMsg_HU_Mid_X445" SG_ 508 HuMoodLightAeroBlueColorSelOnHU 0;
BA_ "GenSigTimeoutTime_HU_High_X445" SG_ 508 HuMoodLightAeroBlueColorSelOnHU 0;
BA_ "GenSigTimeoutTime_HU_Mid_X445" SG_ 508 HuMoodLightAeroBlueColorSelOnHU 0;
BA_ "GenSigTimeoutMsg_IVI" SG_ 508 HuMoodLightAeroBlueColorSelOnHU 0;
BA_ "GenSigTimeoutTime_IVI" SG_ 508 HuMoodLightAeroBlueColorSelOnHU 0;
BA_ "GenSigTimeoutTime_HU_Mid_X451" SG_ 508 HuMoodLightPurpleColorSelOnHU 0;
BA_ "GenSigTimeoutTime_HU_High_X451" SG_ 508 HuMoodLightPurpleColorSelOnHU 0;
BA_ "GenSigTimeoutTime_HU_B" SG_ 508 HuMoodLightPurpleColorSelOnHU 0;
BA_ "GenSigTimeoutTime_HU_A" SG_ 508 HuMoodLightPurpleColorSelOnHU 0;
BA_ "GenSigTimeoutMsg_HU_Mid_X451" SG_ 508 HuMoodLightPurpleColorSelOnHU 0;
BA_ "GenSigTimeoutMsg_HU_High_X451" SG_ 508 HuMoodLightPurpleColorSelOnHU 0;
BA_ "GenSigTimeoutMsg_HU_B" SG_ 508 HuMoodLightPurpleColorSelOnHU 0;
BA_ "GenSigTimeoutMsg_HU_A" SG_ 508 HuMoodLightPurpleColorSelOnHU 0;
BA_ "GenSigSendType" SG_ 508 HuMoodLightPurpleColorSelOnHU 1;
BA_ "GenSigTimeoutMsg_HU_High_X445" SG_ 508 HuMoodLightPurpleColorSelOnHU 0;
BA_ "GenSigTimeoutMsg_HU_Mid_X445" SG_ 508 HuMoodLightPurpleColorSelOnHU 0;
BA_ "GenSigTimeoutTime_HU_High_X445" SG_ 508 HuMoodLightPurpleColorSelOnHU 0;
BA_ "GenSigTimeoutTime_HU_Mid_X445" SG_ 508 HuMoodLightPurpleColorSelOnHU 0;
BA_ "GenSigTimeoutMsg_IVI" SG_ 508 HuMoodLightPurpleColorSelOnHU 0;
BA_ "GenSigTimeoutTime_IVI" SG_ 508 HuMoodLightPurpleColorSelOnHU 0;
BA_ "GenSigTimeoutTime_HU_Mid_X451" SG_ 508 HuMoodLightFluorescentGreenColor 0;
BA_ "GenSigTimeoutTime_HU_High_X451" SG_ 508 HuMoodLightFluorescentGreenColor 0;
BA_ "GenSigTimeoutTime_HU_B" SG_ 508 HuMoodLightFluorescentGreenColor 0;
BA_ "GenSigTimeoutTime_HU_A" SG_ 508 HuMoodLightFluorescentGreenColor 0;
BA_ "GenSigTimeoutMsg_HU_Mid_X451" SG_ 508 HuMoodLightFluorescentGreenColor 0;
BA_ "GenSigTimeoutMsg_HU_High_X451" SG_ 508 HuMoodLightFluorescentGreenColor 0;
BA_ "GenSigTimeoutMsg_HU_B" SG_ 508 HuMoodLightFluorescentGreenColor 0;
BA_ "GenSigTimeoutMsg_HU_A" SG_ 508 HuMoodLightFluorescentGreenColor 0;
BA_ "GenSigSendType" SG_ 508 HuMoodLightFluorescentGreenColor 1;
BA_ "GenSigTimeoutMsg_HU_High_X445" SG_ 508 HuMoodLightFluorescentGreenColor 0;
BA_ "GenSigTimeoutMsg_HU_Mid_X445" SG_ 508 HuMoodLightFluorescentGreenColor 0;
BA_ "GenSigTimeoutTime_HU_High_X445" SG_ 508 HuMoodLightFluorescentGreenColor 0;
BA_ "GenSigTimeoutTime_HU_Mid_X445" SG_ 508 HuMoodLightFluorescentGreenColor 0;
BA_ "GenSigTimeoutMsg_IVI" SG_ 508 HuMoodLightFluorescentGreenColor 0;
BA_ "GenSigTimeoutTime_IVI" SG_ 508 HuMoodLightFluorescentGreenColor 0;
BA_ "SystemSignalLongSymbol" SG_ 508 HuMoodLightFluorescentGreenColor "HuMoodLightFluorescentGreenColorSelOnHU";
BA_ "GenSigTimeoutTime_HU_Mid_X451" SG_ 508 HuMoodLightCyanBlueColorSelOnHU 0;
BA_ "GenSigTimeoutTime_HU_High_X451" SG_ 508 HuMoodLightCyanBlueColorSelOnHU 0;
BA_ "GenSigTimeoutTime_HU_B" SG_ 508 HuMoodLightCyanBlueColorSelOnHU 0;
BA_ "GenSigTimeoutTime_HU_A" SG_ 508 HuMoodLightCyanBlueColorSelOnHU 0;
BA_ "GenSigTimeoutMsg_HU_Mid_X451" SG_ 508 HuMoodLightCyanBlueColorSelOnHU 0;
BA_ "GenSigTimeoutMsg_HU_High_X451" SG_ 508 HuMoodLightCyanBlueColorSelOnHU 0;
BA_ "GenSigTimeoutMsg_HU_B" SG_ 508 HuMoodLightCyanBlueColorSelOnHU 0;
BA_ "GenSigTimeoutMsg_HU_A" SG_ 508 HuMoodLightCyanBlueColorSelOnHU 0;
BA_ "GenSigSendType" SG_ 508 HuMoodLightCyanBlueColorSelOnHU 1;
BA_ "GenSigTimeoutMsg_HU_High_X445" SG_ 508 HuMoodLightCyanBlueColorSelOnHU 0;
BA_ "GenSigTimeoutMsg_HU_Mid_X445" SG_ 508 HuMoodLightCyanBlueColorSelOnHU 0;
BA_ "GenSigTimeoutTime_HU_High_X445" SG_ 508 HuMoodLightCyanBlueColorSelOnHU 0;
BA_ "GenSigTimeoutTime_HU_Mid_X445" SG_ 508 HuMoodLightCyanBlueColorSelOnHU 0;
BA_ "GenSigTimeoutMsg_IVI" SG_ 508 HuMoodLightCyanBlueColorSelOnHU 0;
BA_ "GenSigTimeoutTime_IVI" SG_ 508 HuMoodLightCyanBlueColorSelOnHU 0;
BA_ "GenSigTimeoutTime_HU_Mid_X451" SG_ 508 HuMoodLightCoolBlueColorSelOnHU 0;
BA_ "GenSigTimeoutTime_HU_High_X451" SG_ 508 HuMoodLightCoolBlueColorSelOnHU 0;
BA_ "GenSigTimeoutTime_HU_B" SG_ 508 HuMoodLightCoolBlueColorSelOnHU 0;
BA_ "GenSigTimeoutTime_HU_A" SG_ 508 HuMoodLightCoolBlueColorSelOnHU 0;
BA_ "GenSigTimeoutMsg_HU_Mid_X451" SG_ 508 HuMoodLightCoolBlueColorSelOnHU 0;
BA_ "GenSigTimeoutMsg_HU_High_X451" SG_ 508 HuMoodLightCoolBlueColorSelOnHU 0;
BA_ "GenSigTimeoutMsg_HU_B" SG_ 508 HuMoodLightCoolBlueColorSelOnHU 0;
BA_ "GenSigTimeoutMsg_HU_A" SG_ 508 HuMoodLightCoolBlueColorSelOnHU 0;
BA_ "GenSigSendType" SG_ 508 HuMoodLightCoolBlueColorSelOnHU 1;
BA_ "GenSigTimeoutMsg_HU_High_X445" SG_ 508 HuMoodLightCoolBlueColorSelOnHU 0;
BA_ "GenSigTimeoutMsg_HU_Mid_X445" SG_ 508 HuMoodLightCoolBlueColorSelOnHU 0;
BA_ "GenSigTimeoutTime_HU_High_X445" SG_ 508 HuMoodLightCoolBlueColorSelOnHU 0;
BA_ "GenSigTimeoutTime_HU_Mid_X445" SG_ 508 HuMoodLightCoolBlueColorSelOnHU 0;
BA_ "GenSigTimeoutMsg_IVI" SG_ 508 HuMoodLightCoolBlueColorSelOnHU 0;
BA_ "GenSigTimeoutTime_IVI" SG_ 508 HuMoodLightCoolBlueColorSelOnHU 0;
BA_ "GenSigTimeoutTime_HU_Mid_X451" SG_ 508 HuMoodLightIvoryOFFWhiteColorSel 0;
BA_ "GenSigTimeoutTime_HU_High_X451" SG_ 508 HuMoodLightIvoryOFFWhiteColorSel 0;
BA_ "GenSigTimeoutTime_HU_B" SG_ 508 HuMoodLightIvoryOFFWhiteColorSel 0;
BA_ "GenSigTimeoutTime_HU_A" SG_ 508 HuMoodLightIvoryOFFWhiteColorSel 0;
BA_ "GenSigTimeoutMsg_HU_Mid_X451" SG_ 508 HuMoodLightIvoryOFFWhiteColorSel 0;
BA_ "GenSigTimeoutMsg_HU_High_X451" SG_ 508 HuMoodLightIvoryOFFWhiteColorSel 0;
BA_ "GenSigTimeoutMsg_HU_B" SG_ 508 HuMoodLightIvoryOFFWhiteColorSel 0;
BA_ "GenSigTimeoutMsg_HU_A" SG_ 508 HuMoodLightIvoryOFFWhiteColorSel 0;
BA_ "GenSigSendType" SG_ 508 HuMoodLightIvoryOFFWhiteColorSel 1;
BA_ "GenSigTimeoutMsg_HU_High_X445" SG_ 508 HuMoodLightIvoryOFFWhiteColorSel 0;
BA_ "GenSigTimeoutMsg_HU_Mid_X445" SG_ 508 HuMoodLightIvoryOFFWhiteColorSel 0;
BA_ "GenSigTimeoutTime_HU_High_X445" SG_ 508 HuMoodLightIvoryOFFWhiteColorSel 0;
BA_ "GenSigTimeoutTime_HU_Mid_X445" SG_ 508 HuMoodLightIvoryOFFWhiteColorSel 0;
BA_ "GenSigTimeoutMsg_IVI" SG_ 508 HuMoodLightIvoryOFFWhiteColorSel 0;
BA_ "GenSigTimeoutTime_IVI" SG_ 508 HuMoodLightIvoryOFFWhiteColorSel 0;
BA_ "SystemSignalLongSymbol" SG_ 508 HuMoodLightIvoryOFFWhiteColorSel "HuMoodLightIvoryOFFWhiteColorSelOnHU";
BA_ "GenSigTimeoutTime_HU_Mid_X451" SG_ 508 HuMoodLightIceBlueColorSelOnHU 0;
BA_ "GenSigTimeoutTime_HU_High_X451" SG_ 508 HuMoodLightIceBlueColorSelOnHU 0;
BA_ "GenSigTimeoutTime_HU_B" SG_ 508 HuMoodLightIceBlueColorSelOnHU 0;
BA_ "GenSigTimeoutTime_HU_A" SG_ 508 HuMoodLightIceBlueColorSelOnHU 0;
BA_ "GenSigTimeoutMsg_HU_Mid_X451" SG_ 508 HuMoodLightIceBlueColorSelOnHU 0;
BA_ "GenSigTimeoutMsg_HU_High_X451" SG_ 508 HuMoodLightIceBlueColorSelOnHU 0;
BA_ "GenSigTimeoutMsg_HU_B" SG_ 508 HuMoodLightIceBlueColorSelOnHU 0;
BA_ "GenSigTimeoutMsg_HU_A" SG_ 508 HuMoodLightIceBlueColorSelOnHU 0;
BA_ "GenSigSendType" SG_ 508 HuMoodLightIceBlueColorSelOnHU 1;
BA_ "GenSigTimeoutMsg_HU_High_X445" SG_ 508 HuMoodLightIceBlueColorSelOnHU 0;
BA_ "GenSigTimeoutMsg_HU_Mid_X445" SG_ 508 HuMoodLightIceBlueColorSelOnHU 0;
BA_ "GenSigTimeoutTime_HU_High_X445" SG_ 508 HuMoodLightIceBlueColorSelOnHU 0;
BA_ "GenSigTimeoutTime_HU_Mid_X445" SG_ 508 HuMoodLightIceBlueColorSelOnHU 0;
BA_ "GenSigTimeoutMsg_IVI" SG_ 508 HuMoodLightIceBlueColorSelOnHU 0;
BA_ "GenSigTimeoutTime_IVI" SG_ 508 HuMoodLightIceBlueColorSelOnHU 0;
BA_ "GenSigTimeoutTime_HU_Mid_X451" SG_ 508 HuMoodLightTuscanRedColorSelOnHU 0;
BA_ "GenSigTimeoutTime_HU_High_X451" SG_ 508 HuMoodLightTuscanRedColorSelOnHU 0;
BA_ "GenSigTimeoutTime_HU_B" SG_ 508 HuMoodLightTuscanRedColorSelOnHU 0;
BA_ "GenSigTimeoutTime_HU_A" SG_ 508 HuMoodLightTuscanRedColorSelOnHU 0;
BA_ "GenSigTimeoutMsg_HU_Mid_X451" SG_ 508 HuMoodLightTuscanRedColorSelOnHU 0;
BA_ "GenSigTimeoutMsg_HU_High_X451" SG_ 508 HuMoodLightTuscanRedColorSelOnHU 0;
BA_ "GenSigTimeoutMsg_HU_B" SG_ 508 HuMoodLightTuscanRedColorSelOnHU 0;
BA_ "GenSigTimeoutMsg_HU_A" SG_ 508 HuMoodLightTuscanRedColorSelOnHU 0;
BA_ "GenSigSendType" SG_ 508 HuMoodLightTuscanRedColorSelOnHU 1;
BA_ "GenSigTimeoutMsg_HU_High_X445" SG_ 508 HuMoodLightTuscanRedColorSelOnHU 0;
BA_ "GenSigTimeoutMsg_HU_Mid_X445" SG_ 508 HuMoodLightTuscanRedColorSelOnHU 0;
BA_ "GenSigTimeoutTime_HU_High_X445" SG_ 508 HuMoodLightTuscanRedColorSelOnHU 0;
BA_ "GenSigTimeoutTime_HU_Mid_X445" SG_ 508 HuMoodLightTuscanRedColorSelOnHU 0;
BA_ "GenSigTimeoutMsg_IVI" SG_ 508 HuMoodLightTuscanRedColorSelOnHU 0;
BA_ "GenSigTimeoutTime_IVI" SG_ 508 HuMoodLightTuscanRedColorSelOnHU 0;
BA_ "GenSigTimeoutTime_HU_Mid_X451" SG_ 508 HuMoodLightTealGreenColorSelOnHU 0;
BA_ "GenSigTimeoutTime_HU_High_X451" SG_ 508 HuMoodLightTealGreenColorSelOnHU 0;
BA_ "GenSigTimeoutTime_HU_B" SG_ 508 HuMoodLightTealGreenColorSelOnHU 0;
BA_ "GenSigTimeoutTime_HU_A" SG_ 508 HuMoodLightTealGreenColorSelOnHU 0;
BA_ "GenSigTimeoutMsg_HU_Mid_X451" SG_ 508 HuMoodLightTealGreenColorSelOnHU 0;
BA_ "GenSigTimeoutMsg_HU_High_X451" SG_ 508 HuMoodLightTealGreenColorSelOnHU 0;
BA_ "GenSigTimeoutMsg_HU_B" SG_ 508 HuMoodLightTealGreenColorSelOnHU 0;
BA_ "GenSigTimeoutMsg_HU_A" SG_ 508 HuMoodLightTealGreenColorSelOnHU 0;
BA_ "GenSigSendType" SG_ 508 HuMoodLightTealGreenColorSelOnHU 1;
BA_ "GenSigTimeoutMsg_HU_High_X445" SG_ 508 HuMoodLightTealGreenColorSelOnHU 0;
BA_ "GenSigTimeoutMsg_HU_Mid_X445" SG_ 508 HuMoodLightTealGreenColorSelOnHU 0;
BA_ "GenSigTimeoutTime_HU_High_X445" SG_ 508 HuMoodLightTealGreenColorSelOnHU 0;
BA_ "GenSigTimeoutTime_HU_Mid_X445" SG_ 508 HuMoodLightTealGreenColorSelOnHU 0;
BA_ "GenSigTimeoutMsg_IVI" SG_ 508 HuMoodLightTealGreenColorSelOnHU 0;
BA_ "GenSigTimeoutTime_IVI" SG_ 508 HuMoodLightTealGreenColorSelOnHU 0;
BA_ "GenSigTimeoutTime_HU_Mid_X451" SG_ 508 HuMoodLightRubyRedColorSelOnHU 0;
BA_ "GenSigTimeoutTime_HU_High_X451" SG_ 508 HuMoodLightRubyRedColorSelOnHU 0;
BA_ "GenSigTimeoutTime_HU_B" SG_ 508 HuMoodLightRubyRedColorSelOnHU 0;
BA_ "GenSigTimeoutTime_HU_A" SG_ 508 HuMoodLightRubyRedColorSelOnHU 0;
BA_ "GenSigTimeoutMsg_HU_Mid_X451" SG_ 508 HuMoodLightRubyRedColorSelOnHU 0;
BA_ "GenSigTimeoutMsg_HU_High_X451" SG_ 508 HuMoodLightRubyRedColorSelOnHU 0;
BA_ "GenSigTimeoutMsg_HU_B" SG_ 508 HuMoodLightRubyRedColorSelOnHU 0;
BA_ "GenSigTimeoutMsg_HU_A" SG_ 508 HuMoodLightRubyRedColorSelOnHU 0;
BA_ "GenSigSendType" SG_ 508 HuMoodLightRubyRedColorSelOnHU 1;
BA_ "GenSigTimeoutMsg_HU_High_X445" SG_ 508 HuMoodLightRubyRedColorSelOnHU 0;
BA_ "GenSigTimeoutMsg_HU_Mid_X445" SG_ 508 HuMoodLightRubyRedColorSelOnHU 0;
BA_ "GenSigTimeoutTime_HU_High_X445" SG_ 508 HuMoodLightRubyRedColorSelOnHU 0;
BA_ "GenSigTimeoutTime_HU_Mid_X445" SG_ 508 HuMoodLightRubyRedColorSelOnHU 0;
BA_ "GenSigTimeoutMsg_IVI" SG_ 508 HuMoodLightRubyRedColorSelOnHU 0;
BA_ "GenSigTimeoutTime_IVI" SG_ 508 HuMoodLightRubyRedColorSelOnHU 0;
BA_ "GenSigTimeoutTime_HU_Mid_X451" SG_ 508 HuMoodLightOrangeColorSelOnHU 0;
BA_ "GenSigTimeoutTime_HU_High_X451" SG_ 508 HuMoodLightOrangeColorSelOnHU 0;
BA_ "GenSigTimeoutTime_HU_B" SG_ 508 HuMoodLightOrangeColorSelOnHU 0;
BA_ "GenSigTimeoutTime_HU_A" SG_ 508 HuMoodLightOrangeColorSelOnHU 0;
BA_ "GenSigTimeoutMsg_HU_Mid_X451" SG_ 508 HuMoodLightOrangeColorSelOnHU 0;
BA_ "GenSigTimeoutMsg_HU_High_X451" SG_ 508 HuMoodLightOrangeColorSelOnHU 0;
BA_ "GenSigTimeoutMsg_HU_B" SG_ 508 HuMoodLightOrangeColorSelOnHU 0;
BA_ "GenSigTimeoutMsg_HU_A" SG_ 508 HuMoodLightOrangeColorSelOnHU 0;
BA_ "GenSigSendType" SG_ 508 HuMoodLightOrangeColorSelOnHU 1;
BA_ "GenSigTimeoutMsg_HU_High_X445" SG_ 508 HuMoodLightOrangeColorSelOnHU 0;
BA_ "GenSigTimeoutMsg_HU_Mid_X445" SG_ 508 HuMoodLightOrangeColorSelOnHU 0;
BA_ "GenSigTimeoutTime_HU_High_X445" SG_ 508 HuMoodLightOrangeColorSelOnHU 0;
BA_ "GenSigTimeoutTime_HU_Mid_X445" SG_ 508 HuMoodLightOrangeColorSelOnHU 0;
BA_ "GenSigTimeoutMsg_IVI" SG_ 508 HuMoodLightOrangeColorSelOnHU 0;
BA_ "GenSigTimeoutTime_IVI" SG_ 508 HuMoodLightOrangeColorSelOnHU 0;
BA_ "GenSigTimeoutTime_HU_Mid_X451" SG_ 508 HuMoodLightPurpleTaupeSelOnHU 0;
BA_ "GenSigTimeoutTime_HU_High_X451" SG_ 508 HuMoodLightPurpleTaupeSelOnHU 0;
BA_ "GenSigTimeoutTime_HU_B" SG_ 508 HuMoodLightPurpleTaupeSelOnHU 0;
BA_ "GenSigTimeoutTime_HU_A" SG_ 508 HuMoodLightPurpleTaupeSelOnHU 0;
BA_ "GenSigTimeoutMsg_HU_Mid_X451" SG_ 508 HuMoodLightPurpleTaupeSelOnHU 0;
BA_ "GenSigTimeoutMsg_HU_High_X451" SG_ 508 HuMoodLightPurpleTaupeSelOnHU 0;
BA_ "GenSigTimeoutMsg_HU_B" SG_ 508 HuMoodLightPurpleTaupeSelOnHU 0;
BA_ "GenSigTimeoutMsg_HU_A" SG_ 508 HuMoodLightPurpleTaupeSelOnHU 0;
BA_ "GenSigSendType" SG_ 508 HuMoodLightPurpleTaupeSelOnHU 1;
BA_ "GenSigTimeoutMsg_HU_High_X445" SG_ 508 HuMoodLightPurpleTaupeSelOnHU 0;
BA_ "GenSigTimeoutMsg_HU_Mid_X445" SG_ 508 HuMoodLightPurpleTaupeSelOnHU 0;
BA_ "GenSigTimeoutTime_HU_High_X445" SG_ 508 HuMoodLightPurpleTaupeSelOnHU 0;
BA_ "GenSigTimeoutTime_HU_Mid_X445" SG_ 508 HuMoodLightPurpleTaupeSelOnHU 0;
BA_ "GenSigTimeoutMsg_IVI" SG_ 508 HuMoodLightPurpleTaupeSelOnHU 0;
BA_ "GenSigTimeoutTime_IVI" SG_ 508 HuMoodLightPurpleTaupeSelOnHU 0;
BA_ "GenSigTimeoutTime_HU_Mid_X451" SG_ 509 BCmAmbLightModeSelActiveVal 0;
BA_ "GenSigTimeoutTime_HU_High_X451" SG_ 509 BCmAmbLightModeSelActiveVal 0;
BA_ "GenSigTimeoutTime_HU_B" SG_ 509 BCmAmbLightModeSelActiveVal 0;
BA_ "GenSigTimeoutTime_HU_A" SG_ 509 BCmAmbLightModeSelActiveVal 0;
BA_ "GenSigTimeoutMsg_HU_Mid_X451" SG_ 509 BCmAmbLightModeSelActiveVal 0;
BA_ "GenSigTimeoutMsg_HU_High_X451" SG_ 509 BCmAmbLightModeSelActiveVal 0;
BA_ "GenSigTimeoutMsg_HU_B" SG_ 509 BCmAmbLightModeSelActiveVal 0;
BA_ "GenSigTimeoutMsg_HU_A" SG_ 509 BCmAmbLightModeSelActiveVal 0;
BA_ "GenSigSendType" SG_ 509 BCmAmbLightModeSelActiveVal 1;
BA_ "GenSigTimeoutMsg_HU_High_X445" SG_ 509 BCmAmbLightModeSelActiveVal 0;
BA_ "GenSigTimeoutMsg_HU_Mid_X445" SG_ 509 BCmAmbLightModeSelActiveVal 0;
BA_ "GenSigTimeoutTime_HU_High_X445" SG_ 509 BCmAmbLightModeSelActiveVal 0;
BA_ "GenSigTimeoutTime_HU_Mid_X445" SG_ 509 BCmAmbLightModeSelActiveVal 0;
BA_ "GenSigTimeoutMsg_IVI" SG_ 509 BCmAmbLightModeSelActiveVal 0;
BA_ "GenSigTimeoutTime_IVI" SG_ 509 BCmAmbLightModeSelActiveVal 0;
BA_ "GenSigTimeoutTime_HU_Mid_X451" SG_ 509 BCmAmbLightIllumSelActiveVal 0;
BA_ "GenSigTimeoutTime_HU_High_X451" SG_ 509 BCmAmbLightIllumSelActiveVal 0;
BA_ "GenSigTimeoutTime_HU_B" SG_ 509 BCmAmbLightIllumSelActiveVal 0;
BA_ "GenSigTimeoutTime_HU_A" SG_ 509 BCmAmbLightIllumSelActiveVal 0;
BA_ "GenSigTimeoutMsg_HU_Mid_X451" SG_ 509 BCmAmbLightIllumSelActiveVal 0;
BA_ "GenSigTimeoutMsg_HU_High_X451" SG_ 509 BCmAmbLightIllumSelActiveVal 0;
BA_ "GenSigTimeoutMsg_HU_B" SG_ 509 BCmAmbLightIllumSelActiveVal 0;
BA_ "GenSigTimeoutMsg_HU_A" SG_ 509 BCmAmbLightIllumSelActiveVal 0;
BA_ "GenSigStartValue" SG_ 509 BCmAmbLightIllumSelActiveVal 5;
BA_ "GenSigSendType" SG_ 509 BCmAmbLightIllumSelActiveVal 1;
BA_ "GenSigTimeoutMsg_HU_High_X445" SG_ 509 BCmAmbLightIllumSelActiveVal 0;
BA_ "GenSigTimeoutMsg_HU_Mid_X445" SG_ 509 BCmAmbLightIllumSelActiveVal 0;
BA_ "GenSigTimeoutTime_HU_High_X445" SG_ 509 BCmAmbLightIllumSelActiveVal 0;
BA_ "GenSigTimeoutTime_HU_Mid_X445" SG_ 509 BCmAmbLightIllumSelActiveVal 0;
BA_ "GenSigTimeoutMsg_IVI" SG_ 509 BCmAmbLightIllumSelActiveVal 0;
BA_ "GenSigTimeoutTime_IVI" SG_ 509 BCmAmbLightIllumSelActiveVal 0;
BA_ "GenSigTimeoutTime_HU_Mid_X451" SG_ 509 AmbLightIllumPossibleLevels 0;
BA_ "GenSigTimeoutTime_HU_High_X451" SG_ 509 AmbLightIllumPossibleLevels 0;
BA_ "GenSigTimeoutTime_HU_B" SG_ 509 AmbLightIllumPossibleLevels 0;
BA_ "GenSigTimeoutTime_HU_A" SG_ 509 AmbLightIllumPossibleLevels 0;
BA_ "GenSigTimeoutMsg_HU_Mid_X451" SG_ 509 AmbLightIllumPossibleLevels 0;
BA_ "GenSigTimeoutMsg_HU_High_X451" SG_ 509 AmbLightIllumPossibleLevels 0;
BA_ "GenSigTimeoutMsg_HU_B" SG_ 509 AmbLightIllumPossibleLevels 0;
BA_ "GenSigTimeoutMsg_HU_A" SG_ 509 AmbLightIllumPossibleLevels 0;
BA_ "GenSigStartValue" SG_ 509 AmbLightIllumPossibleLevels 5;
BA_ "GenSigSendType" SG_ 509 AmbLightIllumPossibleLevels 1;
BA_ "GenSigTimeoutMsg_HU_High_X445" SG_ 509 AmbLightIllumPossibleLevels 0;
BA_ "GenSigTimeoutMsg_HU_Mid_X445" SG_ 509 AmbLightIllumPossibleLevels 0;
BA_ "GenSigTimeoutTime_HU_High_X445" SG_ 509 AmbLightIllumPossibleLevels 0;
BA_ "GenSigTimeoutTime_HU_Mid_X445" SG_ 509 AmbLightIllumPossibleLevels 0;
BA_ "GenSigTimeoutMsg_IVI" SG_ 509 AmbLightIllumPossibleLevels 0;
BA_ "GenSigTimeoutTime_IVI" SG_ 509 AmbLightIllumPossibleLevels 0;
BA_ "GenSigTimeoutTime_HU_Mid_X451" SG_ 509 AmbLightModeIllumOnHu 0;
BA_ "GenSigTimeoutTime_HU_High_X451" SG_ 509 AmbLightModeIllumOnHu 0;
BA_ "GenSigTimeoutTime_HU_B" SG_ 509 AmbLightModeIllumOnHu 0;
BA_ "GenSigTimeoutTime_HU_A" SG_ 509 AmbLightModeIllumOnHu 0;
BA_ "GenSigTimeoutMsg_HU_Mid_X451" SG_ 509 AmbLightModeIllumOnHu 0;
BA_ "GenSigTimeoutMsg_HU_High_X451" SG_ 509 AmbLightModeIllumOnHu 0;
BA_ "GenSigTimeoutMsg_HU_B" SG_ 509 AmbLightModeIllumOnHu 0;
BA_ "GenSigTimeoutMsg_HU_A" SG_ 509 AmbLightModeIllumOnHu 0;
BA_ "GenSigSendType" SG_ 509 AmbLightModeIllumOnHu 1;
BA_ "GenSigTimeoutMsg_HU_High_X445" SG_ 509 AmbLightModeIllumOnHu 0;
BA_ "GenSigTimeoutMsg_HU_Mid_X445" SG_ 509 AmbLightModeIllumOnHu 0;
BA_ "GenSigTimeoutTime_HU_High_X445" SG_ 509 AmbLightModeIllumOnHu 0;
BA_ "GenSigTimeoutTime_HU_Mid_X445" SG_ 509 AmbLightModeIllumOnHu 0;
BA_ "GenSigTimeoutMsg_IVI" SG_ 509 AmbLightModeIllumOnHu 0;
BA_ "GenSigTimeoutTime_IVI" SG_ 509 AmbLightModeIllumOnHu 0;
BA_ "GenSigTimeoutTime_HU_Mid_X451" SG_ 509 BCmAmbLightData 0;
BA_ "GenSigTimeoutTime_HU_High_X451" SG_ 509 BCmAmbLightData 0;
BA_ "GenSigTimeoutTime_HU_B" SG_ 509 BCmAmbLightData 0;
BA_ "GenSigTimeoutTime_HU_A" SG_ 509 BCmAmbLightData 0;
BA_ "GenSigTimeoutMsg_HU_Mid_X451" SG_ 509 BCmAmbLightData 0;
BA_ "GenSigTimeoutMsg_HU_High_X451" SG_ 509 BCmAmbLightData 0;
BA_ "GenSigTimeoutMsg_HU_B" SG_ 509 BCmAmbLightData 0;
BA_ "GenSigTimeoutMsg_HU_A" SG_ 509 BCmAmbLightData 0;
BA_ "GenSigStartValue" SG_ 509 BCmAmbLightData 2;
BA_ "GenSigSendType" SG_ 509 BCmAmbLightData 1;
BA_ "GenSigTimeoutMsg_HU_High_X445" SG_ 509 BCmAmbLightData 0;
BA_ "GenSigTimeoutMsg_HU_Mid_X445" SG_ 509 BCmAmbLightData 0;
BA_ "GenSigTimeoutTime_HU_High_X445" SG_ 509 BCmAmbLightData 0;
BA_ "GenSigTimeoutTime_HU_Mid_X445" SG_ 509 BCmAmbLightData 0;
BA_ "GenSigTimeoutMsg_IVI" SG_ 509 BCmAmbLightData 0;
BA_ "GenSigTimeoutTime_IVI" SG_ 509 BCmAmbLightData 0;
BA_ "GenSigTimeoutTime_HU_Mid_X451" SG_ 510 HuAmbLightModeSelActiveVal 0;
BA_ "GenSigTimeoutTime_HU_High_X451" SG_ 510 HuAmbLightModeSelActiveVal 0;
BA_ "GenSigTimeoutTime_HU_B" SG_ 510 HuAmbLightModeSelActiveVal 0;
BA_ "GenSigTimeoutTime_HU_A" SG_ 510 HuAmbLightModeSelActiveVal 0;
BA_ "GenSigTimeoutMsg_HU_Mid_X451" SG_ 510 HuAmbLightModeSelActiveVal 0;
BA_ "GenSigTimeoutMsg_HU_High_X451" SG_ 510 HuAmbLightModeSelActiveVal 0;
BA_ "GenSigTimeoutMsg_HU_B" SG_ 510 HuAmbLightModeSelActiveVal 0;
BA_ "GenSigTimeoutMsg_HU_A" SG_ 510 HuAmbLightModeSelActiveVal 0;
BA_ "GenSigSendType" SG_ 510 HuAmbLightModeSelActiveVal 1;
BA_ "GenSigTimeoutMsg_HU_High_X445" SG_ 510 HuAmbLightModeSelActiveVal 0;
BA_ "GenSigTimeoutMsg_HU_Mid_X445" SG_ 510 HuAmbLightModeSelActiveVal 0;
BA_ "GenSigTimeoutTime_HU_High_X445" SG_ 510 HuAmbLightModeSelActiveVal 0;
BA_ "GenSigTimeoutTime_HU_Mid_X445" SG_ 510 HuAmbLightModeSelActiveVal 0;
BA_ "GenSigTimeoutMsg_IVI" SG_ 510 HuAmbLightModeSelActiveVal 0;
BA_ "GenSigTimeoutTime_IVI" SG_ 510 HuAmbLightModeSelActiveVal 0;
BA_ "GenSigTimeoutTime_HU_Mid_X451" SG_ 510 HuAmbLightIllumSelActiveVal 0;
BA_ "GenSigTimeoutTime_HU_High_X451" SG_ 510 HuAmbLightIllumSelActiveVal 0;
BA_ "GenSigTimeoutTime_HU_B" SG_ 510 HuAmbLightIllumSelActiveVal 0;
BA_ "GenSigTimeoutTime_HU_A" SG_ 510 HuAmbLightIllumSelActiveVal 0;
BA_ "GenSigTimeoutMsg_HU_Mid_X451" SG_ 510 HuAmbLightIllumSelActiveVal 0;
BA_ "GenSigTimeoutMsg_HU_High_X451" SG_ 510 HuAmbLightIllumSelActiveVal 0;
BA_ "GenSigTimeoutMsg_HU_B" SG_ 510 HuAmbLightIllumSelActiveVal 0;
BA_ "GenSigTimeoutMsg_HU_A" SG_ 510 HuAmbLightIllumSelActiveVal 0;
BA_ "GenSigSendType" SG_ 510 HuAmbLightIllumSelActiveVal 1;
BA_ "GenSigTimeoutMsg_HU_High_X445" SG_ 510 HuAmbLightIllumSelActiveVal 0;
BA_ "GenSigTimeoutMsg_HU_Mid_X445" SG_ 510 HuAmbLightIllumSelActiveVal 0;
BA_ "GenSigTimeoutTime_HU_High_X445" SG_ 510 HuAmbLightIllumSelActiveVal 0;
BA_ "GenSigTimeoutTime_HU_Mid_X445" SG_ 510 HuAmbLightIllumSelActiveVal 0;
BA_ "GenSigTimeoutMsg_IVI" SG_ 510 HuAmbLightIllumSelActiveVal 0;
BA_ "GenSigTimeoutTime_IVI" SG_ 510 HuAmbLightIllumSelActiveVal 0;
BA_ "GenSigTimeoutTime_HU_Mid_X451" SG_ 510 HuAmbLightIllumPossibleLevels 0;
BA_ "GenSigTimeoutTime_HU_High_X451" SG_ 510 HuAmbLightIllumPossibleLevels 0;
BA_ "GenSigTimeoutTime_HU_B" SG_ 510 HuAmbLightIllumPossibleLevels 0;
BA_ "GenSigTimeoutTime_HU_A" SG_ 510 HuAmbLightIllumPossibleLevels 0;
BA_ "GenSigTimeoutMsg_HU_Mid_X451" SG_ 510 HuAmbLightIllumPossibleLevels 0;
BA_ "GenSigTimeoutMsg_HU_High_X451" SG_ 510 HuAmbLightIllumPossibleLevels 0;
BA_ "GenSigTimeoutMsg_HU_B" SG_ 510 HuAmbLightIllumPossibleLevels 0;
BA_ "GenSigTimeoutMsg_HU_A" SG_ 510 HuAmbLightIllumPossibleLevels 0;
BA_ "GenSigSendType" SG_ 510 HuAmbLightIllumPossibleLevels 1;
BA_ "GenSigTimeoutMsg_HU_High_X445" SG_ 510 HuAmbLightIllumPossibleLevels 0;
BA_ "GenSigTimeoutMsg_HU_Mid_X445" SG_ 510 HuAmbLightIllumPossibleLevels 0;
BA_ "GenSigTimeoutTime_HU_High_X445" SG_ 510 HuAmbLightIllumPossibleLevels 0;
BA_ "GenSigTimeoutTime_HU_Mid_X445" SG_ 510 HuAmbLightIllumPossibleLevels 0;
BA_ "GenSigTimeoutMsg_IVI" SG_ 510 HuAmbLightIllumPossibleLevels 0;
BA_ "GenSigTimeoutTime_IVI" SG_ 510 HuAmbLightIllumPossibleLevels 0;
BA_ "GenSigTimeoutTime_HU_Mid_X451" SG_ 510 HuAmbLightData 0;
BA_ "GenSigTimeoutTime_HU_High_X451" SG_ 510 HuAmbLightData 0;
BA_ "GenSigTimeoutTime_HU_B" SG_ 510 HuAmbLightData 0;
BA_ "GenSigTimeoutTime_HU_A" SG_ 510 HuAmbLightData 0;
BA_ "GenSigTimeoutMsg_HU_Mid_X451" SG_ 510 HuAmbLightData 0;
BA_ "GenSigTimeoutMsg_HU_High_X451" SG_ 510 HuAmbLightData 0;
BA_ "GenSigTimeoutMsg_HU_B" SG_ 510 HuAmbLightData 0;
BA_ "GenSigTimeoutMsg_HU_A" SG_ 510 HuAmbLightData 0;
BA_ "GenSigSendType" SG_ 510 HuAmbLightData 1;
BA_ "GenSigTimeoutMsg_HU_High_X445" SG_ 510 HuAmbLightData 0;
BA_ "GenSigTimeoutMsg_HU_Mid_X445" SG_ 510 HuAmbLightData 0;
BA_ "GenSigTimeoutTime_HU_High_X445" SG_ 510 HuAmbLightData 0;
BA_ "GenSigTimeoutTime_HU_Mid_X445" SG_ 510 HuAmbLightData 0;
BA_ "GenSigTimeoutMsg_IVI" SG_ 510 HuAmbLightData 0;
BA_ "GenSigTimeoutTime_IVI" SG_ 510 HuAmbLightData 0;
BA_ "GenSigSendType" SG_ 571 ColorThemeAutolearning 7;
BA_ "GenSigCycleTimeActive" SG_ 571 ColorThemeAutolearning 50;
BA_ "GenSigCycleTime" SG_ 571 ColorThemeAutolearning 50;
BA_ "GenSigSendType" SG_ 571 ColorThemeCoDrvr 7;
BA_ "GenSigCycleTimeActive" SG_ 571 ColorThemeCoDrvr 50;
BA_ "GenSigCycleTime" SG_ 571 ColorThemeCoDrvr 50;
BA_ "GenSigSendType" SG_ 571 ColorThemeDrvr 7;
BA_ "GenSigCycleTimeActive" SG_ 571 ColorThemeDrvr 50;
BA_ "GenSigCycleTime" SG_ 571 ColorThemeDrvr 50;
BA_ "GenSigSendType" SG_ 571 CcmHuRearBlwrOnOffState 7;
BA_ "GenSigCycleTimeActive" SG_ 571 CcmHuRearBlwrOnOffState 50;
BA_ "GenSigCycleTime" SG_ 571 CcmHuRearBlwrOnOffState 50;
BA_ "GenSigSendType" SG_ 571 CcmHuUserInterventionBeep 7;
BA_ "GenSigCycleTimeActive" SG_ 571 CcmHuUserInterventionBeep 50;
BA_ "GenSigCycleTime" SG_ 571 CcmHuUserInterventionBeep 50;
BA_ "GenSigSendType" SG_ 571 AutoDefogState 7;
BA_ "GenSigCycleTimeActive" SG_ 571 AutoDefogState 50;
BA_ "GenSigCycleTime" SG_ 571 AutoDefogState 50;
BA_ "GenSigSendType" SG_ 571 AutoDefogFeature 7;
BA_ "GenSigCycleTimeActive" SG_ 571 AutoDefogFeature 50;
BA_ "GenSigCycleTime" SG_ 571 AutoDefogFeature 50;
BA_ "GenSigSendType" SG_ 571 CCmExpressCoolVoiceAlert 7;
BA_ "GenSigCycleTimeActive" SG_ 571 CCmExpressCoolVoiceAlert 50;
BA_ "GenSigCycleTime" SG_ 571 CCmExpressCoolVoiceAlert 50;
BA_ "GenSigSendType" SG_ 571 CCmHuExpressCoolSwitchStatus 7;
BA_ "GenSigCycleTimeActive" SG_ 571 CCmHuExpressCoolSwitchStatus 50;
BA_ "GenSigCycleTime" SG_ 571 CCmHuExpressCoolSwitchStatus 50;
BA_ "GenSigSendType" SG_ 571 CCmWindowUpDown 7;
BA_ "GenSigCycleTimeActive" SG_ 571 CCmWindowUpDown 50;
BA_ "GenSigCycleTime" SG_ 571 CCmWindowUpDown 50;
BA_ "GenSigSendType" SG_ 571 CCmHuFanSpdStatus 7;
BA_ "GenSigCycleTimeActive" SG_ 571 CCmHuFanSpdStatus 50;
BA_ "GenSigCycleTime" SG_ 571 CCmHuFanSpdStatus 50;
BA_ "GenSigSendType" SG_ 571 CCmHuDistribSwitchStatus 7;
BA_ "GenSigCycleTimeActive" SG_ 571 CCmHuDistribSwitchStatus 50;
BA_ "GenSigCycleTime" SG_ 571 CCmHuDistribSwitchStatus 50;
BA_ "GenSigSendType" SG_ 571 CCmHuDualModeSwStatus 7;
BA_ "GenSigCycleTimeActive" SG_ 571 CCmHuDualModeSwStatus 50;
BA_ "GenSigCycleTime" SG_ 571 CCmHuDualModeSwStatus 50;
BA_ "GenSigSendType" SG_ 571 CCmHuTempWhlStatusPass 7;
BA_ "GenSigCycleTimeActive" SG_ 571 CCmHuTempWhlStatusPass 50;
BA_ "GenSigCycleTime" SG_ 571 CCmHuTempWhlStatusPass 50;
BA_ "GenSigSendType" SG_ 571 CCMHuFreshAirRecircSwitchStatus 7;
BA_ "GenSigCycleTimeActive" SG_ 571 CCMHuFreshAirRecircSwitchStatus 50;
BA_ "GenSigCycleTime" SG_ 571 CCMHuFreshAirRecircSwitchStatus 50;
BA_ "GenSigSendType" SG_ 571 CCmHuAutoSwitchStatus 7;
BA_ "GenSigCycleTimeActive" SG_ 571 CCmHuAutoSwitchStatus 50;
BA_ "GenSigCycleTime" SG_ 571 CCmHuAutoSwitchStatus 50;
BA_ "GenSigSendType" SG_ 571 CCmHuTempWhlStatus 7;
BA_ "GenSigCycleTimeActive" SG_ 571 CCmHuTempWhlStatus 50;
BA_ "GenSigCycleTime" SG_ 571 CCmHuTempWhlStatus 50;
BA_ "GenSigSendType" SG_ 571 CCmHuEconModeSwitchStatus 7;
BA_ "GenSigCycleTimeActive" SG_ 571 CCmHuEconModeSwitchStatus 50;
BA_ "GenSigCycleTime" SG_ 571 CCmHuEconModeSwitchStatus 50;
BA_ "GenSigSendType" SG_ 571 CCmHuMaxDefrstSwitchStatus 7;
BA_ "GenSigCycleTimeActive" SG_ 571 CCmHuMaxDefrstSwitchStatus 50;
BA_ "GenSigCycleTime" SG_ 571 CCmHuMaxDefrstSwitchStatus 50;
BA_ "GenSigSendType" SG_ 571 CCmHuRearDefogSwitchStatus 7;
BA_ "GenSigCycleTimeActive" SG_ 571 CCmHuRearDefogSwitchStatus 50;
BA_ "GenSigCycleTime" SG_ 571 CCmHuRearDefogSwitchStatus 50;
BA_ "GenSigSendType" SG_ 571 CCmHuTempWhlStatusDrvr 7;
BA_ "GenSigCycleTimeActive" SG_ 571 CCmHuTempWhlStatusDrvr 50;
BA_ "GenSigCycleTime" SG_ 571 CCmHuTempWhlStatusDrvr 50;
BA_ "GenSigSendType" SG_ 571 CCmHuAirConCompSwitchStatus 7;
BA_ "GenSigCycleTimeActive" SG_ 571 CCmHuAirConCompSwitchStatus 50;
BA_ "GenSigCycleTime" SG_ 571 CCmHuAirConCompSwitchStatus 50;
BA_ "GenSigSendType" SG_ 571 CCmHuCtrlPnlStatus 7;
BA_ "GenSigCycleTimeActive" SG_ 571 CCmHuCtrlPnlStatus 50;
BA_ "GenSigCycleTime" SG_ 571 CCmHuCtrlPnlStatus 50;
BA_ "GenSigSendType" SG_ 571 CCmHuChangeBit 7;
BA_ "GenSigCycleTimeActive" SG_ 571 CCmHuChangeBit 50;
BA_ "GenSigCycleTime" SG_ 571 CCmHuChangeBit 50;
BA_ "GenSigSendType" SG_ 571 CCmHuUserInterventionStatusFlag 7;
BA_ "GenSigCycleTimeActive" SG_ 571 CCmHuUserInterventionStatusFlag 50;
BA_ "GenSigCycleTime" SG_ 571 CCmHuUserInterventionStatusFlag 50;
BA_ "GenSigSendType" SG_ 571 CCmHuTempWhlStatusStatus 7;
BA_ "GenSigCycleTimeActive" SG_ 571 CCmHuTempWhlStatusStatus 50;
BA_ "GenSigCycleTime" SG_ 571 CCmHuTempWhlStatusStatus 50;
BA_ "GenSigSendType" SG_ 571 CCmHuErrStatus 7;
BA_ "GenSigCycleTimeActive" SG_ 571 CCmHuErrStatus 50;
BA_ "GenSigCycleTime" SG_ 571 CCmHuErrStatus 50;
BA_ "GenSigSendType" SG_ 571 CCmHuDualModeSwStatusStatus 7;
BA_ "GenSigCycleTimeActive" SG_ 571 CCmHuDualModeSwStatusStatus 50;
BA_ "GenSigCycleTime" SG_ 571 CCmHuDualModeSwStatusStatus 50;
BA_ "GenSigSendType" SG_ 571 CCmHuTempWhlStatusPassStatus 7;
BA_ "GenSigCycleTimeActive" SG_ 571 CCmHuTempWhlStatusPassStatus 50;
BA_ "GenSigCycleTime" SG_ 571 CCmHuTempWhlStatusPassStatus 50;
BA_ "GenSigSendType" SG_ 571 CCmHuTempWhlStatusDrvrStatus 7;
BA_ "GenSigCycleTimeActive" SG_ 571 CCmHuTempWhlStatusDrvrStatus 50;
BA_ "GenSigCycleTime" SG_ 571 CCmHuTempWhlStatusDrvrStatus 50;
BA_ "Remarks" SG_ 573 LockStateESCL "*";
BA_ "GenSigTimeoutTime_HU_B" SG_ 573 LockStateESCL 0;
BA_ "GenSigTimeoutTime_HU_A" SG_ 573 LockStateESCL 0;
BA_ "GenSigTimeoutMsg_HU_B" SG_ 573 LockStateESCL 0;
BA_ "GenSigTimeoutMsg_HU_A" SG_ 573 LockStateESCL 0;
BA_ "GenSigSendType" SG_ 573 LockStateESCL 7;
BA_ "GenSigCycleTimeActive" SG_ 573 LockStateESCL 50;
BA_ "GenSigCycleTime" SG_ 573 LockStateESCL 50;
BA_ "Remarks" SG_ 573 UnlockStateESCL "*";
BA_ "GenSigTimeoutTime_HU_B" SG_ 573 UnlockStateESCL 0;
BA_ "GenSigTimeoutTime_HU_A" SG_ 573 UnlockStateESCL 0;
BA_ "GenSigTimeoutMsg_HU_B" SG_ 573 UnlockStateESCL 0;
BA_ "GenSigTimeoutMsg_HU_A" SG_ 573 UnlockStateESCL 0;
BA_ "GenSigSendType" SG_ 573 UnlockStateESCL 7;
BA_ "GenSigCycleTimeActive" SG_ 573 UnlockStateESCL 50;
BA_ "GenSigCycleTime" SG_ 573 UnlockStateESCL 50;
BA_ "Remarks" SG_ 573 ESClTextRotateSteeringWheel "*";
BA_ "GenSigSendType" SG_ 573 ESClTextRotateSteeringWheel 7;
BA_ "GenSigCycleTimeActive" SG_ 573 ESClTextRotateSteeringWheel 50;
BA_ "GenSigCycleTime" SG_ 573 ESClTextRotateSteeringWheel 50;
BA_ "Remarks" SG_ 573 ESClTextDefect "*";
BA_ "GenSigSendType" SG_ 573 ESClTextDefect 7;
BA_ "GenSigCycleTimeActive" SG_ 573 ESClTextDefect 50;
BA_ "GenSigCycleTime" SG_ 573 ESClTextDefect 50;
BA_ "Remarks" SG_ 573 ESClTextGarage "*";
BA_ "GenSigSendType" SG_ 573 ESClTextGarage 7;
BA_ "GenSigCycleTimeActive" SG_ 573 ESClTextGarage 50;
BA_ "GenSigCycleTime" SG_ 573 ESClTextGarage 50;
BA_ "GenSigTimeoutTime_HU_B" SG_ 614 ModeSelectionSwStateStatus 0;
BA_ "GenSigTimeoutTime_HU_A" SG_ 614 ModeSelectionSwStateStatus 0;
BA_ "GenSigTimeoutMsg_HU_B" SG_ 614 ModeSelectionSwStateStatus 0;
BA_ "GenSigTimeoutMsg_HU_A" SG_ 614 ModeSelectionSwStateStatus 0;
BA_ "GenSigSendType" SG_ 614 ModeSelectionSwStateStatus 7;
BA_ "GenSigCycleTimeActive" SG_ 614 ModeSelectionSwStateStatus 100;
BA_ "GenSigCycleTime" SG_ 614 ModeSelectionSwStateStatus 100;
BA_ "GenSigTimeoutTime_HU_B" SG_ 614 ModeSelectionSwState 0;
BA_ "GenSigTimeoutTime_HU_A" SG_ 614 ModeSelectionSwState 0;
BA_ "GenSigTimeoutMsg_HU_B" SG_ 614 ModeSelectionSwState 0;
BA_ "GenSigTimeoutMsg_HU_A" SG_ 614 ModeSelectionSwState 0;
BA_ "GenSigSendType" SG_ 614 ModeSelectionSwState 7;
BA_ "GenSigCycleTimeActive" SG_ 614 ModeSelectionSwState 100;
BA_ "GenSigCycleTime" SG_ 614 ModeSelectionSwState 100;
BA_ "GenSigSendType" SG_ 614 DCSDrvModeConfigVariant 7;
BA_ "GenSigCycleTimeActive" SG_ 614 DCSDrvModeConfigVariant 100;
BA_ "GenSigCycleTime" SG_ 614 DCSDrvModeConfigVariant 100;
BA_ "GenSigSendType" SG_ 614 DCSFailureModes 7;
BA_ "GenSigCycleTimeActive" SG_ 614 DCSFailureModes 100;
BA_ "GenSigCycleTime" SG_ 614 DCSFailureModes 100;
BA_ "GenSigTimeoutTime_HU_B" SG_ 616 ModeSelectionSwStateStatusNew 0;
BA_ "GenSigTimeoutTime_HU_A" SG_ 616 ModeSelectionSwStateStatusNew 0;
BA_ "GenSigTimeoutMsg_HU_B" SG_ 616 ModeSelectionSwStateStatusNew 0;
BA_ "GenSigTimeoutMsg_HU_A" SG_ 616 ModeSelectionSwStateStatusNew 0;
BA_ "GenSigSendType" SG_ 616 ModeSelectionSwStateStatusNew 7;
BA_ "GenSigCycleTimeActive" SG_ 616 ModeSelectionSwStateStatusNew 100;
BA_ "GenSigCycleTime" SG_ 616 ModeSelectionSwStateStatusNew 100;
BA_ "GenSigTimeoutTime_HU_B" SG_ 616 ModeSelectionSwStateNew 0;
BA_ "GenSigTimeoutTime_HU_A" SG_ 616 ModeSelectionSwStateNew 0;
BA_ "GenSigTimeoutMsg_HU_B" SG_ 616 ModeSelectionSwStateNew 0;
BA_ "GenSigTimeoutMsg_HU_A" SG_ 616 ModeSelectionSwStateNew 0;
BA_ "GenSigSendType" SG_ 616 ModeSelectionSwStateNew 7;
BA_ "GenSigCycleTimeActive" SG_ 616 ModeSelectionSwStateNew 100;
BA_ "GenSigCycleTime" SG_ 616 ModeSelectionSwStateNew 100;
BA_ "GenSigSendType" SG_ 616 DCSFailureModesNew 7;
BA_ "GenSigCycleTimeActive" SG_ 616 DCSFailureModesNew 100;
BA_ "GenSigCycleTime" SG_ 616 DCSFailureModesNew 100;
BA_ "GenSigSendType" SG_ 638 CngTnkPresSts 7;
BA_ "GenSigCycleTimeActive" SG_ 638 CngTnkPresSts 100;
BA_ "GenSigCycleTime" SG_ 638 CngTnkPresSts 100;
BA_ "GenSigSendType" SG_ 638 CngTnkPres 7;
BA_ "GenSigCycleTimeActive" SG_ 638 CngTnkPres 100;
BA_ "GenSigCycleTime" SG_ 638 CngTnkPres 100;
BA_ "GenSigSendType" SG_ 638 CNGSwitchState 7;
BA_ "GenSigCycleTimeActive" SG_ 638 CNGSwitchState 100;
BA_ "GenSigCycleTime" SG_ 638 CNGSwitchState 100;
BA_ "GenSigSendType" SG_ 638 EngFuelMode 7;
BA_ "GenSigCycleTimeActive" SG_ 638 EngFuelMode 100;
BA_ "GenSigCycleTime" SG_ 638 EngFuelMode 100;
BA_ "GenSigSendType" SG_ 638 CngErrMsgUserInfo 7;
BA_ "GenSigCycleTimeActive" SG_ 638 CngErrMsgUserInfo 100;
BA_ "GenSigCycleTime" SG_ 638 CngErrMsgUserInfo 100;
BA_ "GenSigSendType" SG_ 638 CngStatus 7;
BA_ "GenSigCycleTimeActive" SG_ 638 CngStatus 100;
BA_ "GenSigCycleTime" SG_ 638 CngStatus 100;
BA_ "GenSigSendType" SG_ 638 CngFuelLevelStatus 7;
BA_ "GenSigCycleTimeActive" SG_ 638 CngFuelLevelStatus 100;
BA_ "GenSigCycleTime" SG_ 638 CngFuelLevelStatus 100;
BA_ "GenSigSendType" SG_ 638 CngFuelLevel 7;
BA_ "GenSigCycleTimeActive" SG_ 638 CngFuelLevel 100;
BA_ "GenSigCycleTime" SG_ 638 CngFuelLevel 100;
BA_ "GenSigSendType" SG_ 638 FuelConsCngStatus 7;
BA_ "GenSigCycleTimeActive" SG_ 638 FuelConsCngStatus 100;
BA_ "GenSigCycleTime" SG_ 638 FuelConsCngStatus 100;
BA_ "GenSigSendType" SG_ 638 FuelConsCng 7;
BA_ "GenSigCycleTimeActive" SG_ 638 FuelConsCng 100;
BA_ "GenSigCycleTime" SG_ 638 FuelConsCng 100;
BA_ "GenSigSendType" SG_ 640 EngCrsCntrlModeNew 7;
BA_ "GenSigCycleTimeActive" SG_ 640 EngCrsCntrlModeNew 100;
BA_ "GenSigCycleTime" SG_ 640 EngCrsCntrlModeNew 100;
BA_ "GenSigSendType" SG_ 640 EngSpd_EMS 7;
BA_ "GenSigCycleTimeActive" SG_ 640 EngSpd_EMS 100;
BA_ "GenSigCycleTime" SG_ 640 EngSpd_EMS 100;
BA_ "GenSigSendType" SG_ 640 EngSpd_EMS_Status 7;
BA_ "GenSigCycleTimeActive" SG_ 640 EngSpd_EMS_Status 100;
BA_ "GenSigCycleTime" SG_ 640 EngSpd_EMS_Status 100;
BA_ "GenSigSendType" SG_ 640 FuelCons 7;
BA_ "GenSigCycleTimeActive" SG_ 640 FuelCons 100;
BA_ "GenSigCycleTime" SG_ 640 FuelCons 100;
BA_ "GenSigStartValue" SG_ 640 ClntTemp 40;
BA_ "GenSigSendType" SG_ 640 ClntTemp 7;
BA_ "GenSigCycleTimeActive" SG_ 640 ClntTemp 100;
BA_ "GenSigCycleTime" SG_ 640 ClntTemp 100;
BA_ "GenSigSendType" SG_ 640 EngineOilPrLamp 7;
BA_ "GenSigCycleTimeActive" SG_ 640 EngineOilPrLamp 100;
BA_ "GenSigCycleTime" SG_ 640 EngineOilPrLamp 100;
BA_ "GenSigSendType" SG_ 640 FilterClLamp 7;
BA_ "GenSigCycleTimeActive" SG_ 640 FilterClLamp 100;
BA_ "GenSigCycleTime" SG_ 640 FilterClLamp 100;
BA_ "GenSigSendType" SG_ 640 BattChrgLampStatus 7;
BA_ "GenSigCycleTimeActive" SG_ 640 BattChrgLampStatus 100;
BA_ "GenSigCycleTime" SG_ 640 BattChrgLampStatus 100;
BA_ "GenSigSendType" SG_ 640 ClntTempStatus 7;
BA_ "GenSigCycleTimeActive" SG_ 640 ClntTempStatus 100;
BA_ "GenSigCycleTime" SG_ 640 ClntTempStatus 100;
BA_ "GenSigSendType" SG_ 640 GlowPlugLampState 7;
BA_ "GenSigCycleTimeActive" SG_ 640 GlowPlugLampState 100;
BA_ "GenSigCycleTime" SG_ 640 GlowPlugLampState 100;
BA_ "GenSigSendType" SG_ 640 EngineOilPrLampStatus 7;
BA_ "GenSigCycleTimeActive" SG_ 640 EngineOilPrLampStatus 100;
BA_ "GenSigCycleTime" SG_ 640 EngineOilPrLampStatus 100;
BA_ "GenSigSendType" SG_ 640 WIfLampState 7;
BA_ "GenSigCycleTimeActive" SG_ 640 WIfLampState 100;
BA_ "GenSigCycleTime" SG_ 640 WIfLampState 100;
BA_ "GenSigTimeoutTime_HU_B" SG_ 640 ECmBackdoormode 0;
BA_ "GenSigTimeoutTime_HU_A" SG_ 640 ECmBackdoormode 0;
BA_ "GenSigTimeoutMsg_HU_B" SG_ 640 ECmBackdoormode 0;
BA_ "GenSigTimeoutMsg_HU_A" SG_ 640 ECmBackdoormode 0;
BA_ "GenSigSendType" SG_ 640 ECmBackdoormode 7;
BA_ "GenSigCycleTimeActive" SG_ 640 ECmBackdoormode 100;
BA_ "GenSigCycleTime" SG_ 640 ECmBackdoormode 100;
BA_ "GenSigSendType" SG_ 640 FuelConsStatus 7;
BA_ "GenSigCycleTimeActive" SG_ 640 FuelConsStatus 100;
BA_ "GenSigCycleTime" SG_ 640 FuelConsStatus 100;
BA_ "GenSigSendType" SG_ 640 BattChrgLampState 7;
BA_ "GenSigCycleTimeActive" SG_ 640 BattChrgLampState 100;
BA_ "GenSigCycleTime" SG_ 640 BattChrgLampState 100;
BA_ "GenSigSendType" SG_ 640 DPfState 7;
BA_ "GenSigCycleTimeActive" SG_ 640 DPfState 100;
BA_ "GenSigCycleTime" SG_ 640 DPfState 100;
BA_ "GenSigSendType" SG_ 640 ClntTempHigh 7;
BA_ "GenSigCycleTimeActive" SG_ 640 ClntTempHigh 100;
BA_ "GenSigCycleTime" SG_ 640 ClntTempHigh 100;
BA_ "GenSigSendType" SG_ 640 ImmoStatus 7;
BA_ "GenSigCycleTimeActive" SG_ 640 ImmoStatus 100;
BA_ "GenSigCycleTime" SG_ 640 ImmoStatus 100;
BA_ "GenSigSendType" SG_ 640 MiLampState 7;
BA_ "GenSigCycleTimeActive" SG_ 640 MiLampState 100;
BA_ "GenSigCycleTime" SG_ 640 MiLampState 100;
BA_ "GenSigSendType" SG_ 643 CruiseDispStatus 7;
BA_ "GenSigCycleTimeActive" SG_ 643 CruiseDispStatus 100;
BA_ "GenSigCycleTime" SG_ 643 CruiseDispStatus 100;
BA_ "GenSigSendType" SG_ 643 CruiseDisp 7;
BA_ "GenSigCycleTimeActive" SG_ 643 CruiseDisp 100;
BA_ "GenSigCycleTime" SG_ 643 CruiseDisp 100;
BA_ "GenSigTimeoutTime_HU_Mid_X451" SG_ 643 BattPerSoC 0;
BA_ "GenSigTimeoutTime_HU_High_X451" SG_ 643 BattPerSoC 0;
BA_ "GenSigTimeoutTime_HU_B" SG_ 643 BattPerSoC 0;
BA_ "GenSigTimeoutTime_HU_A" SG_ 643 BattPerSoC 0;
BA_ "GenSigTimeoutMsg_HU_Mid_X451" SG_ 643 BattPerSoC 0;
BA_ "GenSigTimeoutMsg_HU_High_X451" SG_ 643 BattPerSoC 0;
BA_ "GenSigTimeoutMsg_HU_B" SG_ 643 BattPerSoC 0;
BA_ "GenSigTimeoutMsg_HU_A" SG_ 643 BattPerSoC 0;
BA_ "GenSigSendType" SG_ 643 BattPerSoC 7;
BA_ "GenSigCycleTimeActive" SG_ 643 BattPerSoC 100;
BA_ "GenSigCycleTime" SG_ 643 BattPerSoC 100;
BA_ "GenSigTimeoutTime_HU_Mid_X451" SG_ 643 EnergyGain 0;
BA_ "GenSigTimeoutTime_HU_High_X451" SG_ 643 EnergyGain 0;
BA_ "GenSigTimeoutTime_HU_B" SG_ 643 EnergyGain 0;
BA_ "GenSigTimeoutTime_HU_A" SG_ 643 EnergyGain 0;
BA_ "GenSigTimeoutMsg_HU_Mid_X451" SG_ 643 EnergyGain 0;
BA_ "GenSigTimeoutMsg_HU_High_X451" SG_ 643 EnergyGain 0;
BA_ "GenSigTimeoutMsg_HU_B" SG_ 643 EnergyGain 0;
BA_ "GenSigTimeoutMsg_HU_A" SG_ 643 EnergyGain 0;
BA_ "GenSigStartValue" SG_ 643 EnergyGain 10000;
BA_ "GenSigSendType" SG_ 643 EnergyGain 7;
BA_ "GenSigCycleTimeActive" SG_ 643 EnergyGain 100;
BA_ "GenSigCycleTime" SG_ 643 EnergyGain 100;
BA_ "GenSigTimeoutTime_HU_Mid_X451" SG_ 643 BattSoCGain 0;
BA_ "GenSigTimeoutTime_HU_High_X451" SG_ 643 BattSoCGain 0;
BA_ "GenSigTimeoutTime_HU_B" SG_ 643 BattSoCGain 0;
BA_ "GenSigTimeoutTime_HU_A" SG_ 643 BattSoCGain 0;
BA_ "GenSigTimeoutMsg_HU_Mid_X451" SG_ 643 BattSoCGain 0;
BA_ "GenSigTimeoutMsg_HU_High_X451" SG_ 643 BattSoCGain 0;
BA_ "GenSigTimeoutMsg_HU_B" SG_ 643 BattSoCGain 0;
BA_ "GenSigTimeoutMsg_HU_A" SG_ 643 BattSoCGain 0;
BA_ "GenSigSendType" SG_ 643 BattSoCGain 7;
BA_ "GenSigCycleTimeActive" SG_ 643 BattSoCGain 100;
BA_ "GenSigCycleTime" SG_ 643 BattSoCGain 100;
BA_ "GenSigTimeoutTime_HU_Mid_X451" SG_ 643 BattChrgStatus 0;
BA_ "GenSigTimeoutTime_HU_High_X451" SG_ 643 BattChrgStatus 0;
BA_ "GenSigTimeoutTime_HU_B" SG_ 643 BattChrgStatus 0;
BA_ "GenSigTimeoutTime_HU_A" SG_ 643 BattChrgStatus 0;
BA_ "GenSigTimeoutMsg_HU_Mid_X451" SG_ 643 BattChrgStatus 0;
BA_ "GenSigTimeoutMsg_HU_High_X451" SG_ 643 BattChrgStatus 0;
BA_ "GenSigTimeoutMsg_HU_B" SG_ 643 BattChrgStatus 0;
BA_ "GenSigTimeoutMsg_HU_A" SG_ 643 BattChrgStatus 0;
BA_ "GenSigStartValue" SG_ 643 BattChrgStatus 1;
BA_ "GenSigSendType" SG_ 643 BattChrgStatus 7;
BA_ "GenSigCycleTimeActive" SG_ 643 BattChrgStatus 100;
BA_ "GenSigCycleTime" SG_ 643 BattChrgStatus 100;
BA_ "GenSigTimeoutTime_HU_Mid_X451" SG_ 643 BattWrkZone 0;
BA_ "GenSigTimeoutTime_HU_High_X451" SG_ 643 BattWrkZone 0;
BA_ "GenSigTimeoutTime_HU_B" SG_ 643 BattWrkZone 0;
BA_ "GenSigTimeoutTime_HU_A" SG_ 643 BattWrkZone 0;
BA_ "GenSigTimeoutMsg_HU_Mid_X451" SG_ 643 BattWrkZone 0;
BA_ "GenSigTimeoutMsg_HU_High_X451" SG_ 643 BattWrkZone 0;
BA_ "GenSigTimeoutMsg_HU_B" SG_ 643 BattWrkZone 0;
BA_ "GenSigTimeoutMsg_HU_A" SG_ 643 BattWrkZone 0;
BA_ "GenSigSendType" SG_ 643 BattWrkZone 7;
BA_ "GenSigCycleTimeActive" SG_ 643 BattWrkZone 100;
BA_ "GenSigCycleTime" SG_ 643 BattWrkZone 100;
BA_ "GenSigTimeoutTime_HU_Mid_X451" SG_ 643 BattAutoStopStatus 0;
BA_ "GenSigTimeoutTime_HU_High_X451" SG_ 643 BattAutoStopStatus 0;
BA_ "GenSigTimeoutTime_HU_B" SG_ 643 BattAutoStopStatus 0;
BA_ "GenSigTimeoutTime_HU_A" SG_ 643 BattAutoStopStatus 0;
BA_ "GenSigTimeoutMsg_HU_Mid_X451" SG_ 643 BattAutoStopStatus 0;
BA_ "GenSigTimeoutMsg_HU_High_X451" SG_ 643 BattAutoStopStatus 0;
BA_ "GenSigTimeoutMsg_HU_B" SG_ 643 BattAutoStopStatus 0;
BA_ "GenSigTimeoutMsg_HU_A" SG_ 643 BattAutoStopStatus 0;
BA_ "GenSigSendType" SG_ 643 BattAutoStopStatus 7;
BA_ "GenSigCycleTimeActive" SG_ 643 BattAutoStopStatus 100;
BA_ "GenSigCycleTime" SG_ 643 BattAutoStopStatus 100;
BA_ "GenSigTimeoutTime_HU_B" SG_ 644 AcCmprPr 0;
BA_ "GenSigTimeoutTime_HU_A" SG_ 644 AcCmprPr 0;
BA_ "GenSigTimeoutMsg_HU_B" SG_ 644 AcCmprPr 0;
BA_ "GenSigTimeoutMsg_HU_A" SG_ 644 AcCmprPr 0;
BA_ "GenSigSendType" SG_ 644 AcCmprPr 7;
BA_ "GenSigCycleTimeActive" SG_ 644 AcCmprPr 100;
BA_ "GenSigCycleTime" SG_ 644 AcCmprPr 100;
BA_ "GenSigSendType" SG_ 644 AcCmprOverPrStatus 7;
BA_ "GenSigCycleTimeActive" SG_ 644 AcCmprOverPrStatus 100;
BA_ "GenSigCycleTime" SG_ 644 AcCmprOverPrStatus 100;
BA_ "GenSigTimeoutTime_HU_B" SG_ 644 AcCmprPrStatus 0;
BA_ "GenSigTimeoutTime_HU_A" SG_ 644 AcCmprPrStatus 0;
BA_ "GenSigTimeoutMsg_HU_B" SG_ 644 AcCmprPrStatus 0;
BA_ "GenSigTimeoutMsg_HU_A" SG_ 644 AcCmprPrStatus 0;
BA_ "GenSigSendType" SG_ 644 AcCmprPrStatus 7;
BA_ "GenSigCycleTimeActive" SG_ 644 AcCmprPrStatus 100;
BA_ "GenSigCycleTime" SG_ 644 AcCmprPrStatus 100;
BA_ "GenSigStartValue" SG_ 644 EngEmission 2;
BA_ "GenSigSendType" SG_ 644 EngEmission 7;
BA_ "GenSigCycleTimeActive" SG_ 644 EngEmission 100;
BA_ "GenSigCycleTime" SG_ 644 EngEmission 100;
BA_ "GenSigSendType" SG_ 644 TxmnVariant 7;
BA_ "GenSigCycleTimeActive" SG_ 644 TxmnVariant 100;
BA_ "GenSigCycleTime" SG_ 644 TxmnVariant 100;
BA_ "GenSigTimeoutTime_HU_B" SG_ 644 AcCmprStatus 0;
BA_ "GenSigTimeoutTime_HU_A" SG_ 644 AcCmprStatus 0;
BA_ "GenSigTimeoutMsg_HU_B" SG_ 644 AcCmprStatus 0;
BA_ "GenSigTimeoutMsg_HU_A" SG_ 644 AcCmprStatus 0;
BA_ "GenSigSendType" SG_ 644 AcCmprStatus 7;
BA_ "GenSigCycleTimeActive" SG_ 644 AcCmprStatus 100;
BA_ "GenSigCycleTime" SG_ 644 AcCmprStatus 100;
BA_ "GenSigTimeoutTime_HU_B" SG_ 644 RadFanStatus 0;
BA_ "GenSigTimeoutTime_HU_A" SG_ 644 RadFanStatus 0;
BA_ "GenSigTimeoutMsg_HU_B" SG_ 644 RadFanStatus 0;
BA_ "GenSigTimeoutMsg_HU_A" SG_ 644 RadFanStatus 0;
BA_ "GenSigSendType" SG_ 644 RadFanStatus 7;
BA_ "GenSigCycleTimeActive" SG_ 644 RadFanStatus 100;
BA_ "GenSigCycleTime" SG_ 644 RadFanStatus 100;
BA_ "GenSigSendType" SG_ 644 AcCmprOverPrActive 7;
BA_ "GenSigCycleTimeActive" SG_ 644 AcCmprOverPrActive 100;
BA_ "GenSigCycleTime" SG_ 644 AcCmprOverPrActive 100;
BA_ "GenSigTimeoutTime_HU_B" SG_ 644 EMSInitDrvModeConfig 0;
BA_ "GenSigTimeoutTime_HU_A" SG_ 644 EMSInitDrvModeConfig 0;
BA_ "GenSigTimeoutMsg_HU_B" SG_ 644 EMSInitDrvModeConfig 0;
BA_ "GenSigTimeoutMsg_HU_A" SG_ 644 EMSInitDrvModeConfig 0;
BA_ "GenSigStartValue" SG_ 644 EMSInitDrvModeConfig 2;
BA_ "GenSigSendType" SG_ 644 EMSInitDrvModeConfig 7;
BA_ "GenSigCycleTimeActive" SG_ 644 EMSInitDrvModeConfig 100;
BA_ "GenSigCycleTime" SG_ 644 EMSInitDrvModeConfig 100;
BA_ "GenSigSendType" SG_ 644 BattVoltEMsStatus 7;
BA_ "GenSigCycleTimeActive" SG_ 644 BattVoltEMsStatus 100;
BA_ "GenSigCycleTime" SG_ 644 BattVoltEMsStatus 100;
BA_ "GenSigSendType" SG_ 644 EngLimpHomeMode 7;
BA_ "GenSigCycleTimeActive" SG_ 644 EngLimpHomeMode 100;
BA_ "GenSigCycleTime" SG_ 644 EngLimpHomeMode 100;
BA_ "GenSigStartValue" SG_ 644 BattVoltEMS 120;
BA_ "GenSigSendType" SG_ 644 BattVoltEMS 7;
BA_ "GenSigCycleTimeActive" SG_ 644 BattVoltEMS 100;
BA_ "GenSigCycleTime" SG_ 644 BattVoltEMS 100;
BA_ "GenSigTimeoutTime_HU_B" SG_ 644 AtmospPrStatus 0;
BA_ "GenSigTimeoutTime_HU_A" SG_ 644 AtmospPrStatus 0;
BA_ "GenSigTimeoutMsg_HU_B" SG_ 644 AtmospPrStatus 0;
BA_ "GenSigTimeoutMsg_HU_A" SG_ 644 AtmospPrStatus 0;
BA_ "GenSigSendType" SG_ 644 AtmospPrStatus 7;
BA_ "GenSigCycleTimeActive" SG_ 644 AtmospPrStatus 100;
BA_ "GenSigCycleTime" SG_ 644 AtmospPrStatus 100;
BA_ "GenSigSendType" SG_ 644 AcCmprUnderPrActive 7;
BA_ "GenSigCycleTimeActive" SG_ 644 AcCmprUnderPrActive 100;
BA_ "GenSigCycleTime" SG_ 644 AcCmprUnderPrActive 100;
BA_ "GenSigSendType" SG_ 644 AcCmprUnderPrStatus 7;
BA_ "GenSigCycleTimeActive" SG_ 644 AcCmprUnderPrStatus 100;
BA_ "GenSigCycleTime" SG_ 644 AcCmprUnderPrStatus 100;
BA_ "GenSigSendType" SG_ 644 EngVariant 7;
BA_ "GenSigCycleTimeActive" SG_ 644 EngVariant 100;
BA_ "GenSigCycleTime" SG_ 644 EngVariant 100;
BA_ "GenSigTimeoutTime_HU_B" SG_ 644 AtmospPr 0;
BA_ "GenSigTimeoutTime_HU_A" SG_ 644 AtmospPr 0;
BA_ "GenSigTimeoutMsg_HU_B" SG_ 644 AtmospPr 0;
BA_ "GenSigTimeoutMsg_HU_A" SG_ 644 AtmospPr 0;
BA_ "GenSigStartValue" SG_ 644 AtmospPr 50;
BA_ "GenSigSendType" SG_ 644 AtmospPr 7;
BA_ "GenSigCycleTimeActive" SG_ 644 AtmospPr 100;
BA_ "GenSigCycleTime" SG_ 644 AtmospPr 100;
BA_ "GenSigTimeoutTime_HU_B" SG_ 644 ModeChangeTxtEMS 0;
BA_ "GenSigTimeoutTime_HU_A" SG_ 644 ModeChangeTxtEMS 0;
BA_ "GenSigTimeoutMsg_HU_B" SG_ 644 ModeChangeTxtEMS 0;
BA_ "GenSigTimeoutMsg_HU_A" SG_ 644 ModeChangeTxtEMS 0;
BA_ "GenSigSendType" SG_ 644 ModeChangeTxtEMS 7;
BA_ "GenSigCycleTimeActive" SG_ 644 ModeChangeTxtEMS 100;
BA_ "GenSigCycleTime" SG_ 644 ModeChangeTxtEMS 100;
BA_ "GenSigSendType" SG_ 644 EngCrsCntrlMode 7;
BA_ "GenSigCycleTimeActive" SG_ 644 EngCrsCntrlMode 100;
BA_ "GenSigCycleTime" SG_ 644 EngCrsCntrlMode 100;
BA_ "GenSigSendType" SG_ 645 IACOpModes 7;
BA_ "GenSigCycleTimeActive" SG_ 645 IACOpModes 100;
BA_ "GenSigCycleTime" SG_ 645 IACOpModes 100;
BA_ "GenSigTimeoutTime_HU_Mid_X451" SG_ 645 IACMeExCurr 0;
BA_ "GenSigTimeoutTime_HU_High_X451" SG_ 645 IACMeExCurr 0;
BA_ "GenSigTimeoutTime_HU_B" SG_ 645 IACMeExCurr 0;
BA_ "GenSigTimeoutTime_HU_A" SG_ 645 IACMeExCurr 0;
BA_ "GenSigTimeoutMsg_HU_Mid_X451" SG_ 645 IACMeExCurr 0;
BA_ "GenSigTimeoutMsg_HU_High_X451" SG_ 645 IACMeExCurr 0;
BA_ "GenSigTimeoutMsg_HU_B" SG_ 645 IACMeExCurr 0;
BA_ "GenSigTimeoutMsg_HU_A" SG_ 645 IACMeExCurr 0;
BA_ "GenSigStartValue" SG_ 645 IACMeExCurr 100;
BA_ "GenSigSendType" SG_ 645 IACMeExCurr 7;
BA_ "GenSigCycleTimeActive" SG_ 645 IACMeExCurr 100;
BA_ "GenSigCycleTime" SG_ 645 IACMeExCurr 100;
BA_ "GenSigTimeoutTime_HU_Mid_X451" SG_ 645 IACMeVolt 0;
BA_ "GenSigTimeoutTime_HU_High_X451" SG_ 645 IACMeVolt 0;
BA_ "GenSigTimeoutTime_HU_B" SG_ 645 IACMeVolt 0;
BA_ "GenSigTimeoutTime_HU_A" SG_ 645 IACMeVolt 0;
BA_ "GenSigTimeoutMsg_HU_Mid_X451" SG_ 645 IACMeVolt 0;
BA_ "GenSigTimeoutMsg_HU_High_X451" SG_ 645 IACMeVolt 0;
BA_ "GenSigTimeoutMsg_HU_B" SG_ 645 IACMeVolt 0;
BA_ "GenSigTimeoutMsg_HU_A" SG_ 645 IACMeVolt 0;
BA_ "GenSigStartValue" SG_ 645 IACMeVolt 120;
BA_ "GenSigSendType" SG_ 645 IACMeVolt 7;
BA_ "GenSigCycleTimeActive" SG_ 645 IACMeVolt 100;
BA_ "GenSigCycleTime" SG_ 645 IACMeVolt 100;
BA_ "GenSigTimeoutTime_HU_Mid_X451" SG_ 645 IACMeSpd 0;
BA_ "GenSigTimeoutTime_HU_High_X451" SG_ 645 IACMeSpd 0;
BA_ "GenSigTimeoutTime_HU_B" SG_ 645 IACMeSpd 0;
BA_ "GenSigTimeoutTime_HU_A" SG_ 645 IACMeSpd 0;
BA_ "GenSigTimeoutMsg_HU_Mid_X451" SG_ 645 IACMeSpd 0;
BA_ "GenSigTimeoutMsg_HU_High_X451" SG_ 645 IACMeSpd 0;
BA_ "GenSigTimeoutMsg_HU_B" SG_ 645 IACMeSpd 0;
BA_ "GenSigTimeoutMsg_HU_A" SG_ 645 IACMeSpd 0;
BA_ "GenSigSendType" SG_ 645 IACMeSpd 7;
BA_ "GenSigCycleTimeActive" SG_ 645 IACMeSpd 100;
BA_ "GenSigCycleTime" SG_ 645 IACMeSpd 100;
BA_ "GenSigSendType" SG_ 646 UserSpdLim 7;
BA_ "GenSigCycleTimeActive" SG_ 646 UserSpdLim 100;
BA_ "GenSigCycleTime" SG_ 646 UserSpdLim 100;
BA_ "GenSigSendType" SG_ 646 UserSpdLimLamp 7;
BA_ "GenSigCycleTimeActive" SG_ 646 UserSpdLimLamp 100;
BA_ "GenSigCycleTime" SG_ 646 UserSpdLimLamp 100;
BA_ "GenSigSendType" SG_ 646 UserSpdLimFault 7;
BA_ "GenSigCycleTimeActive" SG_ 646 UserSpdLimFault 100;
BA_ "GenSigCycleTime" SG_ 646 UserSpdLimFault 100;
BA_ "GenSigSendType" SG_ 646 UserSpdLimStatus 7;
BA_ "GenSigCycleTimeActive" SG_ 646 UserSpdLimStatus 100;
BA_ "GenSigCycleTime" SG_ 646 UserSpdLimStatus 100;
BA_ "GenSigSendType" SG_ 646 EngStatus 7;
BA_ "GenSigCycleTimeActive" SG_ 646 EngStatus 100;
BA_ "GenSigCycleTime" SG_ 646 EngStatus 100;
BA_ "GenSigSendType" SG_ 646 CeLampState 7;
BA_ "GenSigCycleTimeActive" SG_ 646 CeLampState 100;
BA_ "GenSigCycleTime" SG_ 646 CeLampState 100;
BA_ "GenSigSendType" SG_ 646 StaterProhibitionDelay 7;
BA_ "GenSigCycleTimeActive" SG_ 646 StaterProhibitionDelay 100;
BA_ "GenSigCycleTime" SG_ 646 StaterProhibitionDelay 100;
BA_ "GenSigStartValue" SG_ 646 StarterControlState 1;
BA_ "GenSigSendType" SG_ 646 StarterControlState 7;
BA_ "GenSigCycleTimeActive" SG_ 646 StarterControlState 100;
BA_ "GenSigCycleTime" SG_ 646 StarterControlState 100;
BA_ "GenSigSendType" SG_ 646 UserSpdLimState 7;
BA_ "GenSigCycleTimeActive" SG_ 646 UserSpdLimState 100;
BA_ "GenSigCycleTime" SG_ 646 UserSpdLimState 100;
BA_ "GenSigTimeoutTime_HU_B" SG_ 646 SFCActiveEMS 0;
BA_ "GenSigTimeoutTime_HU_A" SG_ 646 SFCActiveEMS 0;
BA_ "GenSigTimeoutMsg_HU_B" SG_ 646 SFCActiveEMS 0;
BA_ "GenSigTimeoutMsg_HU_A" SG_ 646 SFCActiveEMS 0;
BA_ "GenSigSendType" SG_ 646 SFCActiveEMS 7;
BA_ "GenSigCycleTimeActive" SG_ 646 SFCActiveEMS 100;
BA_ "GenSigCycleTime" SG_ 646 SFCActiveEMS 100;
BA_ "GenSigSendType" SG_ 646 DrvModeIndctnEMSstatus 7;
BA_ "GenSigCycleTimeActive" SG_ 646 DrvModeIndctnEMSstatus 100;
BA_ "GenSigCycleTime" SG_ 646 DrvModeIndctnEMSstatus 100;
BA_ "GenSigSendType" SG_ 646 CruiseSpdLamp 7;
BA_ "GenSigCycleTimeActive" SG_ 646 CruiseSpdLamp 100;
BA_ "GenSigCycleTime" SG_ 646 CruiseSpdLamp 100;
BA_ "GenSigSendType" SG_ 646 StarterControlStatus 7;
BA_ "GenSigCycleTimeActive" SG_ 646 StarterControlStatus 100;
BA_ "GenSigCycleTime" SG_ 646 StarterControlStatus 100;
BA_ "GenSigSendType" SG_ 646 CurrGearEms 7;
BA_ "GenSigCycleTimeActive" SG_ 646 CurrGearEms 100;
BA_ "GenSigCycleTime" SG_ 646 CurrGearEms 100;
BA_ "GenSigSendType" SG_ 646 CruiseSpdFault 7;
BA_ "GenSigCycleTimeActive" SG_ 646 CruiseSpdFault 100;
BA_ "GenSigCycleTime" SG_ 646 CruiseSpdFault 100;
BA_ "GenSigSendType" SG_ 646 CruiseSpdStatus 7;
BA_ "GenSigCycleTimeActive" SG_ 646 CruiseSpdStatus 100;
BA_ "GenSigCycleTime" SG_ 646 CruiseSpdStatus 100;
BA_ "GenSigSendType" SG_ 646 CruiseSpd 7;
BA_ "GenSigCycleTimeActive" SG_ 646 CruiseSpd 100;
BA_ "GenSigCycleTime" SG_ 646 CruiseSpd 100;
BA_ "GenSigSendType" SG_ 646 CurrGearEmsStatus 7;
BA_ "GenSigCycleTimeActive" SG_ 646 CurrGearEmsStatus 100;
BA_ "GenSigCycleTime" SG_ 646 CurrGearEmsStatus 100;
BA_ "GenSigSendType" SG_ 646 GearShiftIndctnEmsStatus 7;
BA_ "GenSigCycleTimeActive" SG_ 646 GearShiftIndctnEmsStatus 100;
BA_ "GenSigCycleTime" SG_ 646 GearShiftIndctnEmsStatus 100;
BA_ "GenSigSendType" SG_ 646 GearShiftIndctnEms 7;
BA_ "GenSigCycleTimeActive" SG_ 646 GearShiftIndctnEms 100;
BA_ "GenSigCycleTime" SG_ 646 GearShiftIndctnEms 100;
BA_ "GenSigTimeoutTime_HU_B" SG_ 646 CruiseSwitchstate 0;
BA_ "GenSigTimeoutTime_HU_A" SG_ 646 CruiseSwitchstate 0;
BA_ "GenSigTimeoutMsg_HU_B" SG_ 646 CruiseSwitchstate 0;
BA_ "GenSigTimeoutMsg_HU_A" SG_ 646 CruiseSwitchstate 0;
BA_ "GenSigSendType" SG_ 646 CruiseSwitchstate 7;
BA_ "GenSigCycleTimeActive" SG_ 646 CruiseSwitchstate 100;
BA_ "GenSigCycleTime" SG_ 646 CruiseSwitchstate 100;
BA_ "GenSigTimeoutTime_HU_B" SG_ 646 CruiseSwitchstateStatus 0;
BA_ "GenSigTimeoutTime_HU_A" SG_ 646 CruiseSwitchstateStatus 0;
BA_ "GenSigTimeoutMsg_HU_B" SG_ 646 CruiseSwitchstateStatus 0;
BA_ "GenSigTimeoutMsg_HU_A" SG_ 646 CruiseSwitchstateStatus 0;
BA_ "GenSigSendType" SG_ 646 CruiseSwitchstateStatus 7;
BA_ "GenSigCycleTimeActive" SG_ 646 CruiseSwitchstateStatus 100;
BA_ "GenSigCycleTime" SG_ 646 CruiseSwitchstateStatus 100;
BA_ "GenSigSendType" SG_ 646 DrvModeIndctnEMS 7;
BA_ "GenSigCycleTimeActive" SG_ 646 DrvModeIndctnEMS 100;
BA_ "GenSigCycleTime" SG_ 646 DrvModeIndctnEMS 100;
BA_ "GenSigTimeoutTime_HU_Mid_X451" SG_ 647 EMSRemoteCheckStatus 0;
BA_ "GenSigTimeoutTime_HU_High_X451" SG_ 647 EMSRemoteCheckStatus 0;
BA_ "GenSigTimeoutTime_HU_B" SG_ 647 EMSRemoteCheckStatus 0;
BA_ "GenSigTimeoutTime_HU_A" SG_ 647 EMSRemoteCheckStatus 0;
BA_ "GenSigTimeoutMsg_HU_Mid_X451" SG_ 647 EMSRemoteCheckStatus 0;
BA_ "GenSigTimeoutMsg_HU_High_X451" SG_ 647 EMSRemoteCheckStatus 0;
BA_ "GenSigTimeoutMsg_HU_B" SG_ 647 EMSRemoteCheckStatus 0;
BA_ "GenSigTimeoutMsg_HU_A" SG_ 647 EMSRemoteCheckStatus 0;
BA_ "GenSigSendType" SG_ 647 EMSRemoteCheckStatus 7;
BA_ "GenSigCycleTimeActive" SG_ 647 EMSRemoteCheckStatus 100;
BA_ "GenSigCycleTime" SG_ 647 EMSRemoteCheckStatus 100;
BA_ "GenSigTimeoutTime_HU_Mid_X451" SG_ 647 EMSRemoteCheck 0;
BA_ "GenSigTimeoutTime_HU_High_X451" SG_ 647 EMSRemoteCheck 0;
BA_ "GenSigTimeoutTime_HU_B" SG_ 647 EMSRemoteCheck 0;
BA_ "GenSigTimeoutTime_HU_A" SG_ 647 EMSRemoteCheck 0;
BA_ "GenSigTimeoutMsg_HU_Mid_X451" SG_ 647 EMSRemoteCheck 0;
BA_ "GenSigTimeoutMsg_HU_High_X451" SG_ 647 EMSRemoteCheck 0;
BA_ "GenSigTimeoutMsg_HU_B" SG_ 647 EMSRemoteCheck 0;
BA_ "GenSigTimeoutMsg_HU_A" SG_ 647 EMSRemoteCheck 0;
BA_ "GenSigSendType" SG_ 647 EMSRemoteCheck 7;
BA_ "GenSigCycleTimeActive" SG_ 647 EMSRemoteCheck 100;
BA_ "GenSigCycleTime" SG_ 647 EMSRemoteCheck 100;
BA_ "GenSigTimeoutTime_HU_B" SG_ 647 DrvModeFailureState 0;
BA_ "GenSigTimeoutTime_HU_A" SG_ 647 DrvModeFailureState 0;
BA_ "GenSigTimeoutMsg_HU_B" SG_ 647 DrvModeFailureState 0;
BA_ "GenSigTimeoutMsg_HU_A" SG_ 647 DrvModeFailureState 0;
BA_ "GenSigSendType" SG_ 647 DrvModeFailureState 7;
BA_ "GenSigCycleTimeActive" SG_ 647 DrvModeFailureState 100;
BA_ "GenSigCycleTime" SG_ 647 DrvModeFailureState 100;
BA_ "GenSigSendType" SG_ 647 ModeChangeTxtEMSNew 7;
BA_ "GenSigCycleTimeActive" SG_ 647 ModeChangeTxtEMSNew 100;
BA_ "GenSigCycleTime" SG_ 647 ModeChangeTxtEMSNew 100;
BA_ "GenSigSendType" SG_ 647 DrvModeIndctnEMSNew 7;
BA_ "GenSigCycleTimeActive" SG_ 647 DrvModeIndctnEMSNew 100;
BA_ "GenSigCycleTime" SG_ 647 DrvModeIndctnEMSNew 100;
BA_ "GenSigSendType" SG_ 647 DrvModeIndctnEMSstatusNew 7;
BA_ "GenSigCycleTimeActive" SG_ 647 DrvModeIndctnEMSstatusNew 100;
BA_ "GenSigCycleTime" SG_ 647 DrvModeIndctnEMSstatusNew 100;
BA_ "GenSigSendType" SG_ 647 EngageParkOrNeutral 7;
BA_ "GenSigCycleTimeActive" SG_ 647 EngageParkOrNeutral 100;
BA_ "GenSigCycleTime" SG_ 647 EngageParkOrNeutral 100;
BA_ "GenSigSendType" SG_ 647 BrkPedalLamp 7;
BA_ "GenSigCycleTimeActive" SG_ 647 BrkPedalLamp 100;
BA_ "GenSigCycleTime" SG_ 647 BrkPedalLamp 100;
BA_ "GenSigTimeoutTime_HU_Mid_X451" SG_ 647 OBDWrmUpCycleStatus 0;
BA_ "GenSigTimeoutTime_HU_High_X451" SG_ 647 OBDWrmUpCycleStatus 0;
BA_ "GenSigTimeoutTime_HU_B" SG_ 647 OBDWrmUpCycleStatus 0;
BA_ "GenSigTimeoutTime_HU_A" SG_ 647 OBDWrmUpCycleStatus 0;
BA_ "GenSigTimeoutMsg_HU_Mid_X451" SG_ 647 OBDWrmUpCycleStatus 0;
BA_ "GenSigTimeoutMsg_HU_High_X451" SG_ 647 OBDWrmUpCycleStatus 0;
BA_ "GenSigTimeoutMsg_HU_B" SG_ 647 OBDWrmUpCycleStatus 0;
BA_ "GenSigTimeoutMsg_HU_A" SG_ 647 OBDWrmUpCycleStatus 0;
BA_ "GenSigSendType" SG_ 647 OBDWrmUpCycleStatus 7;
BA_ "GenSigCycleTimeActive" SG_ 647 OBDWrmUpCycleStatus 100;
BA_ "GenSigCycleTime" SG_ 647 OBDWrmUpCycleStatus 100;
BA_ "GenSigTimeoutTime_HU_Mid_X451" SG_ 647 OBDDrvCycleStatus 0;
BA_ "GenSigTimeoutTime_HU_High_X451" SG_ 647 OBDDrvCycleStatus 0;
BA_ "GenSigTimeoutTime_HU_B" SG_ 647 OBDDrvCycleStatus 0;
BA_ "GenSigTimeoutTime_HU_A" SG_ 647 OBDDrvCycleStatus 0;
BA_ "GenSigTimeoutMsg_HU_Mid_X451" SG_ 647 OBDDrvCycleStatus 0;
BA_ "GenSigTimeoutMsg_HU_High_X451" SG_ 647 OBDDrvCycleStatus 0;
BA_ "GenSigTimeoutMsg_HU_B" SG_ 647 OBDDrvCycleStatus 0;
BA_ "GenSigTimeoutMsg_HU_A" SG_ 647 OBDDrvCycleStatus 0;
BA_ "GenSigSendType" SG_ 647 OBDDrvCycleStatus 7;
BA_ "GenSigCycleTimeActive" SG_ 647 OBDDrvCycleStatus 100;
BA_ "GenSigCycleTime" SG_ 647 OBDDrvCycleStatus 100;
BA_ "GenSigSendType" SG_ 647 PressClutToStart 7;
BA_ "GenSigCycleTimeActive" SG_ 647 PressClutToStart 100;
BA_ "GenSigCycleTime" SG_ 647 PressClutToStart 100;
BA_ "GenSigSendType" SG_ 647 CrsResumeInh 7;
BA_ "GenSigCycleTimeActive" SG_ 647 CrsResumeInh 100;
BA_ "GenSigCycleTime" SG_ 647 CrsResumeInh 100;
BA_ "GenSigStartValue" SG_ 647 RegntRemainDist 4094;
BA_ "GenSigSendType" SG_ 647 RegntRemainDist 7;
BA_ "GenSigCycleTimeActive" SG_ 647 RegntRemainDist 100;
BA_ "GenSigCycleTime" SG_ 647 RegntRemainDist 100;
BA_ "GenSigTimeoutTime_HU_Mid_X451" SG_ 647 SmartAltState 0;
BA_ "GenSigTimeoutTime_HU_High_X451" SG_ 647 SmartAltState 0;
BA_ "GenSigTimeoutTime_HU_B" SG_ 647 SmartAltState 0;
BA_ "GenSigTimeoutTime_HU_A" SG_ 647 SmartAltState 0;
BA_ "GenSigTimeoutMsg_HU_Mid_X451" SG_ 647 SmartAltState 0;
BA_ "GenSigTimeoutMsg_HU_High_X451" SG_ 647 SmartAltState 0;
BA_ "GenSigTimeoutMsg_HU_B" SG_ 647 SmartAltState 0;
BA_ "GenSigTimeoutMsg_HU_A" SG_ 647 SmartAltState 0;
BA_ "GenSigSendType" SG_ 647 SmartAltState 7;
BA_ "GenSigCycleTimeActive" SG_ 647 SmartAltState 100;
BA_ "GenSigCycleTime" SG_ 647 SmartAltState 100;
BA_ "GenSigSendType" SG_ 647 RegntLevel 7;
BA_ "GenSigCycleTimeActive" SG_ 647 RegntLevel 100;
BA_ "GenSigCycleTime" SG_ 647 RegntLevel 100;
BA_ "GenSigSendType" SG_ 648 ESSAutonomousStart 7;
BA_ "GenSigCycleTimeActive" SG_ 648 ESSAutonomousStart 100;
BA_ "GenSigCycleTime" SG_ 648 ESSAutonomousStart 100;
BA_ "GenSigSendType" SG_ 648 ESSAutoStopActCon 7;
BA_ "GenSigCycleTimeActive" SG_ 648 ESSAutoStopActCon 100;
BA_ "GenSigCycleTime" SG_ 648 ESSAutoStopActCon 100;
BA_ "GenSigSendType" SG_ 648 ESSAutoStopInhibited 7;
BA_ "GenSigCycleTimeActive" SG_ 648 ESSAutoStopInhibited 100;
BA_ "GenSigCycleTime" SG_ 648 ESSAutoStopInhibited 100;
BA_ "GenSigStartValue" SG_ 648 ESSIACSystemAvailable 2;
BA_ "GenSigSendType" SG_ 648 ESSIACSystemAvailable 7;
BA_ "GenSigCycleTimeActive" SG_ 648 ESSIACSystemAvailable 100;
BA_ "GenSigCycleTime" SG_ 648 ESSIACSystemAvailable 100;
BA_ "GenSigSendType" SG_ 648 ESSAutoStartStopActSt 7;
BA_ "GenSigCycleTimeActive" SG_ 648 ESSAutoStartStopActSt 100;
BA_ "GenSigCycleTime" SG_ 648 ESSAutoStartStopActSt 100;
BA_ "GenSigSendType" SG_ 648 ESSDisableSwitchStatus 7;
BA_ "GenSigCycleTimeActive" SG_ 648 ESSDisableSwitchStatus 100;
BA_ "GenSigCycleTime" SG_ 648 ESSDisableSwitchStatus 100;
BA_ "GenSigSendType" SG_ 648 ESSDisableSwitchState 7;
BA_ "GenSigCycleTimeActive" SG_ 648 ESSDisableSwitchState 100;
BA_ "GenSigCycleTime" SG_ 648 ESSDisableSwitchState 100;
BA_ "GenSigSendType" SG_ 648 ESSAutoStartLamp 7;
BA_ "GenSigCycleTimeActive" SG_ 648 ESSAutoStartLamp 100;
BA_ "GenSigCycleTime" SG_ 648 ESSAutoStartLamp 100;
BA_ "GenSigSendType" SG_ 648 ESSAutoStopLamp 7;
BA_ "GenSigCycleTimeActive" SG_ 648 ESSAutoStopLamp 100;
BA_ "GenSigCycleTime" SG_ 648 ESSAutoStopLamp 100;
BA_ "GenSigSendType" SG_ 648 ESSTextMsg 7;
BA_ "GenSigCycleTimeActive" SG_ 648 ESSTextMsg 100;
BA_ "GenSigCycleTime" SG_ 648 ESSTextMsg 100;
BA_ "GenSigSendType" SG_ 648 ESSLamp 7;
BA_ "GenSigCycleTimeActive" SG_ 648 ESSLamp 100;
BA_ "GenSigCycleTime" SG_ 648 ESSLamp 100;
BA_ "GenSigSendType" SG_ 648 ESSAutoStartForbidden 7;
BA_ "GenSigCycleTimeActive" SG_ 648 ESSAutoStartForbidden 100;
BA_ "GenSigCycleTime" SG_ 648 ESSAutoStartForbidden 100;
BA_ "GenSigSendType" SG_ 649 EMsSOhIndex 7;
BA_ "GenSigCycleTimeActive" SG_ 649 EMsSOhIndex 100;
BA_ "GenSigCycleTime" SG_ 649 EMsSOhIndex 100;
BA_ "GenSigSendType" SG_ 649 EMsSOcIndex 7;
BA_ "GenSigCycleTimeActive" SG_ 649 EMsSOcIndex 100;
BA_ "GenSigCycleTime" SG_ 649 EMsSOcIndex 100;
BA_ "GenSigSendType" SG_ 649 IBsSOhSts 7;
BA_ "GenSigCycleTimeActive" SG_ 649 IBsSOhSts 100;
BA_ "GenSigCycleTime" SG_ 649 IBsSOhSts 100;
BA_ "GenSigSendType" SG_ 649 IBsSOH 7;
BA_ "GenSigCycleTimeActive" SG_ 649 IBsSOH 100;
BA_ "GenSigCycleTime" SG_ 649 IBsSOH 100;
BA_ "GenSigStartValue" SG_ 649 IbsCurr 32928;
BA_ "GenSigSendType" SG_ 649 IbsCurr 7;
BA_ "GenSigCycleTimeActive" SG_ 649 IbsCurr 100;
BA_ "GenSigCycleTime" SG_ 649 IbsCurr 100;
BA_ "GenSigStartValue" SG_ 649 IbsVtgSt 144;
BA_ "GenSigSendType" SG_ 649 IbsVtgSt 7;
BA_ "GenSigCycleTimeActive" SG_ 649 IbsVtgSt 100;
BA_ "GenSigCycleTime" SG_ 649 IbsVtgSt 100;
BA_ "GenSigStartValue" SG_ 649 IBsSOC 75;
BA_ "GenSigSendType" SG_ 649 IBsSOC 7;
BA_ "GenSigCycleTimeActive" SG_ 649 IBsSOC 100;
BA_ "GenSigCycleTime" SG_ 649 IBsSOC 100;
BA_ "GenSigStartValue" SG_ 649 IbsTempSt 80;
BA_ "GenSigSendType" SG_ 649 IbsTempSt 7;
BA_ "GenSigCycleTimeActive" SG_ 649 IbsTempSt 100;
BA_ "GenSigCycleTime" SG_ 649 IbsTempSt 100;
BA_ "GenSigSendType" SG_ 649 IBsSOcSts 7;
BA_ "GenSigCycleTimeActive" SG_ 649 IBsSOcSts 100;
BA_ "GenSigCycleTime" SG_ 649 IBsSOcSts 100;
BA_ "GenSigSendType" SG_ 649 IbsTempSts 7;
BA_ "GenSigCycleTimeActive" SG_ 649 IbsTempSts 100;
BA_ "GenSigCycleTime" SG_ 649 IbsTempSts 100;
BA_ "GenSigSendType" SG_ 649 IbsVtgSts 7;
BA_ "GenSigCycleTimeActive" SG_ 649 IbsVtgSts 100;
BA_ "GenSigCycleTime" SG_ 649 IbsVtgSts 100;
BA_ "GenSigSendType" SG_ 649 IbsCurrSts 7;
BA_ "GenSigCycleTimeActive" SG_ 649 IbsCurrSts 100;
BA_ "GenSigCycleTime" SG_ 649 IbsCurrSts 100;
BA_ "GenSigSendType" SG_ 650 EPAsStatus 7;
BA_ "GenSigCycleTimeActive" SG_ 650 EPAsStatus 100;
BA_ "GenSigCycleTime" SG_ 650 EPAsStatus 100;
BA_ "GenSigTimeoutTime_HU_B" SG_ 651 SteerWhlTrqStatus 0;
BA_ "GenSigTimeoutTime_HU_A" SG_ 651 SteerWhlTrqStatus 0;
BA_ "GenSigTimeoutMsg_HU_B" SG_ 651 SteerWhlTrqStatus 0;
BA_ "GenSigTimeoutMsg_HU_A" SG_ 651 SteerWhlTrqStatus 0;
BA_ "GenSigSendType" SG_ 651 SteerWhlTrqStatus 7;
BA_ "GenSigCycleTimeActive" SG_ 651 SteerWhlTrqStatus 100;
BA_ "GenSigCycleTime" SG_ 651 SteerWhlTrqStatus 100;
BA_ "GenSigTimeoutTime_HU_B" SG_ 651 SteerWhlTrq 0;
BA_ "GenSigTimeoutTime_HU_A" SG_ 651 SteerWhlTrq 0;
BA_ "GenSigTimeoutMsg_HU_B" SG_ 651 SteerWhlTrq 0;
BA_ "GenSigTimeoutMsg_HU_A" SG_ 651 SteerWhlTrq 0;
BA_ "GenSigStartValue" SG_ 651 SteerWhlTrq 2050;
BA_ "GenSigSendType" SG_ 651 SteerWhlTrq 7;
BA_ "GenSigCycleTimeActive" SG_ 651 SteerWhlTrq 100;
BA_ "GenSigCycleTime" SG_ 651 SteerWhlTrq 100;
BA_ "GenSigSendType" SG_ 651 SAsAngEPAS 7;
BA_ "GenSigCycleTimeActive" SG_ 651 SAsAngEPAS 100;
BA_ "GenSigCycleTime" SG_ 651 SAsAngEPAS 100;
BA_ "GenSigSendType" SG_ 651 SAsAngEPAsDir 7;
BA_ "GenSigCycleTimeActive" SG_ 651 SAsAngEPAsDir 100;
BA_ "GenSigCycleTime" SG_ 651 SAsAngEPAsDir 100;
BA_ "GenSigStartValue" SG_ 651 SAsAngEPASStatus 2;
BA_ "GenSigSendType" SG_ 651 SAsAngEPASStatus 7;
BA_ "GenSigCycleTimeActive" SG_ 651 SAsAngEPASStatus 100;
BA_ "GenSigCycleTime" SG_ 651 SAsAngEPASStatus 100;
BA_ "GenSigSendType" SG_ 651 EPASDriverInformation 7;
BA_ "GenSigCycleTimeActive" SG_ 651 EPASDriverInformation 100;
BA_ "GenSigCycleTime" SG_ 651 EPASDriverInformation 100;
BA_ "GenSigSendType" SG_ 651 EPASDriverWarning 7;
BA_ "GenSigCycleTimeActive" SG_ 651 EPASDriverWarning 100;
BA_ "GenSigCycleTime" SG_ 651 EPASDriverWarning 100;
BA_ "GenSigTimeoutTime_HU_B" SG_ 651 DrvModeIndctnEPAS 0;
BA_ "GenSigTimeoutTime_HU_A" SG_ 651 DrvModeIndctnEPAS 0;
BA_ "GenSigTimeoutMsg_HU_B" SG_ 651 DrvModeIndctnEPAS 0;
BA_ "GenSigTimeoutMsg_HU_A" SG_ 651 DrvModeIndctnEPAS 0;
BA_ "GenSigSendType" SG_ 651 DrvModeIndctnEPAS 7;
BA_ "GenSigCycleTimeActive" SG_ 651 DrvModeIndctnEPAS 100;
BA_ "GenSigCycleTime" SG_ 651 DrvModeIndctnEPAS 100;
BA_ "GenSigTimeoutTime_HU_B" SG_ 651 DrvModeIndctnEPASstatus 0;
BA_ "GenSigTimeoutTime_HU_A" SG_ 651 DrvModeIndctnEPASstatus 0;
BA_ "GenSigTimeoutMsg_HU_B" SG_ 651 DrvModeIndctnEPASstatus 0;
BA_ "GenSigTimeoutMsg_HU_A" SG_ 651 DrvModeIndctnEPASstatus 0;
BA_ "GenSigSendType" SG_ 651 DrvModeIndctnEPASstatus 7;
BA_ "GenSigCycleTimeActive" SG_ 651 DrvModeIndctnEPASstatus 100;
BA_ "GenSigCycleTime" SG_ 651 DrvModeIndctnEPASstatus 100;
BA_ "GenSigSendType" SG_ 651 EPAsStatusGen2 7;
BA_ "GenSigCycleTimeActive" SG_ 651 EPAsStatusGen2 100;
BA_ "GenSigCycleTime" SG_ 651 EPAsStatusGen2 100;
BA_ "GenSigSendType" SG_ 651 EPAsAssistStatus 7;
BA_ "GenSigCycleTimeActive" SG_ 651 EPAsAssistStatus 100;
BA_ "GenSigCycleTime" SG_ 651 EPAsAssistStatus 100;
BA_ "GenSigStartValue" SG_ 652 SteerAngEPAsCalibration 1;
BA_ "GenSigSendType" SG_ 652 SteerAngEPAsCalibration 7;
BA_ "GenSigCycleTimeActive" SG_ 652 SteerAngEPAsCalibration 100;
BA_ "GenSigCycleTime" SG_ 652 SteerAngEPAsCalibration 100;
BA_ "GenSigSendType" SG_ 656 StuckModeAvailability 7;
BA_ "GenSigCycleTimeActive" SG_ 656 StuckModeAvailability 100;
BA_ "GenSigCycleTime" SG_ 656 StuckModeAvailability 100;
BA_ "GenSigSendType" SG_ 656 StuckModeStateStatus 7;
BA_ "GenSigCycleTimeActive" SG_ 656 StuckModeStateStatus 100;
BA_ "GenSigCycleTime" SG_ 656 StuckModeStateStatus 100;
BA_ "GenSigSendType" SG_ 656 StuckModeState 7;
BA_ "GenSigCycleTimeActive" SG_ 656 StuckModeState 100;
BA_ "GenSigCycleTime" SG_ 656 StuckModeState 100;
BA_ "GenSigSendType" SG_ 656 ModeDetectESPStatus 7;
BA_ "GenSigCycleTimeActive" SG_ 656 ModeDetectESPStatus 100;
BA_ "GenSigCycleTime" SG_ 656 ModeDetectESPStatus 100;
BA_ "GenSigSendType" SG_ 656 ModeDetectESP 7;
BA_ "GenSigCycleTimeActive" SG_ 656 ModeDetectESP 100;
BA_ "GenSigCycleTime" SG_ 656 ModeDetectESP 100;
BA_ "GenSigSendType" SG_ 656 WSsPulseCountRearRH 7;
BA_ "GenSigCycleTimeActive" SG_ 656 WSsPulseCountRearRH 100;
BA_ "GenSigCycleTime" SG_ 656 WSsPulseCountRearRH 100;
BA_ "GenSigSendType" SG_ 656 WSsPulseCountRearLH 7;
BA_ "GenSigCycleTimeActive" SG_ 656 WSsPulseCountRearLH 100;
BA_ "GenSigCycleTime" SG_ 656 WSsPulseCountRearLH 100;
BA_ "GenSigSendType" SG_ 656 WSsPulseCountFrontRH 7;
BA_ "GenSigCycleTimeActive" SG_ 656 WSsPulseCountFrontRH 100;
BA_ "GenSigCycleTime" SG_ 656 WSsPulseCountFrontRH 100;
BA_ "GenSigSendType" SG_ 656 WSsPulseCountFrontLH 7;
BA_ "GenSigCycleTimeActive" SG_ 656 WSsPulseCountFrontLH 100;
BA_ "GenSigCycleTime" SG_ 656 WSsPulseCountFrontLH 100;
BA_ "GenSigSendType" SG_ 656 WSsPulseCountFrontRHStatus 7;
BA_ "GenSigCycleTimeActive" SG_ 656 WSsPulseCountFrontRHStatus 100;
BA_ "GenSigCycleTime" SG_ 656 WSsPulseCountFrontRHStatus 100;
BA_ "GenSigSendType" SG_ 656 WSsPulseCountRearLHStatus 7;
BA_ "GenSigCycleTimeActive" SG_ 656 WSsPulseCountRearLHStatus 100;
BA_ "GenSigCycleTime" SG_ 656 WSsPulseCountRearLHStatus 100;
BA_ "GenSigSendType" SG_ 656 WSsPulseCountRearRHStatus 7;
BA_ "GenSigCycleTimeActive" SG_ 656 WSsPulseCountRearRHStatus 100;
BA_ "GenSigCycleTime" SG_ 656 WSsPulseCountRearRHStatus 100;
BA_ "GenSigSendType" SG_ 656 WSsPulseCountFrontLHStatus 7;
BA_ "GenSigCycleTimeActive" SG_ 656 WSsPulseCountFrontLHStatus 100;
BA_ "GenSigCycleTime" SG_ 656 WSsPulseCountFrontLHStatus 100;
BA_ "GenSigSendType" SG_ 656 DrvModeIndctnESPStatusNew 7;
BA_ "GenSigCycleTimeActive" SG_ 656 DrvModeIndctnESPStatusNew 100;
BA_ "GenSigCycleTime" SG_ 656 DrvModeIndctnESPStatusNew 100;
BA_ "GenSigSendType" SG_ 656 DrvModeIndctnESPNew 7;
BA_ "GenSigCycleTimeActive" SG_ 656 DrvModeIndctnESPNew 100;
BA_ "GenSigCycleTime" SG_ 656 DrvModeIndctnESPNew 100;
BA_ "GenSigTimeoutTime_HU_B" SG_ 660 WhlSpdFrLeft 0;
BA_ "GenSigTimeoutTime_HU_A" SG_ 660 WhlSpdFrLeft 0;
BA_ "GenSigTimeoutMsg_HU_B" SG_ 660 WhlSpdFrLeft 0;
BA_ "GenSigTimeoutMsg_HU_A" SG_ 660 WhlSpdFrLeft 0;
BA_ "GenSigSendType" SG_ 660 WhlSpdFrLeft 7;
BA_ "GenSigCycleTimeActive" SG_ 660 WhlSpdFrLeft 100;
BA_ "GenSigCycleTime" SG_ 660 WhlSpdFrLeft 100;
BA_ "GenSigTimeoutTime_HU_B" SG_ 660 WhlSpdFrRight 0;
BA_ "GenSigTimeoutTime_HU_A" SG_ 660 WhlSpdFrRight 0;
BA_ "GenSigTimeoutMsg_HU_B" SG_ 660 WhlSpdFrRight 0;
BA_ "GenSigTimeoutMsg_HU_A" SG_ 660 WhlSpdFrRight 0;
BA_ "GenSigSendType" SG_ 660 WhlSpdFrRight 7;
BA_ "GenSigCycleTimeActive" SG_ 660 WhlSpdFrRight 100;
BA_ "GenSigCycleTime" SG_ 660 WhlSpdFrRight 100;
BA_ "GenSigTimeoutTime_HU_B" SG_ 660 WhlSpdFrLeftStatus 0;
BA_ "GenSigTimeoutTime_HU_A" SG_ 660 WhlSpdFrLeftStatus 0;
BA_ "GenSigTimeoutMsg_HU_B" SG_ 660 WhlSpdFrLeftStatus 0;
BA_ "GenSigTimeoutMsg_HU_A" SG_ 660 WhlSpdFrLeftStatus 0;
BA_ "GenSigSendType" SG_ 660 WhlSpdFrLeftStatus 7;
BA_ "GenSigCycleTimeActive" SG_ 660 WhlSpdFrLeftStatus 100;
BA_ "GenSigCycleTime" SG_ 660 WhlSpdFrLeftStatus 100;
BA_ "GenSigTimeoutTime_HU_B" SG_ 660 WhlSpdRrLeft 0;
BA_ "GenSigTimeoutTime_HU_A" SG_ 660 WhlSpdRrLeft 0;
BA_ "GenSigTimeoutMsg_HU_B" SG_ 660 WhlSpdRrLeft 0;
BA_ "GenSigTimeoutMsg_HU_A" SG_ 660 WhlSpdRrLeft 0;
BA_ "GenSigSendType" SG_ 660 WhlSpdRrLeft 7;
BA_ "GenSigCycleTimeActive" SG_ 660 WhlSpdRrLeft 100;
BA_ "GenSigCycleTime" SG_ 660 WhlSpdRrLeft 100;
BA_ "GenSigTimeoutTime_HU_B" SG_ 660 WhlSpdFrRightStatus 0;
BA_ "GenSigTimeoutTime_HU_A" SG_ 660 WhlSpdFrRightStatus 0;
BA_ "GenSigTimeoutMsg_HU_B" SG_ 660 WhlSpdFrRightStatus 0;
BA_ "GenSigTimeoutMsg_HU_A" SG_ 660 WhlSpdFrRightStatus 0;
BA_ "GenSigSendType" SG_ 660 WhlSpdFrRightStatus 7;
BA_ "GenSigCycleTimeActive" SG_ 660 WhlSpdFrRightStatus 100;
BA_ "GenSigCycleTime" SG_ 660 WhlSpdFrRightStatus 100;
BA_ "GenSigTimeoutTime_HU_B" SG_ 660 WhlSpdRrRight 0;
BA_ "GenSigTimeoutTime_HU_A" SG_ 660 WhlSpdRrRight 0;
BA_ "GenSigTimeoutMsg_HU_B" SG_ 660 WhlSpdRrRight 0;
BA_ "GenSigTimeoutMsg_HU_A" SG_ 660 WhlSpdRrRight 0;
BA_ "GenSigSendType" SG_ 660 WhlSpdRrRight 7;
BA_ "GenSigCycleTimeActive" SG_ 660 WhlSpdRrRight 100;
BA_ "GenSigCycleTime" SG_ 660 WhlSpdRrRight 100;
BA_ "GenSigTimeoutTime_HU_B" SG_ 660 WhlSpdRrLeftStatus 0;
BA_ "GenSigTimeoutTime_HU_A" SG_ 660 WhlSpdRrLeftStatus 0;
BA_ "GenSigTimeoutMsg_HU_B" SG_ 660 WhlSpdRrLeftStatus 0;
BA_ "GenSigTimeoutMsg_HU_A" SG_ 660 WhlSpdRrLeftStatus 0;
BA_ "GenSigSendType" SG_ 660 WhlSpdRrLeftStatus 7;
BA_ "GenSigCycleTimeActive" SG_ 660 WhlSpdRrLeftStatus 100;
BA_ "GenSigCycleTime" SG_ 660 WhlSpdRrLeftStatus 100;
BA_ "GenSigTimeoutTime_HU_B" SG_ 660 WhlSpdAliveCounter 0;
BA_ "GenSigTimeoutTime_HU_A" SG_ 660 WhlSpdAliveCounter 0;
BA_ "GenSigTimeoutMsg_HU_B" SG_ 660 WhlSpdAliveCounter 0;
BA_ "GenSigTimeoutMsg_HU_A" SG_ 660 WhlSpdAliveCounter 0;
BA_ "GenSigSendType" SG_ 660 WhlSpdAliveCounter 7;
BA_ "GenSigCycleTimeActive" SG_ 660 WhlSpdAliveCounter 100;
BA_ "GenSigCycleTime" SG_ 660 WhlSpdAliveCounter 100;
BA_ "GenSigTimeoutTime_HU_B" SG_ 660 WhlSpdRrRightStatus 0;
BA_ "GenSigTimeoutTime_HU_A" SG_ 660 WhlSpdRrRightStatus 0;
BA_ "GenSigTimeoutMsg_HU_B" SG_ 660 WhlSpdRrRightStatus 0;
BA_ "GenSigTimeoutMsg_HU_A" SG_ 660 WhlSpdRrRightStatus 0;
BA_ "GenSigSendType" SG_ 660 WhlSpdRrRightStatus 7;
BA_ "GenSigCycleTimeActive" SG_ 660 WhlSpdRrRightStatus 100;
BA_ "GenSigCycleTime" SG_ 660 WhlSpdRrRightStatus 100;
BA_ "GenSigTimeoutTime_HU_B" SG_ 660 WhlSpdCRC 0;
BA_ "GenSigTimeoutTime_HU_A" SG_ 660 WhlSpdCRC 0;
BA_ "GenSigTimeoutMsg_HU_B" SG_ 660 WhlSpdCRC 0;
BA_ "GenSigTimeoutMsg_HU_A" SG_ 660 WhlSpdCRC 0;
BA_ "GenSigSendType" SG_ 660 WhlSpdCRC 7;
BA_ "GenSigCycleTimeActive" SG_ 660 WhlSpdCRC 100;
BA_ "GenSigCycleTime" SG_ 660 WhlSpdCRC 100;
VAL_ 506 HuAutoRelockActiveSignalVal 1 "Active value for Auto Relock feature is Enabled" 0 "Active value for Auto Relock feature is Disabled" ;
VAL_ 506 HuFMhActiveSignalVal 3 "Reserved" 2 "Active value is HuFMhPossibleVal3" 1 "Active value is HuFMhPossibleVal2" 0 "Active value is HuFMhPossibleVal1" ;
VAL_ 506 HuFMhSignalVal1 31 "Reserved" 30 "Reserved" 29 "Reserved" 28 "Reserved" 27 "Reserved" 26 "Reserved" 25 "Reserved" 24 "Possible value selected is 240" 23 "Possible value selected is 230" 22 "Possible value selected is 220" 21 "Possible value selected is 210" 20 "Possible value selected is 200" 19 "Possible value selected is 190" 18 "Possible value selected is 180" 17 "Possible value selected is 170" 16 "Possible value selected is 160" 15 "Possible value selected is 150" 14 "Possible value selected is 140" 13 "Possible value selected is 130" 12 "Possible value selected is 120" 11 "Possible value selected is 110" 10 "Possible value selected is 100" 9 "Possible value selected is 90" 8 "Possible value selected is 80" 7 "Possible value selected is 70" 6 "Possible value selected is 60" 5 "Possible value selected is 50" 4 "Possible value selected is 40" 3 "Possible value selected is 30" 2 "Possible value selected is 20" 1 "Possible value selected is 10" 0 "Possible value selected is 0" ;
VAL_ 506 HuVehLockHornReqActiveSignalVal 1 "Active value for vehicle Lock Horn Request feature is ON" 0 "Active value for Vehicle Lock Horn Request feature is OFF
" ;
VAL_ 506 HuApproachLampActiveSignalVal 3 "Reserved" 2 "Active value is HuApproachLampSignalVal3" 1 "Active value is HuApproachLampSignalVal2" 0 "Active value is HuApproachLampSignalVal1" ;
VAL_ 506 HuFMhSignalVal2 31 "Reserved" 30 "Reserved" 29 "Reserved" 28 "Reserved" 27 "Reserved" 26 "Reserved" 25 "Reserved" 24 "Possible value selected is 240" 23 "Possible value selected is 230" 22 "Possible value selected is 220" 21 "Possible value selected is 210" 20 "Possible value selected is 200" 19 "Possible value selected is 190" 18 "Possible value selected is 180" 17 "Possible value selected is 170" 16 "Possible value selected is 160" 15 "Possible value selected is 150" 14 "Possible value selected is 140" 13 "Possible value selected is 130" 12 "Possible value selected is 120" 11 "Possible value selected is 110" 10 "Possible value selected is 100" 9 "Possible value selected is 90" 8 "Possible value selected is 80" 7 "Possible value selected is 70" 6 "Possible value selected is 60" 5 "Possible value selected is 50" 4 "Possible value selected is 40" 3 "Possible value selected is 30" 2 "Possible value selected is 20" 1 "Possible value selected is 10" 0 "Possible value selected is 0" ;
VAL_ 506 HuDriveAwayLockingActiveSignalVa 1 "Active value for Drive Away Locking feature is Enabled" 0 "Active value for Drive Away Locking feature is Disabled
" ;
VAL_ 506 HuRKeUnlockActiveSignalVal 1 "Active value for vehicle Unlock with RKE feature is Double Stage Unlock" 0 "Active value for vehicle Unlock with RKE feature is Single Stage Unlock
" ;
VAL_ 506 HuPKeUnlockActiveSignalVal 1 "Active value for vehicle Unlock with PKE feature is Double Stage Unlock" 0 "Active value for vehicle Unlock with PKE feature is Single Stage Unlock
" ;
VAL_ 506 HuFMhSignalVal3 31 "Reserved" 30 "Reserved" 29 "Reserved" 28 "Reserved" 27 "Reserved" 26 "Reserved" 25 "Reserved" 24 "Possible value selected is 240" 23 "Possible value selected is 230" 22 "Possible value selected is 220" 21 "Possible value selected is 210" 20 "Possible value selected is 200" 19 "Possible value selected is 190" 18 "Possible value selected is 180" 17 "Possible value selected is 170" 16 "Possible value selected is 160" 15 "Possible value selected is 150" 14 "Possible value selected is 140" 13 "Possible value selected is 130" 12 "Possible value selected is 120" 11 "Possible value selected is 110" 10 "Possible value selected is 100" 9 "Possible value selected is 90" 8 "Possible value selected is 80" 7 "Possible value selected is 70" 6 "Possible value selected is 60" 5 "Possible value selected is 50" 4 "Possible value selected is 40" 3 "Possible value selected is 30" 2 "Possible value selected is 20" 1 "Possible value selected is 10" 0 "Possible value selected is 0" ;
VAL_ 506 BCmFactorySettingReq 1 "Restored Factory Settings" 0 "Current Settings" ;
VAL_ 506 HuApproachLampSignalVal1 31 "Reserved" 30 "Reserved" 29 "Reserved" 28 "Reserved" 27 "Reserved" 26 "Reserved" 25 "Reserved" 24 "Possible value selected is 240" 23 "Possible value selected is 230" 22 "Possible value selected is 220" 21 "Possible value selected is 210" 20 "Possible value selected is 200" 19 "Possible value selected is 190" 18 "Possible value selected is 180" 17 "Possible value selected is 170" 16 "Possible value selected is 160" 15 "Possible value selected is 150" 14 "Possible value selected is 140" 13 "Possible value selected is 130" 12 "Possible value selected is 120" 11 "Possible value selected is 110" 10 "Possible value selected is 100" 9 "Possible value selected is 90" 8 "Possible value selected is 80" 7 "Possible value selected is 70" 6 "Possible value selected is 60" 5 "Possible value selected is 50" 4 "Possible value selected is 40" 3 "Possible value selected is 30" 2 "Possible value selected is 20" 1 "Possible value selected is 10" 0 "Possible value selected is 0" ;
VAL_ 506 HuDRLActiveSignalVal 1 "Active value for DRL feature is Enabled" 0 "Active value for DRL feature is Disabled" ;
VAL_ 506 HuQueryInfo 3 "HU query to BCM for sending UCS data" 2 "HU sends user intervened data to BCM" 1 "HU Acknowledges the UCS data sent by BCM." 0 "Reserved" ;
VAL_ 506 HuApproachLampSignalVal2 31 "Reserved" 30 "Reserved" 29 "Reserved" 28 "Reserved" 27 "Reserved" 26 "Reserved" 25 "Reserved" 24 "Possible value selected is 240" 23 "Possible value selected is 230" 22 "Possible value selected is 220" 21 "Possible value selected is 210" 20 "Possible value selected is 200" 19 "Possible value selected is 190" 18 "Possible value selected is 180" 17 "Possible value selected is 170" 16 "Possible value selected is 160" 15 "Possible value selected is 150" 14 "Possible value selected is 140" 13 "Possible value selected is 130" 12 "Possible value selected is 120" 11 "Possible value selected is 110" 10 "Possible value selected is 100" 9 "Possible value selected is 90" 8 "Possible value selected is 80" 7 "Possible value selected is 70" 6 "Possible value selected is 60" 5 "Possible value selected is 50" 4 "Possible value selected is 40" 3 "Possible value selected is 30" 2 "Possible value selected is 20" 1 "Possible value selected is 10" 0 "Possible value selected is 0" ;
VAL_ 506 HuApproachLampSignalVal3 31 "Reserved" 30 "Reserved" 29 "Reserved" 28 "Reserved" 27 "Reserved" 26 "Reserved" 25 "Reserved" 24 "Possible value selected is 240" 23 "Possible value selected is 230" 22 "Possible value selected is 220" 21 "Possible value selected is 210" 20 "Possible value selected is 200" 19 "Possible value selected is 190" 18 "Possible value selected is 180" 17 "Possible value selected is 170" 16 "Possible value selected is 160" 15 "Possible value selected is 150" 14 "Possible value selected is 140" 13 "Possible value selected is 130" 12 "Possible value selected is 120" 11 "Possible value selected is 110" 10 "Possible value selected is 100" 9 "Possible value selected is 90" 8 "Possible value selected is 80" 7 "Possible value selected is 70" 6 "Possible value selected is 60" 5 "Possible value selected is 50" 4 "Possible value selected is 40" 3 "Possible value selected is 30" 2 "Possible value selected is 20" 1 "Possible value selected is 10" 0 "Possible value selected is 0" ;
VAL_ 508 HuMoodLightAllAreaActiveValue 1 "ON" 0 "OFF" ;
VAL_ 508 HuMoodLightIllumSelActiveValue 7 "Reserved" 6 "Reserved" 5 "Level 5 Intensity" 4 "Level 4 Intensity" 3 "Level 3 Intensity" 2 "Level 2 Intensity" 1 "Level 1 Intensity" 0 "Reserved" ;
VAL_ 508 HuMoodLightActiveColourValue 15 "Cyan Blue" 14 "Teal Green" 13 "French Lime" 12 "Gold Yellow" 11 "Tuscan Red" 10 "Aero Blue" 9 "Hot Magenta" 8 "Purple Taupe" 7 "Ruby (Red)" 6 "Fluorescent Green" 5 "Orange" 4 "Purple" 3 "Ivory (Off White)" 2 "Polar(Bright White)" 1 "Cool Blue" 0 "Ice Blue" ;
VAL_ 508 HuMoodLightRearAreaActiveValue 1 "ON" 0 "OFF" ;
VAL_ 508 HuMoodLightFrontRHAreaActiveValu 1 "ON" 0 "OFF" ;
VAL_ 508 HuMoodLightFloorConsoleAreaActiv 1 "ON" 0 "OFF" ;
VAL_ 508 HuMoodLightData 3 "Reserved" 2 "HU sends Mood Light data to BCM" 1 "HU Acknowledges the Mood Light data sent by BCM" 0 "Reserved" ;
VAL_ 508 HuMoodLightIllumPossibleLevels 7 "Reserved" 6 "Reserved" 5 "Intensity5" 4 "Intensity4" 3 "Intensity3" 2 "Intensity2" 1 "Intensity1" 0 "Reserved" ;
VAL_ 508 HuMoodLightHotMagentaColorSelOnH 1 "Present" 0 "Not Present" ;
VAL_ 508 HuMoodLightGoldYellowColorSelOnH 1 "Present" 0 "Not Present" ;
VAL_ 508 HuMoodLightFrenchLimeColorSelOnH 1 "Present" 0 "Not Present" ;
VAL_ 508 HuMoodLightFrontLHAreaActiveValu 1 "ON" 0 "OFF" ;
VAL_ 508 HuMoodLightPossibleModes 3 "AUTO, OFF, ON" 2 "OFF, ON" 1 "No Mode selection" 0 "Reserved" ;
VAL_ 508 HuMoodLightActiveModeValue 3 "Reserved" 2 "ON" 1 "OFF" 0 "AUTO" ;
VAL_ 508 HuMoodLightPolarBrightWhiteColor 1 "Present" 0 "Not Present" ;
VAL_ 508 HuMoodLightAeroBlueColorSelOnHU 1 "Present" 0 "Not Present" ;
VAL_ 508 HuMoodLightPurpleColorSelOnHU 1 "Present" 0 "Not Present" ;
VAL_ 508 HuMoodLightFluorescentGreenColor 1 "Present" 0 "Not Present" ;
VAL_ 508 HuMoodLightCyanBlueColorSelOnHU 1 "Present" 0 "Not Present" ;
VAL_ 508 HuMoodLightCoolBlueColorSelOnHU 1 "Present" 0 "Not Present" ;
VAL_ 508 HuMoodLightIvoryOFFWhiteColorSel 1 "Present" 0 "Not Present" ;
VAL_ 508 HuMoodLightIceBlueColorSelOnHU 1 "Present" 0 "Not Present" ;
VAL_ 508 HuMoodLightTuscanRedColorSelOnHU 1 "Present" 0 "Not Present" ;
VAL_ 508 HuMoodLightTealGreenColorSelOnHU 1 "Present" 0 "Not Present" ;
VAL_ 508 HuMoodLightRubyRedColorSelOnHU 1 "Present" 0 "Not Present" ;
VAL_ 508 HuMoodLightOrangeColorSelOnHU 1 "Present" 0 "Not Present" ;
VAL_ 508 HuMoodLightPurpleTaupeSelOnHU 1 "Present" 0 "Not Present" ;
VAL_ 509 BCmAmbLightModeSelActiveVal 3 "Reserved for future use." 2 "ON mode" 1 "OFF mode" 0 "Auto mode" ;
VAL_ 509 BCmAmbLightIllumSelActiveVal 7 "Reserved for future use." 6 "Reserved for future use." 5 "Level 5 Intensity" 4 "Level 4 Intensity" 3 "Level 3 Intensity" 2 "Level 2 Intensity" 1 "Level 1 Intensity" 0 "Reserved for future use." ;
VAL_ 509 AmbLightIllumPossibleLevels 7 "Reserved for future use." 6 "Reserved for future use." 5 "Intensity is varied in 5 levels" 4 "Intensity is varied in 4 levels" 3 "Intensity is varied in 3 levels" 2 "Intensity is varied in 2 levels" 1 "No Intensity variation possible. " 0 "Reserved for future use." ;
VAL_ 509 AmbLightModeIllumOnHu 1 "Mode and Illumination Display is Enabled" 0 "Mode and Illumination Display is Disabled" ;
VAL_ 509 BCmAmbLightData 3 "Reserved" 2 "BCM sends ambient light data to HU" 1 "BCM Acknowledges the Ambient light data sent by HU" 0 "Reserved" ;
VAL_ 510 HuAmbLightModeSelActiveVal 3 "reserve for future use" 2 "ON mode" 1 "OFF mode" 0 "Auto mode" ;
VAL_ 510 HuAmbLightIllumSelActiveVal 7 "Reserved for future use." 6 "Reserved for future use." 5 "Level 5 Intensity" 4 "Level 4 Intensity" 3 "Level 3 Intensity" 2 "Level 2 Intensity" 1 "Level 1 Intensity" 0 "Reserved for future use." ;
VAL_ 510 HuAmbLightIllumPossibleLevels 7 "Reserved for future use." 6 "Reserved for future use." 5 "Intensity 5" 4 "Intensity 4" 3 "Intensity 3" 2 " Intensity 2 " 1 " Intensity 1" 0 "Reserved for future use." ;
VAL_ 510 HuAmbLightData 3 "Reserved" 2 "HU sends ambient  light user changed data changed to BCM" 1 "Hu Ackknowledges the  Ambient light data send by BCM" 0 "Reserved" ;
VAL_ 571 ColorThemeAutolearning 1 "Feature present" 0 "Feature not present" ;
VAL_ 571 ColorThemeCoDrvr 7 "color 8" 6 "color 7" 5 "color 6" 4 "color 5" 3 "color 4" 2 "color 3" 1 "color 2" 0 "color 1" ;
VAL_ 571 ColorThemeDrvr 7 "color 8" 6 "color 7" 5 "color 6" 4 "color 5" 3 "color 4" 2 "color 3" 1 "color 2" 0 "color 1" ;
VAL_ 571 CcmHuRearBlwrOnOffState 1 "Rear Blower ON" 0 "Rear Blower OFF" ;
VAL_ 571 CcmHuUserInterventionBeep 1 "Beep" 0 "No Beep" ;
VAL_ 571 AutoDefogState 3 "Reserved" 2 "Active" 1 "Monitoring" 0 "Inactive" ;
VAL_ 571 AutoDefogFeature 1 "Feature present" 0 "Feature not present" ;
VAL_ 571 CCmExpressCoolVoiceAlert 7 "Reserved" 6 "Low Ambient Temperature / Its Already Cold Outside" 5 "Roll Up the windows if down" 4 "Express Cooling OFF, Roll Up the windows if DOWN" 3 "Express Cooling ON windows may roll DOWN" 2 "Express Cooling OFF" 1 "Express Cooling ON" 0 "No Request" ;
VAL_ 571 CCmHuExpressCoolSwitchStatus 1 "Express Cool feature ON" 0 "Express Cool feature OFF" ;
VAL_ 571 CCmWindowUpDown 3 "Reserved" 2 "Window Down Request" 1 "Window Up Request" 0 "No Request" ;
VAL_ 571 CCmHuFanSpdStatus 15 "Reserved" 14 "Reserved" 13 "Reserved" 12 "Reserved" 11 "Reserved" 10 "Reserved" 9 "Reserved" 8 "Reserved" 7 "Speed 7" 6 "Speed 6" 5 "Speed 5" 4 "Speed 4" 3 "Speed 3" 2 "Speed 2" 1 "Speed 1" 0 "Speed 0 ( only for FATC dual ) / Reserved (ETC & FATC Single zone)" ;
VAL_ 571 CCmHuDistribSwitchStatus 7 "Reserved" 6 "Reserved" 5 "DefrostMode Status
" 4 "LegDefrostMode Status" 3 "LegMode Status" 2 "Chest-LegMode Status" 1 "ChestModeStatus" 0 "Reserved" ;
VAL_ 571 CCmHuDualModeSwStatus 1 "Dual Mode ON" 0 "Dual Mode OFF" ;
VAL_ 571 CCmHuTempWhlStatusPass 31 "HI" 30 "Reserved" 29 "30 Deg C" 28 "29.5 Deg C" 27 "29 Deg C" 26 "28.5 Deg C" 25 "28 Deg C" 24 "27.5 Deg C" 23 "27 Deg C" 22 "26.5 Deg C" 21 "26 Deg C" 20 "25.5 Deg C" 19 "25 Deg C" 18 "24.5 Deg C" 17 "24 Deg C" 16 "23.5 Deg C" 15 "23 Deg C" 14 "22.5 Deg C" 13 "22 Deg C" 12 "21.5 Deg C" 11 "21 Deg C" 10 "20.5 Deg C" 9 "20 Deg C" 8 "19.5 Deg C" 7 "19 Deg C" 6 "18.5 Deg C" 5 "18 Deg C" 4 "17.5 Deg C" 3 "17 Deg C" 2 "16.5 Deg C" 1 "16 Deg C" 0 "LO" ;
VAL_ 571 CCMHuFreshAirRecircSwitchStatus 3 "Reserved" 2 "Fresh Air ON" 1 "Recirculation with AQS (applicable for dual zone FATC)" 0 "Recirculation ON" ;
VAL_ 571 CCmHuAutoSwitchStatus 1 "Auto is ON" 0 "Auto is OFF" ;
VAL_ 571 CCmHuTempWhlStatus 31 "HI" 30 "Reserved" 29 "30 Deg C" 28 "29.5 Deg C" 27 "29 Deg C" 26 "28.5 Deg C" 25 "28 Deg C" 24 "27.5 Deg C" 23 "27 Deg C" 22 "26.5 Deg C" 21 "26 Deg C" 20 "25.5 Deg C" 19 "25 Deg C" 18 "24.5 Deg C" 17 "24 Deg C" 16 "23.5 Deg C" 15 "23 Deg C" 14 "22.5 Deg C" 13 "22 Deg C" 12 "21.5 Deg C" 11 "21 Deg C" 10 "20.5 Deg C" 9 "20 Deg C" 8 "19.5 Deg C" 7 "19 Deg C" 6 "18.5 Deg C" 5 "18 Deg C" 4 "17.5 Deg C" 3 "17 Deg C" 2 "16.5 Deg C" 1 "16 Deg C" 0 "LO" ;
VAL_ 571 CCmHuEconModeSwitchStatus 1 "Economy is ON" 0 "Economy is OFF" ;
VAL_ 571 CCmHuMaxDefrstSwitchStatus 1 "Max defrost ON" 0 "Max defrost OFF" ;
VAL_ 571 CCmHuRearDefogSwitchStatus 1 "Rear defog is ON" 0 "Rear defog is OFF" ;
VAL_ 571 CCmHuTempWhlStatusDrvr 31 "HI" 30 "Reserved" 29 "30 Deg C" 28 "29.5 Deg C" 27 "29 Deg C" 26 "28.5 Deg C" 25 "28 Deg C" 24 "27.5 Deg C" 23 "27 Deg C" 22 "26.5 Deg C" 21 "26 Deg C" 20 "25.5 Deg C" 19 "25 Deg C" 18 "24.5 Deg C" 17 "24 Deg C" 16 "23.5 Deg C" 15 "23 Deg C" 14 "22.5 Deg C" 13 "22 Deg C" 12 "21.5 Deg C" 11 "21 Deg C" 10 "20.5 Deg C" 9 "20 Deg C" 8 "19.5 Deg C" 7 "19 Deg C" 6 "18.5 Deg C" 5 "18 Deg C" 4 "17.5 Deg C" 3 "17 Deg C" 2 "16.5 Deg C" 1 "16 Deg C" 0 "LO" ;
VAL_ 571 CCmHuAirConCompSwitchStatus 1 "AC is ON" 0 "AC is OFF" ;
VAL_ 571 CCmHuCtrlPnlStatus 1 "Control Panel ON" 0 "Control Panel OFF" ;
VAL_ 571 CCmHuChangeBit 1 "Change bit OFF" 0 "Change bit ON" ;
VAL_ 571 CCmHuUserInterventionStatusFlag 31 "Reserved" 30 "Reserved" 29 "Reserved" 28 "Reserved" 27 "Reserved" 26 "Reserved" 25 "Reserved" 24 "Reserved" 23 "Reserved" 22 "Reserved" 21 "Reserved" 20 "Reserved" 19 "Reserved" 18 "Autodefog User Intervention flag " 17 "Rear Blower Flag" 16 "FL Seat Ventilation Flag" 15 "FR Seat Ventilation Flag" 14 "Express Cool Flag" 13 "Rear defog Flag" 12 "Temperature Wheel  flag" 11 "Dual button flag" 10 "Fan speed wheel flag" 9 "Temperature Wheel driver flag" 8 "Temperature Wheel Passenger flag" 7 "Distribution button flag" 6 "Recirculation button flag" 5 "Maxdefrost button flag" 4 "Off button flag" 3 "Auto button flag" 2 "Econ button flag" 1 "AC Button flag" 0 "CCmHuUserInterventionStatusFlagClear" ;
VAL_ 571 CCmHuTempWhlStatusStatus 3 "Signal not available" 2 "Reserved for future" 1 "Reserved for future" 0 "Plausible " ;
VAL_ 571 CCmHuErrStatus 1 "CCM Error" 0 "CCM fully available " ;
VAL_ 571 CCmHuDualModeSwStatusStatus 3 "Signal not available" 2 "Value is implausible " 1 "Reserved for future" 0 "Value is correct" ;
VAL_ 571 CCmHuTempWhlStatusPassStatus 3 "Signal not available" 2 "Reserved for future" 1 "Reserved for future" 0 "Plausible" ;
VAL_ 571 CCmHuTempWhlStatusDrvrStatus 3 "Signal not available" 2 "Reserved for future" 1 "Reserved for future" 0 "Plausible  " ;
VAL_ 573 LockStateESCL 1 "ESCL is locked" 0 "ESCL is not locked" ;
VAL_ 573 UnlockStateESCL 1 "ESCL is unlocked" 0 "ESCL is not unlocked" ;
VAL_ 573 ESClTextRotateSteeringWheel 1 "Steering wheel is blocked" 0 "Steering wheel isn't blocked" ;
VAL_ 573 ESClTextDefect 1 "Defect failure detected" 0 "No defect failure detected" ;
VAL_ 573 ESClTextGarage 1 "functional failure detected" 0 "functional failure not detected" ;
VAL_ 614 ModeSelectionSwStateStatus 3 "Signal is not availalbe" 2 "Information given is implausible" 1 "Reserved" 0 "Information given is correct and according to specification" ;
VAL_ 614 ModeSelectionSwState 7 "Reserved" 6 "Reserved" 5 "Reserved" 4 "Reserved" 3 "Off Road Mode" 2 "Economy Mode" 1 "Sports Mode" 0 "Normal Mode" ;
VAL_ 616 ModeSelectionSwStateStatusNew 3 "Signal is not availalbe" 2 "Information given is implausible" 1 "Reserved" 0 "Information given is correct and according to specification" ;
VAL_ 616 ModeSelectionSwStateNew 15 "Engine mode active" 14 "Reserved" 13 "Reserved" 12 "Reserved" 11 "Reserved" 10 "Reserved" 9 "Reserved" 8 "Reserved" 7 "Reserved" 6 "Reserved" 5 "Rough Road Mode" 4 "Wet/Rain" 3 "Sand" 2 "Mud / Ruts / Gravel" 1 "Grass / Snow" 0 "Normal Drive" ;
VAL_ 638 CngTnkPresSts 3 "Reserved" 2 "Value is implausible" 1 "Reserved" 0 "Value is valid" ;
VAL_ 638 CNGSwitchState 1 "CNG mode selector switch in is CNG mode" 0 "CNG mode selector switch in is Gasoline mode" ;
VAL_ 638 EngFuelMode 1 "Current fuel mode of engine is CNG" 0 "Current fuel mode of engine is Gasoline" ;
VAL_ 638 CngErrMsgUserInfo 7 "Reserved for future use" 6 "Reserved for future use" 5 "Reserved for future use" 4 "Reserved for future use" 3 "Engine Misfire, visit dealer ASAP" 2 "Leakage in CNG system, visit dealer ASAP" 1 "CNG Fuel LID Open, close to start engine" 0 "CNG Comp. Fault, Petrol mode active" ;
VAL_ 638 CngStatus 7 "Not supported / Signal Not available" 6 "Resrved for future use" 5 "Resrved for future use" 4 "Resrved for future use" 3 "CNG lamp is ON" 2 "CNG tell tale lamp is blinking @ 0.1Hz" 1 "CNG tell tale lamp is blinking @ 0.5Hz" 0 "CNG  tell tale lamp is Off" ;
VAL_ 638 CngFuelLevelStatus 3 "FuelLvlCng Signal not available" 2 "FuelLvlCng signal value is implausible" 1 "Resrved for future use" 0 "Information given by FuelLvlCng is correct and according to specification" ;
VAL_ 638 FuelConsCngStatus 3 "Signal is not available" 2 "Information given  is implausible" 1 "Reserved for future use" 0 "FuelCons Information given is correct and according to specification" ;
VAL_ 640 EngCrsCntrlModeNew 15 "Signal Not available" 14 "Reserved" 13 "Reserved" 12 "Reserved" 11 "Cruise Inhibit" 10 "Cruise Override" 9 "Short Tap of Cruise Set/ Tap Down" 8 "Short Tap of Cruise Resume/ Tap Up" 7 "Cruise Resume" 6 "Cruise Decel" 5 "Cruise Accel" 4 "Cruise Active" 1 "Cruise Off" 0 "No display /Blank Display " 3 "Cruise InActive" 2 "Cruise ON" ;
VAL_ 640 EngSpd_EMS_Status 3 "Reserved for future use" 2 "Value is implausible" 1 "Reserved for future use" 0 "EngSpd signal is correct" ;
VAL_ 640 EngineOilPrLamp 3 "Reserved for future use" 2 "Engine Oil Pressure Lamp is Flashing" 1 "Engine Oil Pressure Lamp is ON" 0 "Engine Oil Pressure Lamp is Off" ;
VAL_ 640 FilterClLamp 3 "Not Supported or Signal not available" 2 "Fuel Filter Clogged Lamp is Flashing" 1 "Fuel Filter Clogged Lamp is ON" 0 "Fuel Filter Clogged Lamp is Off" ;
VAL_ 640 BattChrgLampStatus 3 "Signal not available" 2 "Value is implausible" 1 "Reserved" 0 "Value is plausible" ;
VAL_ 640 ClntTempStatus 3 "Reserved for future use" 2 "Value is implausible" 1 "Reserved for future use" 0 "ClntTemp signal is correct" ;
VAL_ 640 GlowPlugLampState 3 "Not applicable or  Not supported " 2 "Glow plug lamp is ON" 1 "Glow plug lamp is Flashing" 0 "Glow plug lamp is Off" ;
VAL_ 640 EngineOilPrLampStatus 3 "Signal not available" 2 "Value is implausible" 1 "Reserved" 0 "Value is plausible" ;
VAL_ 640 WIfLampState 3 "Water Fuel Sensor Failure" 2 "WIF lamp flashing" 1 "WIF lamp is ON" 0 "WIF lamp is Off" ;
VAL_ 640 ECmBackdoormode 3 "Signal not available" 2 "Reserved for future use " 1 "Backdoor Entry Inactive" 0 "Backdoor Entry Active" ;
VAL_ 640 FuelConsStatus 3 "Signal not available" 2 "Value is implausible" 1 "Reserved for future use" 0 "FuelCons is correct" ;
VAL_ 640 BattChrgLampState 3 "Reserved for future use" 2 "Battery charge lamp is ON" 1 "Battery charge lamp is flashing" 0 "Battery charge lamp is Off" ;
VAL_ 640 DPfState 3 "Not applicable or  Not supported" 2 "DPF lamp is ON" 1 "DPF lamp is flashing" 0 "DPF lamp is Off" ;
VAL_ 640 ClntTempHigh 3 "Reserved for future use" 2 "Engine coolant temp high ON" 1 "Engine coolant temp high Flashing" 0 "Engine coolant temp high OFF(Temp within limit)" ;
VAL_ 640 ImmoStatus 1 "Engine is Locked" 0 "Engine is Unlocked" ;
VAL_ 640 MiLampState 3 "Reserved for future use" 2 "MIL/Service lamp is ON" 1 "MIL/Service lamp is Flashing" 0 "MIL/Service lamp is Off" ;
VAL_ 643 CruiseDispStatus 3 "Signal Not available" 2 "Value is implausible" 1 "Reserved for future use" 0 "Value is correct and according to specification" ;
VAL_ 643 CruiseDisp 15 "Reserved" 14 "Reserved" 13 "Reserved" 12 "Unable to Activate Cruise" 11 "Short Tap of Set / -" 10 "Short Tap of Set /+" 9 "Unable to Resume Cruise" 8 "Cruise Override" 7 "Cruise Decel" 6 "Cruise Activated" 5 "Cruise Accel" 4 "Cruise Resume" 3 "Cruise Cancelled" 2 "Cruise OFF" 1 "Cruise ON" 0 "No Display" ;
VAL_ 643 BattChrgStatus 1 "Battery Not Charging" 0 "Battery Charging" ;
VAL_ 643 BattWrkZone 1 "Battery not in work zone and need to charge" 0 "Battery is in work zone		

" ;
VAL_ 643 BattAutoStopStatus 3 "Reserved for future use" 2 "Auto Stop Forbidden" 1 "Auto stop available" 0 "Auto stop not available" ;
VAL_ 644 AcCmprOverPrStatus 3 "Signal not available" 2 "Signal is implausible" 1 "Reserved for future use" 0 "ACCmprOverPr_Active is correct" ;
VAL_ 644 AcCmprPrStatus 3 "Signal not available" 2 "ACCmprPr is implausible" 1 "Reserved for future use" 0 "ACCmprPr is correct" ;
VAL_ 644 EngEmission 7 "Euro 6" 6 "Bharat Stage 6" 5 "Euro 5" 4 "Bharat Stage 5" 3 "Euro 4" 2 "Bharat Stage 4" 1 "Euro 3" 0 "Bharat Stage 3" ;
VAL_ 644 TxmnVariant 3 "Reserved for future use" 2 "Automatic Txmn" 1 "Automated Manual Txmn" 0 "Manual Txmn" ;
VAL_ 644 AcCmprStatus 1 "AC Compressor is On" 0 "AC Compressor is Off" ;
VAL_ 644 RadFanStatus 1 "Radiator FAN is On" 0 "Radiator FAN is Off" ;
VAL_ 644 AcCmprOverPrActive 1 "over-pressure detected" 0 "over-pressure not detected" ;
VAL_ 644 EMSInitDrvModeConfig 7 "Reserved" 6 "Reserved" 5 "Previous Ignition Cycle City Mode" 4 "Previous Ignition Cycle Sport Mode" 3 "Previous Ignition Cycle Economy Mode" 2 "Normal / City Mode" 1 "Sport Mode" 0 "Economy Mode" ;
VAL_ 644 BattVoltEMsStatus 3 "Reserved" 2 "Value is implausible" 1 "Reserved" 0 "Value is plausible" ;
VAL_ 644 EngLimpHomeMode 7 "Reserved for future use" 6 "Reserved for future use" 5 "Reserved for future use" 4 "Reserved for future use" 3 "Reserved for future use" 2 "Engine Torque limitation active" 1 "Engine Speed limitation active " 0 "Engine is working normal" ;
VAL_ 644 AtmospPrStatus 3 "Signal not available" 2 "Value is implausible" 1 "Reserved" 0 "Value is plausible" ;
VAL_ 644 AcCmprUnderPrActive 1 "Under pressure detected" 0 "Under pressure not detected" ;
VAL_ 644 AcCmprUnderPrStatus 3 "Reserved for future use" 2 "Value is implausible" 1 "Reserved for future use" 0 "Information given is correct" ;
VAL_ 644 EngVariant 3 "Signal not available" 2 "BiFuel" 1 "Diesel engine" 0 "Petrol engine" ;
VAL_ 644 ModeChangeTxtEMS 3 "Reserved" 2 "Drive Mode selection not possible due to function failure" 1 "Drive Mode selection not possible" 0 "Drive Mode selection Possible" ;
VAL_ 644 EngCrsCntrlMode 7 "Cruise off" 6 "Tap - (Short Press of Set Switch when Cruise is Active)" 5 "Tap - Short Press of Resume when Cruise is Active)" 4 "Cruise Decel" 3 "Cruise Accel" 2 "Cruise Resume" 1 "Cruise Active" 0 "Cruise Not Active" ;
VAL_ 645 IACOpModes 7 "Not supported /Signal Not available" 6 "Reserved" 5 "Reserved" 4 "Energy Recuperation Mode  Initiated" 3 "Alternator Shoutdown Mode Initiated" 2 "Energy Recuperation Mode" 1 "Alternator Shoutdown  Mode" 0 "Normal alternator Mode (Charging Function)" ;
VAL_ 646 UserSpdLimLamp 1 "UserSpdLimLamp is active" 0 "UserSpdLimLamp is not active" ;
VAL_ 646 UserSpdLimFault 3 "other subsystem fault (engine fault)" 2 "Speed limiter regulation fault" 1 "Speed limiter input switch fault" 0 "No Fault detected" ;
VAL_ 646 UserSpdLimStatus 3 "Signal not available" 2 "Signal is Implausible" 1 "Reserved for future use" 0 "Signal is correct" ;
VAL_ 646 EngStatus 7 "Reserved for future" 6 "Reserved for future" 5 "Engine stalled" 4 "Engine ready to crank" 3 "Engine running" 2 "Engine running at idle speed" 1 "Engine cranking in progress" 0 "Engine not running/Ignition ON" ;
VAL_ 646 CeLampState 3 "Not supported or Signal not available" 2 "Check engine /Service lamp Flashing" 1 "Check engine /Service lamp is ON" 0 "Check engine /Service lamp is Off" ;
VAL_ 646 StaterProhibitionDelay 1 "Prohibition delay is  active" 0 "Prohibition delay is not active" ;
VAL_ 646 StarterControlState 3 "Starter function  fault-Stalled starter" 2 "Starter function fault-Relay" 1 "Starter switched OFF by EMS" 0 "Starter switched ON by EMS" ;
VAL_ 646 UserSpdLimState 3 "Temporary override" 2 "Speed limter active" 1 "Speed limiter enabled" 0 "Speed limiter disabled" ;
VAL_ 646 SFCActiveEMS 3 "Function not present" 2 "Reserved for future use " 1 "SFC fucntion is  active" 0 "SFC fucntion is  disabled" ;
VAL_ 646 DrvModeIndctnEMSstatus 3 "Signal not available" 2 "Signal is Implausible" 1 "Reserved for future use" 0 "Signal is correct" ;
VAL_ 646 CruiseSpdLamp 3 "Not applicable or  Not supported" 2 "Temporary override" 1 "Cruise Lamp is Active" 0 "Cruise Lamp is Not active" ;
VAL_ 646 StarterControlStatus 3 "Signal not available" 2 "Signal is Implausible" 1 "Reserved for future use" 0 "Signal is correct" ;
VAL_ 646 CurrGearEms 15 "Reserved" 14 "Reserved" 13 "Reserved" 12 "Reserved" 11 "Reserved" 10 "Reserved" 9 "Reserved" 8 "Reverse Gear" 7 "Sixth Gear" 6 "Fifth Gear" 5 "Fourth Gear" 4 "Third Gear" 3 "Second Gear" 2 "First Gear" 1 "No gear engaged/ neutral" 0 "Invalid Gear" ;
VAL_ 646 CruiseSpdFault 3 "other subsystem fault" 2 "Cruise regulation fault" 1 "Cruise input switch fault" 0 "Value is correct" ;
VAL_ 646 CruiseSpdStatus 3 "Signal not available" 2 "Signal is Implausible" 1 "Reserved for future use" 0 "Signal is correct" ;
VAL_ 646 CurrGearEmsStatus 3 "Signal not available" 2 "Value is implausible" 1 "Reserved" 0 "Signal is plausible" ;
VAL_ 646 GearShiftIndctnEmsStatus 3 "Signal not available" 2 "Signal is Implausible" 1 "Reserved for future use" 0 "Signal is correct" ;
VAL_ 646 GearShiftIndctnEms 7 "Signal Not available" 6 "Reserved for future use" 5 "Reserved for future use" 4 "Reserved for future use" 3 "Reserved for future use" 2 "Shift Gear Up" 1 "Shift Gear Down" 0 "GearShift OK" ;
VAL_ 646 CruiseSwitchstate 3 "Invalid Key Pressed" 2 "Set / Cruise Spd - Key pressed" 1 "Resume / Cruise Spd+ Key pressed" 0 "No Key ( Resume/Cruise Speed+  && Set/Cruise Speed - ) pressed" ;
VAL_ 646 CruiseSwitchstateStatus 3 "Signal not available" 2 "Value is implausible " 1 "Reserved for future use" 0 "Signal is correct" ;
VAL_ 646 DrvModeIndctnEMS 15 "Reserved" 14 "Reserved" 13 "Reserved" 12 "Reserved" 11 "Tiptronic Rough Mode" 10 "Automatic Rough Mode" 9 "Manual Rough Mode" 8 "Tiptronic Economy Mode" 7 "Tiptronic Sport Mode" 6 "Tiptronic Normal / City Mode" 5 "Automatic Economy Mode" 4 "Automatic Sport Mode" 3 "Automatic Normal / City" 2 "Manual Economy Mode" 1 "Manual Sport Mode" 0 "Manual Normal / City Mode" ;
VAL_ 647 EMSRemoteCheckStatus 3 "Signal not available" 2 "Signal is implausible" 1 "Reserved for future use." 0 "Signal is correct" ;
VAL_ 647 EMSRemoteCheck 3 "Engine Off due to abuse cases/Failure State" 2 "Remote Check Not Successful" 1 "Remote Check Successful" 0 "Default State" ;
VAL_ 647 ModeChangeTxtEMSNew 3 "Reserved" 2 "Engine & Terrain mode (if applicable) selection not possible due to function failure in EMS or ABS/ESP or TOD or Mode selection switches" 1 "Engine & Terrain mode (if applicable) selection not possible due to mode transition is in progress or Initialization in progress or verification & validation in progress" 0 "Engine or Terrain or Both (Engine & Terrain) modes selection possible" ;
VAL_ 647 DrvModeIndctnEMSNew 15 "Reserved" 14 "Reserved" 13 "Reserved" 12 "Reserved" 11 "Reserved" 10 "Reserved" 9 "Reserved" 8 "Reserved" 7 "Rough Road" 6 "Wet/Rain" 5 "Sand" 4 "Mud / Ruts/ Gravel" 3 "Grass / Snow" 2 "Economy " 1 "Sport" 0 "Normal / City" ;
VAL_ 647 DrvModeIndctnEMSstatusNew 3 "Signal not available" 2 "Signal is Implausible" 1 "Reserved for future use" 0 "Signal is correct" ;
VAL_ 647 EngageParkOrNeutral 1 "Engage P or N for Starting" 0 "No Action for driver" ;
VAL_ 647 BrkPedalLamp 1 "Brake Pedal Lamp On" 0 "Brake Pedal Lamp Off" ;
VAL_ 647 OBDWrmUpCycleStatus 1 "OBD Warm Up Cycle Active" 0 "OBD Warm Up Cycle Inactive" ;
VAL_ 647 OBDDrvCycleStatus 1 "OBD Driving Cycle Active" 0 "OBD Driving Cycle Inactive" ;
VAL_ 647 PressClutToStart 1 "Press Clutch fully or perform emergency start" 0 "No Action from User" ;
VAL_ 647 CrsResumeInh 1 "Cruise Resume Operation Inhibited" 0 "Cruise Resume Operation not Inhibited" ;
VAL_ 647 RegntRemainDist 16533 "Signal Not Available" ;
VAL_ 647 SmartAltState 15 "SNA" 14 "Reserved" 13 "Reserved" 12 "Reserved" 11 "Battery regeneration" 10 "Normal Production/Recovery mode" 9 "Shut off" 8 "Auto shut off" 7 "Quick charge" 6 "Regenerative braking" 5 "Steady state" 4 "Passive boost" 3 "Cold engine" 2 "Cranking phase" 1 "Engine OFF" 0 "OFF" ;
VAL_ 647 RegntLevel 127 "Signal not available" ;
VAL_ 648 ESSIACSystemAvailable 3 "ESS-IAC System available" 2 "IAC System available" 1 "ESS System available" 0 "ESS-IAC System not available" ;
VAL_ 648 ESSAutoStartStopActSt 7 "Not supported /Signal Not available" 6 "Reserved for future use" 5 "Auto stop Denied" 4 "Auto start Denied" 3 "Autonomous Start activated" 2 "Auto Stop Activated" 1 "Auto Start Activated" 0 "Normal condition" ;
VAL_ 648 ESSDisableSwitchStatus 3 "Signal is not available" 2 "Signal value is implausible" 1 "Reserved" 0 "Signal value is plausible" ;
VAL_ 648 ESSDisableSwitchState 1 "ESS Function disabled " 0 "ESS Function enabled " ;
VAL_ 648 ESSAutoStartLamp 7 "Not supported / Signal Not available" 6 "Reserved for future use" 5 "Reserved for future use" 4 "Reserved for future use" 3 "ESS Auto start tell tale lamp ON" 2 "ESS Auto start tell tale lamp is blinking @ 0.1Hz" 1 "ESS Auto start tell tale lamp is blinking @ 0.5Hz" 0 "ESS Auto start tell tale lamp OFF" ;
VAL_ 648 ESSAutoStopLamp 7 "Not supported / Signal Not available " 6 "Reserved for future use" 5 "Reserved for future use" 4 "Reserved for future use" 3 "ESS Auto stop tell tale lamp ON" 2 "ESS Auto stop tell tale lamp is blinking @ 0.1Hz" 1 "ESS Auto stop tell tale lamp is blinking @ 0.5Hz" 0 "ESS Auto stop tell tale lamp OFF" ;
VAL_ 648 ESSTextMsg 7 "Not supported /Signal Not available" 6 "Reserved for future use" 5 "Display Text messgae on IC as  ''Manual Crank Immediately''" 4 "Display Text messgae on IC as ''Manual Crank''" 3 "Display Text messgae on IC as ''ESS ON''" 2 "Display Text messgae on IC as ''ESS Auto Start''" 1 "Display Text messgae on IC as  ''ESS Fault''" 0 "Display Text messgae on IC as ''ESS OFF''" ;
VAL_ 648 ESSLamp 7 "Not supported / Signal Not available " 6 "Reserved for future use" 5 "Reserved for future use" 4 "Reserved for future use" 3 "ESS tell tale lamp ON" 2 "ESS tell tale lamp is blinking @ 0.1Hz" 1 "ESS tell tale lamp is blinking @ 0.5Hz" 0 "ESS tell tale lamp OFF" ;
VAL_ 649 EMsSOhIndex 3 "Reserved for future use" 2 "0%< IBSSoH  =<59%" 1 "59% < IBSSoH =<79%" 0 "IBSSoH > 79%" ;
VAL_ 649 EMsSOcIndex 3 "Reserved for future use" 2 "0%< IBSSoC  =<59%" 1 "59% < IBSSoC =<79%" 0 "IBSSoC > 79%" ;
VAL_ 649 IBsSOhSts 3 "Not Supported " 2 "Value is implausible" 1 "Reserved for future use" 0 "Value is correct and according to specification" ;
VAL_ 649 IBsSOcSts 3 "Not supported /Signal Not available" 2 "Information is Implausible" 1 "Reserved for future use" 0 "Information given is correct and according to specification" ;
VAL_ 649 IbsTempSts 3 "Not supported /Signal Not available" 2 "Information  is Implausible" 1 "Reserved for future use" 0 "Information given is correct " ;
VAL_ 649 IbsVtgSts 3 "Not supported /Signal Not available" 2 "Value is implausible" 1 "Reserved for future use" 0 "Information given is correct and according to specification" ;
VAL_ 649 IbsCurrSts 3 "Not supported /Signal Not available" 2 "Information is Implausible" 1 "Reserved for future use" 0 "Ibs Current Information given is correct and according to specification" ;
VAL_ 650 EPAsStatus 3 "Reserved " 2 "EPASNot available & Lamp ON" 1 "Reserved" 0 "EPASFullly available &Lamp Off" ;
VAL_ 651 SteerWhlTrqStatus 3 "Reserved" 2 "Steering Wheel Torque Value is implausible" 1 "Reserved" 0 "Information given by Steering Wheel Torque is correct and according to specification" ;
VAL_ 651 SAsAngEPAsDir 1 "Steering Wheel turned in the Counter clockwise direction" 0 "Steering Wheel turned in the Clockwise direction" ;
VAL_ 651 SAsAngEPASStatus 3 "Reserved" 2 "SAS angle Value is implausible" 1 "Reserved " 0 "Information given by SAS angle is correct and according to specification" ;
VAL_ 651 EPASDriverInformation 1 "Display Text Power Steering Assist Reduction" 0 "No Steering Information to be displayed" ;
VAL_ 651 EPASDriverWarning 3 "Reserved2" 2 "Reserved1" 1 "Fault Detected" 0 "No Fault Detected" ;
VAL_ 651 DrvModeIndctnEPAS 7 "Reserved" 6 "Reserved" 5 "Reserved" 4 "Reserved" 3 "Reserved" 2 "Mode 3" 1 "Mode 2" 0 "Mode 1" ;
VAL_ 651 DrvModeIndctnEPASstatus 3 "Signal Not available" 2 "Information given  is implausible" 1 "Reserved" 0 "Information given is correct and according to specification" ;
VAL_ 651 EPAsStatusGen2 3 "Reserved " 2 "EPAS Not available & Lamp ON" 1 "Reserved" 0 "EPAS Fullly available & Lamp Off" ;
VAL_ 651 EPAsAssistStatus 3 "Signal not available" 2 "No assistance" 1 "Default assistance" 0 "Full assistance" ;
VAL_ 652 SteerAngEPAsCalibration 1 "SAS is calibrated" 0 "SAS is not calibrated" ;
VAL_ 656 StuckModeAvailability 1 "Stuck Mode function is available" 0 "Stuck Mode function is not available" ;
VAL_ 656 StuckModeStateStatus 3 "Reserved" 2 "Stuck mode is implausible" 1 "Reserved" 0 "Stuck mode is plausible" ;
VAL_ 656 StuckModeState 7 "Reserved" 6 "stuck mode deactivated" 5 "stuck mode cannot help" 4 "Well Done!" 3 "Stuck mode Turned off due to high Teamprature" 2 "Stuck Mode ON" 1 "Stuck Identified by ABS" 0 "Stuck Mode OFF" ;
VAL_ 656 ModeDetectESPStatus 3 "Signal is not available" 2 "Signal value is implausible" 1 "Reserved" 0 "Signal value is correct" ;
VAL_ 656 ModeDetectESP 1 "Sports" 0 "Default" ;
VAL_ 656 WSsPulseCountFrontRHStatus 3 "Reserved" 2 "value is implausible" 1 "Reserved" 0 "Value is plausible" ;
VAL_ 656 WSsPulseCountRearLHStatus 3 "Reserved" 2 "value is implausible" 1 "Reserved" 0 "Value is plausible" ;
VAL_ 656 WSsPulseCountRearRHStatus 3 "Reserved" 2 "value is implausible" 1 "Reserved" 0 "Value is plausible" ;
VAL_ 656 WSsPulseCountFrontLHStatus 3 "Reserved" 2 "value is implausible" 1 "Reserved" 0 "Value is plausible" ;
VAL_ 656 DrvModeIndctnESPStatusNew 3 "Signal is not available" 2 "Signal is implausible" 1 "Reserved" 0 "Information given is correct and according to specification" ;
VAL_ 656 DrvModeIndctnESPNew 7 "Rough Road" 6 "Wet/Rain" 5 "Reserved" 4 "Sand" 3 "Mud / Ruts / Gravel " 2 "Grass / Snow" 1 "Sports" 0 "Normal" ;
VAL_ 660 WhlSpdFrLeftStatus 3 "Reserved for future" 2 "Information given at WhlSpdFrLeft is implausible due to a detected failure at wheel speed sensor FL" 1 "Reserved for future" 0 "Information given at WhlSpdFrLeft is correct and according to specification" ;
VAL_ 660 WhlSpdFrRightStatus 3 "Reserved for future" 2 "Information given at WhlSpdFrRight is implausible due to a detected failure at wheel speed sensor FR" 1 "Reserved for future" 0 "Information given at WhlSpdFrRight is correct and according to specification" ;
VAL_ 660 WhlSpdRrLeftStatus 3 "Reserved for future" 2 "Information given at WhlSpdRrLeft is implausible due to a detected failure at wheel speed sensor RL" 1 "Reserved for futute" 0 "Information given at WhlSpdRrLeft is correct and according to specification" ;
VAL_ 660 WhlSpdRrRightStatus 3 "Reserved for future" 2 "Information given at WhlSpdRrRight is implausible due to a detected failure at wheel speed sensor RR" 1 "Reserved for future" 0 "Information given at WhlSpdRrRight is correct and according to specification" ;
